VERSION ""

NS_ :

BS_:

BU_: VMCU TECU OBDScanT2 IC3 EMS ECUspare2 ECUspare1 DACU CIOM BBM

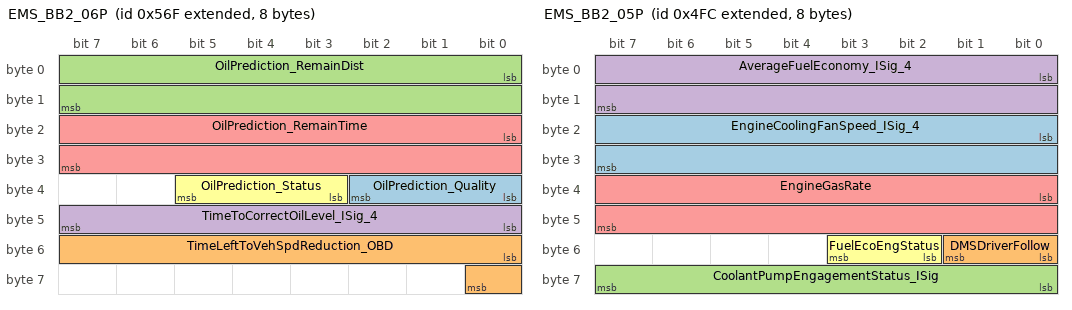
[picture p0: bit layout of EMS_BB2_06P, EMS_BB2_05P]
BO_ 2147485039 EMS_BB2_06P: 8 EMS
 SG_ OilPrediction_Quality : 32|3@1+ (1,0) [0|0] ""  CIOM,VMCU
 SG_ TimeLeftToVehSpdReduction_OBD : 48|9@1+ (15,0) [0|7665] "min"  IC3
 SG_ OilPrediction_RemainDist : 0|16@1+ (10,0) [0|655350] "km"  CIOM,VMCU
 SG_ TimeToCorrectOilLevel_ISig_4 : 40|8@1+ (1,0) [0|255] "min"  IC3
 SG_ OilPrediction_RemainTime : 16|16@1+ (1,0) [0|65535] "h"  VMCU,CIOM
 SG_ OilPrediction_Status : 35|3@1+ (1,0) [0|0] ""  CIOM,VMCU

BO_ 2147484924 EMS_BB2_05P: 8 EMS
 SG_ EngineCoolingFanSpeed_ISig_4 : 16|16@1+ (1,0) [0|65535] "rpm"  CIOM
 SG_ DMSDriverFollow : 48|2@1+ (1,0) [0|0] ""  VMCU
 SG_ CoolantPumpEngagementStatus_ISig : 56|8@1+ (0.4,0) [0|102] "Percent"  CIOM
 SG_ AverageFuelEconomy_ISig_4 : 0|16@1+ (0.00390625,0) [0|255.99609375] "miles_per_gallon"  IC3
 SG_ EngineGasRate : 32|16@1+ (0.05,0) [0|3276.75] "Kg_per_h"  VMCU,CIOM
 SG_ FuelEcoEngStatus : 50|2@1+ (1,0) [0|0] ""  VMCU

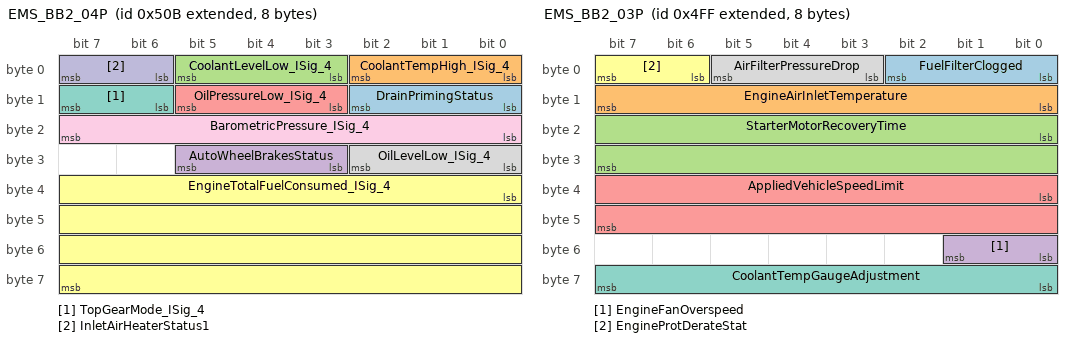
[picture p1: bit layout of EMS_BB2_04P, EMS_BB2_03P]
BO_ 2147484939 EMS_BB2_04P: 8 EMS
 SG_ DrainPrimingStatus : 8|3@1+ (1,0) [0|0] ""  IC3
 SG_ CoolantTempHigh_ISig_4 : 0|3@1+ (1,0) [0|0] ""  IC3,VMCU,BBM
 SG_ CoolantLevelLow_ISig_4 : 3|3@1+ (1,0) [0|0] ""  VMCU,BBM,IC3
 SG_ AutoWheelBrakesStatus : 27|3@1+ (1,0) [0|0] ""  IC3,TECU
 SG_ OilPressureLow_ISig_4 : 11|3@1+ (1,0) [0|0] ""  VMCU,IC3,BBM
 SG_ EngineTotalFuelConsumed_ISig_4 : 32|32@1+ (0.01,0) [0|42949672.95] "l"  IC3,BBM,CIOM,VMCU,TECU
 SG_ TopGearMode_ISig_4 : 14|2@1+ (1,0) [0|0] ""  IC3
 SG_ OilLevelLow_ISig_4 : 24|3@1+ (1,0) [0|0] ""  IC3,BBM
 SG_ BarometricPressure_ISig_4 : 16|8@1+ (0.5,0) [0|127.5] "kPa"  TECU,BBM,VMCU
 SG_ InletAirHeaterStatus1 : 6|2@1+ (1,0) [0|0] ""  IC3

BO_ 2147484927 EMS_BB2_03P: 8 EMS
 SG_ FuelFilterClogged : 0|3@1+ (1,0) [0|0] ""  IC3
 SG_ EngineAirInletTemperature : 8|8@1+ (1,-40) [-40|215] "DegreeC"  VMCU
 SG_ StarterMotorRecoveryTime : 16|16@1+ (1,0) [0|65535] "s"  IC3
 SG_ EngineFanOverspeed : 48|2@1+ (1,0) [0|0] ""  IC3
 SG_ AppliedVehicleSpeedLimit : 32|16@1+ (0.00390625,0) [0|255.99609375] "Km_per_h"  VMCU,TECU
 SG_ EngineProtDerateStat : 6|2@1+ (1,0) [0|0] ""  VMCU
 SG_ CoolantTempGaugeAdjustment : 56|8@1+ (0.4,0) [0|102] "Percent"  IC3
 SG_ AirFilterPressureDrop : 3|3@1+ (1,0) [0|0] ""  VMCU

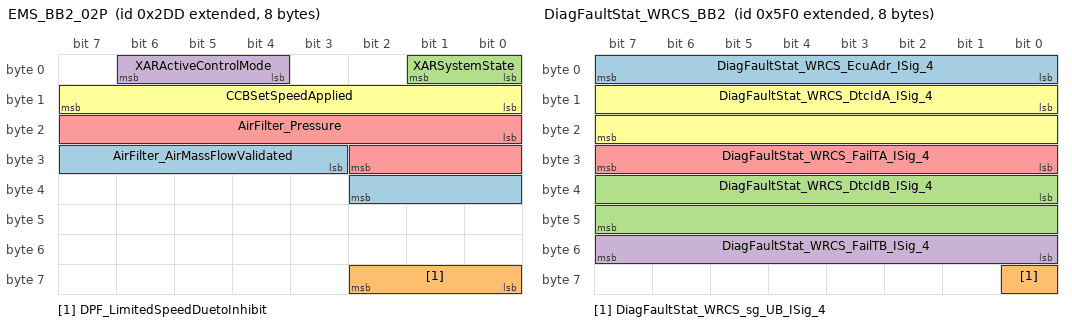
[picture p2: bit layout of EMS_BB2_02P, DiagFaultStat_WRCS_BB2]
BO_ 2147484381 EMS_BB2_02P: 8 EMS
 SG_ AirFilter_AirMassFlowValidated : 27|8@1+ (0.01,0) [0|2.55] "Kg_Per_s"  VMCU
 SG_ DPF_LimitedSpeedDuetoInhibit : 56|3@1+ (1,0) [0|0] ""  IC3
 SG_ XARSystemState : 0|2@1+ (1,0) [0|0] ""  DACU
 SG_ XARActiveControlMode : 4|3@1+ (1,0) [0|0] ""  DACU
 SG_ AirFilter_Pressure : 16|11@1+ (0.01,-10) [-10|10.47] "kPa"  VMCU
 SG_ CCBSetSpeedApplied : 8|8@1+ (1,0) [0|255] "Km_per_h"  VMCU,DACU

BO_ 2147484367 EMS_BB2_01P: 8 EMS
 SG_ CCControllerMode_ISig_4 : 0|3@1+ (1,0) [0|0] ""  VMCU,IC3
 SG_ CrankcasePressureHigh_ISig_4 : 30|2@1+ (1,0) [0|0] ""  BBM
 SG_ EngineSystemPowerDownAck : 28|2@1+ (1,0) [0|0] ""  VMCU
 SG_ EngineActiveStatus_ISig_4 : 24|4@1+ (1,0) [0|0] ""  TECU,VMCU
 SG_ XRSLControllerMode : 19|2@1+ (1,0) [0|0] ""  VMCU,IC3
 SG_ RegenInhibDueHeight : 60|2@1+ (1,0) [0|0] ""  IC3
 SG_ ExhManif_AirInjActive_ISig_4 : 56|2@1+ (1,0) [0|0] ""  VMCU
 SG_ CCBControllerMode : 11|3@1+ (1,0) [0|0] ""  VMCU
 SG_ InhibitIdleShutdownStatus : 8|3@1+ (1,0) [0|0] ""  VMCU
 SG_ EngCompartmentStopSwitchStat : 6|2@1+ (1,0) [0|0] ""  VMCU
 SG_ EngineAirInletPressure : 32|8@1+ (2,0) [0|510] "kPa"  VMCU
 SG_ EngineStartAuth_rqst : 3|3@1+ (1,0) [0|0] ""  CIOM
 SG_ IntakeAirTemperatureAlert : 14|2@1+ (1,0) [0|0] ""  VMCU
 SG_ EngineOilTempHigh_ISig_4 : 16|3@1+ (1,0) [0|0] ""  BBM,IC3
 SG_ WarmUpCycle : 21|2@1+ (1,0) [0|0] ""  VMCU
 SG_ DeterminedGear : 48|8@1+ (1,-125) [-125|130] "GearValue"  VMCU
 SG_ CCSetSpeedApplied_ISig_4 : 40|8@1+ (1,0) [0|255] "Km_per_h"  IC3,DACU,VMCU

BO_ 2671964902 DiagUUDTRespMsg1_F2_E6_BB2: 8 BBM
 SG_ DiagUUDTRespSig_F2_E6_ISig_4 : 0|64@1+ (1,0) [0|0] ""  VMCU

BO_ 2671964901 DiagUUDTRespMsg1_F2_E5_BB2: 8 BBM
 SG_ DiagUUDTRespSig_F2_E5_ISig_4 : 0|64@1+ (1,0) [0|0] ""  VMCU

BO_ 2671964864 DiagUUDTRespMsg1_F2_C0_BB2: 8 CIOM
 SG_ DiagUUDTRespSig_F2_C0_ISig_4 : 0|64@1+ (1,0) [0|0] ""  VMCU

BO_ 2671964834 DiagUUDTRespMsg1_F2_A2_BB2: 8 CIOM
 SG_ DiagUUDTRespSig_F2_A2_ISig_4 : 0|64@1+ (1,0) [0|0] ""  VMCU

BO_ 2671964833 DiagUUDTRespMsg1_F2_A1_BB2: 8 CIOM
 SG_ DiagUUDTRespSig_F2_A1_ISig_4 : 0|64@1+ (1,0) [0|0] ""  VMCU

BO_ 2671964832 DiagUUDTRespMsg1_F2_A0_BB2: 8 CIOM
 SG_ DiagUUDTRespSig_F2_A0_ISig_4 : 0|64@1+ (1,0) [0|0] ""  VMCU

BO_ 2671964824 DiagUUDTRespMsg1_F2_98_BB2: 8 CIOM
 SG_ DiagUUDTRespSig_F2_98_ISig_4 : 0|64@1+ (1,0) [0|0] ""  VMCU

BO_ 2671964803 DiagUUDTRespMsg1_F2_83_BB2: 8 IC3
 SG_ DiagUUDTRespSig_F2_83_ISig_4 : 0|64@1+ (1,0) [0|0] ""  VMCU

BO_ 2671964802 DiagUUDTRespMsg1_F2_82_BB2: 8 IC3
 SG_ DiagUUDTRespSig_F2_82_ISig_4 : 0|64@1+ (1,0) [0|0] ""  VMCU

BO_ 2671964772 DiagUUDTRespMsg1_F2_64_BB2: 8 IC3
 SG_ DiagUUDTRespSig_F2_64_ISig_4 : 0|64@1+ (1,0) [0|0] ""  VMCU

BO_ 2671964769 DiagUUDTRespMsg1_F2_61_BB2: 8 IC3
 SG_ DiagUUDTRespSig_F2_61_ISig_4 : 0|64@1+ (1,0) [0|0] ""  VMCU

BO_ 2671964768 DiagUUDTRespMsg1_F2_60_BB2: 8 IC3
 SG_ DiagUUDTRespSig_F2_60_ISig_4 : 0|64@1+ (1,0) [0|0] ""  VMCU

BO_ 2671964755 DiagUUDTRespMsg1_F2_53_BB2: 8 CIOM
 SG_ DiagUUDTRespSig_F2_53_ISig_4 : 0|64@1+ (1,0) [0|0] ""  VMCU

BO_ 2671964754 DiagUUDTRespMsg1_F2_52_BB2: 8 DACU
 SG_ DiagUUDTRespSig_F2_52_ISig_4 : 0|64@1+ (1,0) [0|0] ""  VMCU

BO_ 2671964753 DiagUUDTRespMsg1_F2_51_BB2: 8 DACU
 SG_ DiagUUDTRespSig_F2_51_ISig_4 : 0|64@1+ (1,0) [0|0] ""  VMCU

BO_ 2671964752 DiagUUDTRespMsg1_F2_50_BB2: 8 DACU
 SG_ DiagUUDTRespSig_F2_50_ISig_4 : 0|64@1+ (1,0) [0|0] ""  VMCU

BO_ 2671964737 DiagUUDTRespMsg1_F2_41_BB2: 8 IC3
 SG_ DiagUUDTRespSig_F2_41_ISig_4 : 0|64@1+ (1,0) [0|0] ""  VMCU

BO_ 2671964736 DiagUUDTRespMsg1_F2_40_BB2: 8 CIOM
 SG_ DiagUUDTRespSig_F2_40_ISig_4 : 0|64@1+ (1,0) [0|0] ""  VMCU

BO_ 2671964710 DiagUUDTRespMsg1_F2_26_BB2: 8 CIOM
 SG_ DiagUUDTRespSig_F2_26_ISig_4 : 0|64@1+ (1,0) [0|0] ""  VMCU

BO_ 2671964696 DiagUUDTRespMsg1_F2_18_BB2: 8 TECU
 SG_ DiagUUDTRespSig_F2_18_ISig_4 : 0|64@1+ (1,0) [0|0] ""  VMCU

BO_ 2671964688 DiagUUDTRespMsg1_F2_10_BB2: 8 EMS
 SG_ DiagUUDTRespSig_F2_10_ISig_4 : 0|64@1+ (1,0) [0|0] ""  VMCU

BO_ 2671834342 DiagRespMsgIntTGW2_F4_E6_BB2: 8 BBM
 SG_ InternalTesterDiagSig_F4_E6_ISig : 0|64@1+ (1,0) [0|0] ""  IC3

BO_ 2671834341 DiagRespMsgIntTGW2_F4_E5_BB2: 8 BBM
 SG_ InternalTesterDiagSig_F4_E5_ISig : 0|64@1+ (1,0) [0|0] ""  IC3

BO_ 2671834304 DiagRespMsgIntTGW2_F4_C0_BB2: 8 CIOM
 SG_ InternalTesterDiagSig_F4_C0_ISig : 0|64@1+ (1,0) [0|0] ""  IC3

BO_ 2671834274 DiagRespMsgIntTGW2_F4_A2_BB2: 8 CIOM
 SG_ InternalTesterDiagSig_F4_A2_ISig : 0|64@1+ (1,0) [0|0] ""  IC3

BO_ 2671834273 DiagRespMsgIntTGW2_F4_A1_BB2: 8 CIOM
 SG_ InternalTesterDiagSig_F4_A1_ISig : 0|64@1+ (1,0) [0|0] ""  IC3

BO_ 2671834272 DiagRespMsgIntTGW2_F4_A0_BB2: 8 CIOM
 SG_ InternalTesterDiagSig_F4_A0_ISig : 0|64@1+ (1,0) [0|0] ""  IC3

BO_ 2671834264 DiagRespMsgIntTGW2_F4_98_BB2: 8 CIOM
 SG_ InternalTesterDiagSig_F4_98_ISig : 0|64@1+ (1,0) [0|0] ""  IC3

BO_ 2671834226 DiagRespMsgIntTGW2_F4_72_BB2: 8 VMCU
 SG_ InternalTesterDiagSig_F4_72_ISig : 0|64@1+ (1,0) [0|0] ""  IC3

BO_ 2671834225 DiagRespMsgIntTGW2_F4_71_BB2: 8 VMCU
 SG_ InternalTesterDiagSig_F4_71_ISig : 0|64@1+ (1,0) [0|0] ""  IC3

BO_ 2671834195 DiagRespMsgIntTGW2_F4_53_BB2: 8 CIOM
 SG_ InternalTesterDiagSig_F4_53_ISig : 0|64@1+ (1,0) [0|0] ""  IC3

BO_ 2671834194 DiagRespMsgIntTGW2_F4_52_BB2: 8 DACU
 SG_ InternalTesterDiagSig_F4_52_ISig : 0|64@1+ (1,0) [0|0] ""  IC3

BO_ 2671834193 DiagRespMsgIntTGW2_F4_51_BB2: 8 DACU
 SG_ InternalTesterDiagSig_F4_51_ISig : 0|64@1+ (1,0) [0|0] ""  IC3

BO_ 2671834192 DiagRespMsgIntTGW2_F4_50_BB2: 8 DACU
 SG_ InternalTesterDiagSig_F4_50_ISig : 0|64@1+ (1,0) [0|0] ""  IC3

BO_ 2671834176 DiagRespMsgIntTGW2_F4_40_BB2: 8 CIOM
 SG_ InternalTesterDiagSig_F4_40_ISig : 0|64@1+ (1,0) [0|0] ""  IC3

BO_ 2671834161 DiagRespMsgIntTGW2_F4_31_BB2: 8 VMCU
 SG_ InternalTesterDiagSig_F4_31_ISig : 0|64@1+ (1,0) [0|0] ""  IC3

BO_ 2671834160 DiagRespMsgIntTGW2_F4_30_BB2: 8 VMCU
 SG_ InternalTesterDiagSig_F4_30_ISig : 0|64@1+ (1,0) [0|0] ""  IC3

BO_ 2671834150 DiagRespMsgIntTGW2_F4_26_BB2: 8 CIOM
 SG_ InternalTesterDiagSig_F4_26_ISig : 0|64@1+ (1,0) [0|0] ""  IC3

BO_ 2671834149 DiagRespMsgIntTGW2_F4_25_BB2: 8 VMCU
 SG_ InternalTesterDiagSig_F4_25_ISig : 0|64@1+ (1,0) [0|0] ""  IC3

BO_ 2671834148 DiagRespMsgIntTGW2_F4_24_BB2: 8 VMCU
 SG_ InternalTesterDiagSig_F4_24_ISig : 0|64@1+ (1,0) [0|0] ""  IC3

BO_ 2671834147 DiagRespMsgIntTGW2_F4_23_BB2: 8 VMCU
 SG_ InternalTesterDiagSig_F4_23_ISig : 0|64@1+ (1,0) [0|0] ""  IC3

BO_ 2671834146 DiagRespMsgIntTGW2_F4_22_BB2: 8 VMCU
 SG_ InternalTesterDiagSig_F4_22_ISig : 0|64@1+ (1,0) [0|0] ""  IC3

BO_ 2671834145 DiagRespMsgIntTGW2_F4_21_BB2: 8 VMCU
 SG_ InternalTesterDiagSig_F4_21_ISig : 0|64@1+ (1,0) [0|0] ""  IC3

BO_ 2671834144 DiagRespMsgIntTGW2_F4_20_BB2: 8 VMCU
 SG_ InternalTesterDiagSig_F4_20_ISig : 0|64@1+ (1,0) [0|0] ""  IC3

BO_ 2671834138 DiagRespMsgIntTGW2_F4_1A_BB2: 8 VMCU
 SG_ InternalTesterDiagSig_F4_1A_ISig : 0|64@1+ (1,0) [0|0] ""  IC3

BO_ 2671834136 DiagRespMsgIntTGW2_F4_18_BB2: 8 TECU
 SG_ InternalTesterDiagSig_F4_18_ISig : 0|64@1+ (1,0) [0|0] ""  IC3

BO_ 2671834128 DiagRespMsgIntTGW2_F4_10_BB2: 8 EMS
 SG_ InternalTesterDiagSig_F4_10_ISig : 0|64@1+ (1,0) [0|0] ""  IC3

BO_ 2671834086 DiagRespMsgIntHMIIOM_F3_E6_BB2: 8 BBM
 SG_ InternalTesterDiagSig_F3_E6 : 0|64@1+ (1,0) [0|0] ""  IC3

BO_ 2671834085 DiagRespMsgIntHMIIOM_F3_E5_BB2: 8 BBM
 SG_ InternalTesterDiagSig_F3_E5_ISig : 0|64@1+ (1,0) [0|0] ""  IC3

BO_ 2671834048 DiagRespMsgIntHMIIOM_F3_C0_BB2: 8 CIOM
 SG_ InternalTesterDiagSig_F3_C0_ISig : 0|64@1+ (1,0) [0|0] ""  IC3

BO_ 2671834018 DiagRespMsgIntHMIIOM_F3_A2_BB2: 8 CIOM
 SG_ InternalTesterDiagSig_F3_A2_ISig : 0|64@1+ (1,0) [0|0] ""  IC3

BO_ 2671834017 DiagRespMsgIntHMIIOM_F3_A1_BB2: 8 CIOM
 SG_ InternalTesterDiagSig_F3_A1_ISig : 0|64@1+ (1,0) [0|0] ""  IC3

BO_ 2671834016 DiagRespMsgIntHMIIOM_F3_A0_BB2: 8 CIOM
 SG_ InternalTesterDiagSig_F3_A0_ISig : 0|64@1+ (1,0) [0|0] ""  IC3

BO_ 2671834008 DiagRespMsgIntHMIIOM_F3_98_BB2: 8 CIOM
 SG_ InternalTesterDiagSig_F3_98_ISig : 0|64@1+ (1,0) [0|0] ""  IC3

BO_ 2671833970 DiagRespMsgIntHMIIOM_F3_72_BB2: 8 VMCU
 SG_ InternalTesterDiagSig_F3_72_ISig : 0|64@1+ (1,0) [0|0] ""  IC3

BO_ 2671833969 DiagRespMsgIntHMIIOM_F3_71_BB2: 8 VMCU
 SG_ InternalTesterDiagSig_F3_71_ISig : 0|64@1+ (1,0) [0|0] ""  IC3

BO_ 2671833939 DiagRespMsgIntHMIIOM_F3_53_BB2: 8 CIOM
 SG_ InternalTesterDiagSig_F3_53_ISig : 0|64@1+ (1,0) [0|0] ""  IC3

BO_ 2671833938 DiagRespMsgIntHMIIOM_F3_52_BB2: 8 DACU
 SG_ InternalTesterDiagSig_F3_52_ISig : 0|64@1+ (1,0) [0|0] ""  IC3

BO_ 2671833937 DiagRespMsgIntHMIIOM_F3_51_BB2: 8 DACU
 SG_ InternalTesterDiagSig_F3_51_ISig : 0|64@1+ (1,0) [0|0] ""  IC3

BO_ 2671833936 DiagRespMsgIntHMIIOM_F3_50_BB2: 8 DACU
 SG_ InternalTesterDiagSig_F3_50 : 0|64@1+ (1,0) [0|0] ""  IC3

BO_ 2671833920 DiagRespMsgIntHMIIOM_F3_40_BB2: 8 CIOM
 SG_ InternalTesterDiagSig_F3_40 : 0|64@1+ (1,0) [0|0] ""  IC3

BO_ 2671833905 DiagRespMsgIntHMIIOM_F3_31_BB2: 8 VMCU
 SG_ InternalTesterDiagSig_F3_31_ISig : 0|64@1+ (1,0) [0|0] ""  IC3

BO_ 2671833904 DiagRespMsgIntHMIIOM_F3_30_BB2: 8 VMCU
 SG_ InternalTesterDiagSig_F3_30_ISig : 0|64@1+ (1,0) [0|0] ""  IC3

BO_ 2671833894 DiagRespMsgIntHMIIOM_F3_26_BB2: 8 CIOM
 SG_ InternalTesterDiagSig_F3_26_ISig : 0|64@1+ (1,0) [0|0] ""  IC3

BO_ 2671833893 DiagRespMsgIntHMIIOM_F3_25_BB2: 8 VMCU
 SG_ InternalTesterDiagSig_F3_25_ISig : 0|64@1+ (1,0) [0|0] ""  IC3

BO_ 2671833892 DiagRespMsgIntHMIIOM_F3_24_BB2: 8 VMCU
 SG_ InternalTesterDiagSig_F3_24 : 0|64@1+ (1,0) [0|0] ""  IC3

BO_ 2671833891 DiagRespMsgIntHMIIOM_F3_23_BB2: 8 VMCU
 SG_ InternalTesterDiagSig_F3_23_ISig : 0|64@1+ (1,0) [0|0] ""  IC3

BO_ 2671833890 DiagRespMsgIntHMIIOM_F3_22_BB2: 8 VMCU
 SG_ InternalTesterDiagSig_F3_22_ISig : 0|64@1+ (1,0) [0|0] ""  IC3

BO_ 2671833889 DiagRespMsgIntHMIIOM_F3_21_BB2: 8 VMCU
 SG_ InternalTesterDiagSig_F3_21_ISig : 0|64@1+ (1,0) [0|0] ""  IC3

BO_ 2671833888 DiagRespMsgIntHMIIOM_F3_20_BB2: 8 VMCU
 SG_ InternalTesterDiagSig_F3_20_ISig : 0|64@1+ (1,0) [0|0] ""  IC3

BO_ 2671833882 DiagRespMsgIntHMIIOM_F3_1A_BB2: 8 VMCU
 SG_ InternalTesterDiagSig_F3_1A_ISig : 0|64@1+ (1,0) [0|0] ""  IC3

BO_ 2671833880 DiagRespMsgIntHMIIOM_F3_18_BB2: 8 TECU
 SG_ InternalTesterDiagSig_F3_18 : 0|64@1+ (1,0) [0|0] ""  IC3

BO_ 2671833872 DiagRespMsgIntHMIIOM_F3_10_BB2: 8 EMS
 SG_ InternalTesterDiagSig_F3_10 : 0|64@1+ (1,0) [0|0] ""  IC3

BO_ 2671830772 DiagReqMsgIntTGW2_E6_F4_BB2: 8 IC3
 SG_ InternalTesterDiagSig_E6_F4_ISig : 0|64@1+ (1,0) [0|0] ""  BBM

BO_ 2671830516 DiagReqMsgIntTGW2_E5_F4_BB2: 8 IC3
 SG_ InternalTesterDiagSig_E5_F4_ISig : 0|64@1+ (1,0) [0|0] ""  BBM

BO_ 2671821044 DiagReqMsgIntTGW2_C0_F4_BB2: 8 IC3
 SG_ InternalTesterDiagSig_C0_F4_ISig : 0|64@1+ (1,0) [0|0] ""  CIOM

BO_ 2671813364 DiagReqMsgIntTGW2_A2_F4_BB2: 8 IC3
 SG_ InternalTesterDiagSig_A2_F4_ISig : 0|64@1+ (1,0) [0|0] ""  CIOM

BO_ 2671813108 DiagReqMsgIntTGW2_A1_F4_BB2: 8 IC3
 SG_ InternalTesterDiagSig_A1_F4_ISig : 0|64@1+ (1,0) [0|0] ""  CIOM

BO_ 2671812852 DiagReqMsgIntTGW2_A0_F4_BB2: 8 IC3
 SG_ InternalTesterDiagSig_A0_F4_ISig : 0|64@1+ (1,0) [0|0] ""  CIOM

BO_ 2671810804 DiagReqMsgIntTGW2_98_F4_BB2: 8 IC3
 SG_ InternalTesterDiagSig_98_F4_ISig : 0|64@1+ (1,0) [0|0] ""  CIOM

BO_ 2671801076 DiagReqMsgIntTGW2_72_F4_BB2: 8 IC3
 SG_ InternalTesterDiagSig_72_F4_ISig : 0|64@1+ (1,0) [0|0] ""  VMCU

BO_ 2671800820 DiagReqMsgIntTGW2_71_F4_BB2: 8 IC3
 SG_ InternalTesterDiagSig_71_F4_ISig : 0|64@1+ (1,0) [0|0] ""  VMCU

BO_ 2671793140 DiagReqMsgIntTGW2_53_F4_BB2: 8 IC3
 SG_ InternalTesterDiagSig_53_F4_ISig : 0|64@1+ (1,0) [0|0] ""  CIOM

BO_ 2671792884 DiagReqMsgIntTGW2_52_F4_BB2: 8 IC3
 SG_ InternalTesterDiagSig_52_F4_ISig : 0|64@1+ (1,0) [0|0] ""  DACU

BO_ 2671792628 DiagReqMsgIntTGW2_51_F4_BB2: 8 IC3
 SG_ InternalTesterDiagSig_51_F4_ISig : 0|64@1+ (1,0) [0|0] ""  DACU

BO_ 2671792372 DiagReqMsgIntTGW2_50_F4_BB2: 8 IC3
 SG_ InternalTesterDiagSig_50_F4_ISig : 0|64@1+ (1,0) [0|0] ""  DACU

BO_ 2671788276 DiagReqMsgIntTGW2_40_F4_BB2: 8 IC3
 SG_ InternalTesterDiagSig_40_F4_ISig : 0|64@1+ (1,0) [0|0] ""  CIOM

BO_ 2671784436 DiagReqMsgIntTGW2_31_F4_BB2: 8 IC3
 SG_ InternalTesterDiagSig_31_F4_ISig : 0|64@1+ (1,0) [0|0] ""  VMCU

BO_ 2671784180 DiagReqMsgIntTGW2_30_F4_BB2: 8 IC3
 SG_ InternalTesterDiagSig_30_F4_ISig : 0|64@1+ (1,0) [0|0] ""  VMCU

BO_ 2671781620 DiagReqMsgIntTGW2_26_F4_BB2: 8 IC3
 SG_ InternalTesterDiagSig_26_F4_ISig : 0|64@1+ (1,0) [0|0] ""  CIOM

BO_ 2671781364 DiagReqMsgIntTGW2_25_F4_BB2: 8 IC3
 SG_ InternalTesterDiagSig_25_F4_ISig : 0|64@1+ (1,0) [0|0] ""  VMCU

BO_ 2671781108 DiagReqMsgIntTGW2_24_F4_BB2: 8 IC3
 SG_ InternalTesterDiagSig_24_F4_ISig : 0|64@1+ (1,0) [0|0] ""  VMCU

BO_ 2671780852 DiagReqMsgIntTGW2_23_F4_BB2: 8 IC3
 SG_ InternalTesterDiagSig_23_F4_ISig : 0|64@1+ (1,0) [0|0] ""  VMCU

BO_ 2671780596 DiagReqMsgIntTGW2_22_F4_BB2: 8 IC3
 SG_ InternalTesterDiagSig_22_F4_ISig : 0|64@1+ (1,0) [0|0] ""  VMCU

BO_ 2671780340 DiagReqMsgIntTGW2_21_F4_BB2: 8 IC3
 SG_ InternalTesterDiagSig_21_F4_ISig : 0|64@1+ (1,0) [0|0] ""  VMCU

BO_ 2671780084 DiagReqMsgIntTGW2_20_F4_BB2: 8 IC3
 SG_ InternalTesterDiagSig_20_F4_ISig : 0|64@1+ (1,0) [0|0] ""  VMCU

BO_ 2671778548 DiagReqMsgIntTGW2_1A_F4_BB2: 8 IC3
 SG_ InternalTesterDiagSig_1A_F4_ISig : 0|64@1+ (1,0) [0|0] ""  VMCU

BO_ 2671778036 DiagReqMsgIntTGW2_18_F4_BB2: 8 IC3
 SG_ InternalTesterDiagSig_18_F4_ISig : 0|64@1+ (1,0) [0|0] ""  TECU

BO_ 2671775988 DiagReqMsgIntTGW2_10_F4_BB2: 8 IC3
 SG_ InternalTesterDiagSig_10_F4_ISig : 0|64@1+ (1,0) [0|0] ""  EMS

BO_ 2671830771 DiagReqMsgIntHMIIOM_E6_F3_BB2: 8 IC3
 SG_ InternalTesterDiagSig_E6_F3 : 0|64@1+ (1,0) [0|0] ""  BBM

BO_ 2671830515 DiagReqMsgIntHMIIOM_E5_F3_BB2: 8 IC3
 SG_ InternalTesterDiagSig_E5_F3_ISig : 0|64@1+ (1,0) [0|0] ""  BBM

BO_ 2671821043 DiagReqMsgIntHMIIOM_C0_F3_BB2: 8 IC3
 SG_ InternalTesterDiagSig_C0_F3_ISig : 0|64@1+ (1,0) [0|0] ""  CIOM

BO_ 2671813363 DiagReqMsgIntHMIIOM_A2_F3_BB2: 8 IC3
 SG_ InternalTesterDiagSig_A2_F3_ISig : 0|64@1+ (1,0) [0|0] ""  CIOM

BO_ 2671813107 DiagReqMsgIntHMIIOM_A1_F3_BB2: 8 IC3
 SG_ InternalTesterDiagSig_A1_F3_ISig : 0|64@1+ (1,0) [0|0] ""  CIOM

BO_ 2671812851 DiagReqMsgIntHMIIOM_A0_F3_BB2: 8 IC3
 SG_ InternalTesterDiagSig_A0_F3_ISig : 0|64@1+ (1,0) [0|0] ""  CIOM

BO_ 2671810803 DiagReqMsgIntHMIIOM_98_F3_BB2: 8 IC3
 SG_ InternalTesterDiagSig_98_F3_ISig : 0|64@1+ (1,0) [0|0] ""  CIOM

BO_ 2671801075 DiagReqMsgIntHMIIOM_72_F3_BB2: 8 IC3
 SG_ InternalTesterDiagSig_72_F3_ISig : 0|64@1+ (1,0) [0|0] ""  VMCU

BO_ 2671800819 DiagReqMsgIntHMIIOM_71_F3_BB2: 8 IC3
 SG_ InternalTesterDiagSig_71_F3_ISig : 0|64@1+ (1,0) [0|0] ""  VMCU

BO_ 2671793139 DiagReqMsgIntHMIIOM_53_F3_BB2: 8 IC3
 SG_ InternalTesterDiagSig_53_F3_ISig : 0|64@1+ (1,0) [0|0] ""  CIOM

BO_ 2671792883 DiagReqMsgIntHMIIOM_52_F3_BB2: 8 IC3
 SG_ InternalTesterDiagSig_52_F3_ISig : 0|64@1+ (1,0) [0|0] ""  DACU

BO_ 2671792627 DiagReqMsgIntHMIIOM_51_F3_BB2: 8 IC3
 SG_ InternalTesterDiagSig_51_F3_ISig : 0|64@1+ (1,0) [0|0] ""  DACU

BO_ 2671792371 DiagReqMsgIntHMIIOM_50_F3_BB2: 8 IC3
 SG_ InternalTesterDiagSig_50_F3 : 0|64@1+ (1,0) [0|0] ""  DACU

BO_ 2671788275 DiagReqMsgIntHMIIOM_40_F3_BB2: 8 IC3
 SG_ InternalTesterDiagSig_40_F3 : 0|64@1+ (1,0) [0|0] ""  CIOM

BO_ 2671784435 DiagReqMsgIntHMIIOM_31_F3_BB2: 8 IC3
 SG_ InternalTesterDiagSig_31_F3_ISig : 0|64@1+ (1,0) [0|0] ""  VMCU

BO_ 2671784179 DiagReqMsgIntHMIIOM_30_F3_BB2: 8 IC3
 SG_ InternalTesterDiagSig_30_F3_ISig : 0|64@1+ (1,0) [0|0] ""  VMCU

BO_ 2671781619 DiagReqMsgIntHMIIOM_26_F3_BB2: 8 IC3
 SG_ InternalTesterDiagSig_26_F3_ISig : 0|64@1+ (1,0) [0|0] ""  CIOM

BO_ 2671781363 DiagReqMsgIntHMIIOM_25_F3_BB2: 8 IC3
 SG_ InternalTesterDiagSig_25_F3_ISig : 0|64@1+ (1,0) [0|0] ""  VMCU

BO_ 2671781107 DiagReqMsgIntHMIIOM_24_F3_BB2: 8 IC3
 SG_ InternalTesterDiagSig_24_F3 : 0|64@1+ (1,0) [0|0] ""  VMCU

BO_ 2671780851 DiagReqMsgIntHMIIOM_23_F3_BB2: 8 IC3
 SG_ InternalTesterDiagSig_23_F3_ISig : 0|64@1+ (1,0) [0|0] ""  VMCU

BO_ 2671780595 DiagReqMsgIntHMIIOM_22_F3_BB2: 8 IC3
 SG_ InternalTesterDiagSig_22_F3_ISig : 0|64@1+ (1,0) [0|0] ""  VMCU

BO_ 2671780339 DiagReqMsgIntHMIIOM_21_F3_BB2: 8 IC3
 SG_ InternalTesterDiagSig_21_F3_ISig : 0|64@1+ (1,0) [0|0] ""  VMCU

BO_ 2671780083 DiagReqMsgIntHMIIOM_20_F3_BB2: 8 IC3
 SG_ InternalTesterDiagSig_20_F3_ISig : 0|64@1+ (1,0) [0|0] ""  VMCU

BO_ 2671778547 DiagReqMsgIntHMIIOM_1A_F3_BB2: 8 IC3
 SG_ InternalTesterDiagSig_1A_F3_ISig : 0|64@1+ (1,0) [0|0] ""  VMCU

BO_ 2671778035 DiagReqMsgIntHMIIOM_18_F3_BB2: 8 IC3
 SG_ InternalTesterDiagSig_18_F3 : 0|64@1+ (1,0) [0|0] ""  TECU

BO_ 2671775987 DiagReqMsgIntHMIIOM_10_F3_BB2: 8 IC3
 SG_ InternalTesterDiagSig_10_F3 : 0|64@1+ (1,0) [0|0] ""  EMS

BO_ 2147485168 DiagFaultStat_WRCS_BB2: 8 CIOM
 SG_ DiagFaultStat_WRCS_EcuAdr_ISig_4 : 0|8@1+ (1,0) [0|255] ""  IC3
 SG_ DiagFaultStat_WRCS_sg_UB_ISig_4 : 56|1@1+ (1,0) [0|0] ""  IC3
 SG_ DiagFaultStat_WRCS_DtcIdB_ISig_4 : 32|16@1+ (1,0) [0|65535] ""  IC3
 SG_ DiagFaultStat_WRCS_FailTB_ISig_4 : 48|8@1+ (1,0) [0|255] ""  IC3
 SG_ DiagFaultStat_WRCS_FailTA_ISig_4 : 24|8@1+ (1,0) [0|255] ""  IC3
 SG_ DiagFaultStat_WRCS_DtcIdA_ISig_4 : 8|16@1+ (1,0) [0|65535] ""  IC3

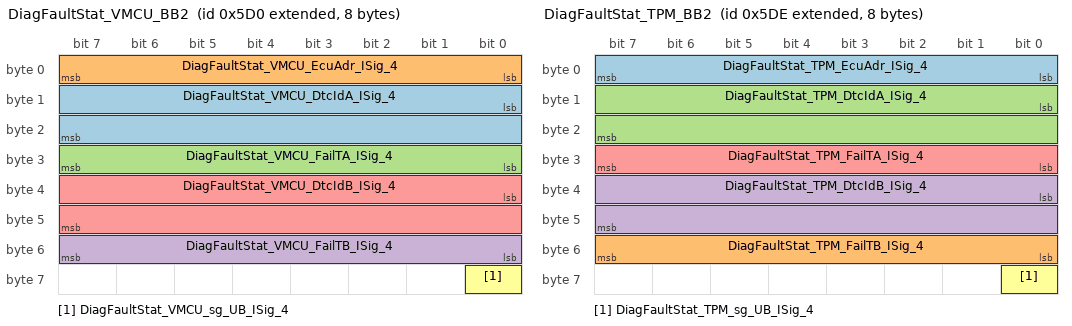
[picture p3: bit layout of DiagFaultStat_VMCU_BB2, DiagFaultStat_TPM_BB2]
BO_ 2147485136 DiagFaultStat_VMCU_BB2: 8 VMCU
 SG_ DiagFaultStat_VMCU_DtcIdA_ISig_4 : 8|16@1+ (1,0) [0|65535] ""  IC3
 SG_ DiagFaultStat_VMCU_EcuAdr_ISig_4 : 0|8@1+ (1,0) [0|255] ""  IC3
 SG_ DiagFaultStat_VMCU_FailTA_ISig_4 : 24|8@1+ (1,0) [0|255] ""  IC3
 SG_ DiagFaultStat_VMCU_FailTB_ISig_4 : 48|8@1+ (1,0) [0|255] ""  IC3
 SG_ DiagFaultStat_VMCU_DtcIdB_ISig_4 : 32|16@1+ (1,0) [0|65535] ""  IC3
 SG_ DiagFaultStat_VMCU_sg_UB_ISig_4 : 56|1@1+ (1,0) [0|0] ""  IC3

BO_ 2147485150 DiagFaultStat_TPM_BB2: 8 VMCU
 SG_ DiagFaultStat_TPM_EcuAdr_ISig_4 : 0|8@1+ (1,0) [0|255] ""  IC3
 SG_ DiagFaultStat_TPM_FailTB_ISig_4 : 48|8@1+ (1,0) [0|255] ""  IC3
 SG_ DiagFaultStat_TPM_DtcIdA_ISig_4 : 8|16@1+ (1,0) [0|65535] ""  IC3
 SG_ DiagFaultStat_TPM_DtcIdB_ISig_4 : 32|16@1+ (1,0) [0|65535] ""  IC3
 SG_ DiagFaultStat_TPM_FailTA_ISig_4 : 24|8@1+ (1,0) [0|255] ""  IC3
 SG_ DiagFaultStat_TPM_sg_UB_ISig_4 : 56|1@1+ (1,0) [0|0] ""  IC3

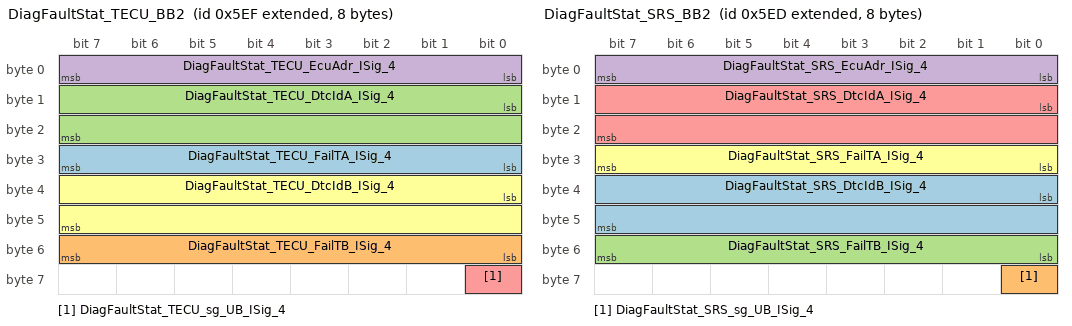
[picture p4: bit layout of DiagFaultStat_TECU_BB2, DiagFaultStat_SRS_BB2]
BO_ 2147485167 DiagFaultStat_TECU_BB2: 8 TECU
 SG_ DiagFaultStat_TECU_FailTA_ISig_4 : 24|8@1+ (1,0) [0|255] ""  IC3
 SG_ DiagFaultStat_TECU_FailTB_ISig_4 : 48|8@1+ (1,0) [0|255] ""  IC3
 SG_ DiagFaultStat_TECU_DtcIdA_ISig_4 : 8|16@1+ (1,0) [0|65535] ""  IC3
 SG_ DiagFaultStat_TECU_EcuAdr_ISig_4 : 0|8@1+ (1,0) [0|255] ""  IC3
 SG_ DiagFaultStat_TECU_sg_UB_ISig_4 : 56|1@1+ (1,0) [0|0] ""  IC3
 SG_ DiagFaultStat_TECU_DtcIdB_ISig_4 : 32|16@1+ (1,0) [0|65535] ""  IC3

BO_ 2147485165 DiagFaultStat_SRS_BB2: 8 CIOM
 SG_ DiagFaultStat_SRS_DtcIdB_ISig_4 : 32|16@1+ (1,0) [0|65535] ""  IC3
 SG_ DiagFaultStat_SRS_sg_UB_ISig_4 : 56|1@1+ (1,0) [0|0] ""  IC3
 SG_ DiagFaultStat_SRS_FailTB_ISig_4 : 48|8@1+ (1,0) [0|255] ""  IC3
 SG_ DiagFaultStat_SRS_EcuAdr_ISig_4 : 0|8@1+ (1,0) [0|255] ""  IC3
 SG_ DiagFaultStat_SRS_DtcIdA_ISig_4 : 8|16@1+ (1,0) [0|65535] ""  IC3
 SG_ DiagFaultStat_SRS_FailTA_ISig_4 : 24|8@1+ (1,0) [0|255] ""  IC3

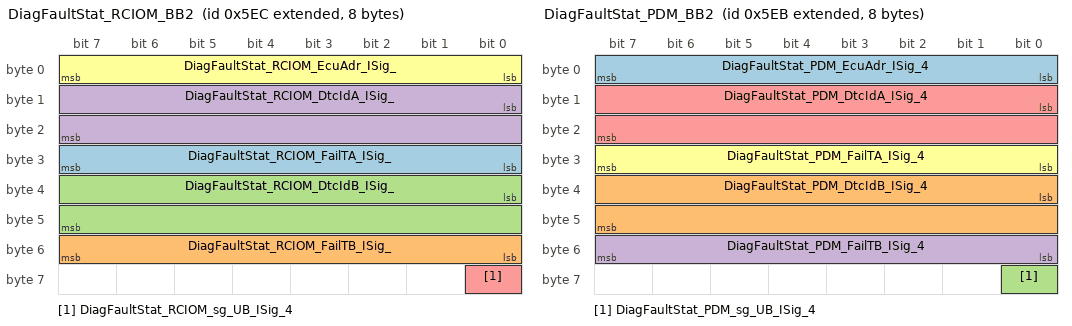
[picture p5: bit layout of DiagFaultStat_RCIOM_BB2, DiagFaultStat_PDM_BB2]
BO_ 2147485164 DiagFaultStat_RCIOM_BB2: 8 VMCU
 SG_ DiagFaultStat_RCIOM_FailTA_ISig_ : 24|8@1+ (1,0) [0|255] ""  IC3
 SG_ DiagFaultStat_RCIOM_FailTB_ISig_ : 48|8@1+ (1,0) [0|255] ""  IC3
 SG_ DiagFaultStat_RCIOM_DtcIdB_ISig_ : 32|16@1+ (1,0) [0|65535] ""  IC3
 SG_ DiagFaultStat_RCIOM_DtcIdA_ISig_ : 8|16@1+ (1,0) [0|65535] ""  IC3
 SG_ DiagFaultStat_RCIOM_sg_UB_ISig_4 : 56|1@1+ (1,0) [0|0] ""  IC3
 SG_ DiagFaultStat_RCIOM_EcuAdr_ISig_ : 0|8@1+ (1,0) [0|255] ""  IC3

BO_ 2147485163 DiagFaultStat_PDM_BB2: 8 CIOM
 SG_ DiagFaultStat_PDM_EcuAdr_ISig_4 : 0|8@1+ (1,0) [0|255] ""  IC3
 SG_ DiagFaultStat_PDM_DtcIdB_ISig_4 : 32|16@1+ (1,0) [0|65535] ""  IC3
 SG_ DiagFaultStat_PDM_sg_UB_ISig_4 : 56|1@1+ (1,0) [0|0] ""  IC3
 SG_ DiagFaultStat_PDM_FailTB_ISig_4 : 48|8@1+ (1,0) [0|255] ""  IC3
 SG_ DiagFaultStat_PDM_DtcIdA_ISig_4 : 8|16@1+ (1,0) [0|65535] ""  IC3
 SG_ DiagFaultStat_PDM_FailTA_ISig_4 : 24|8@1+ (1,0) [0|255] ""  IC3

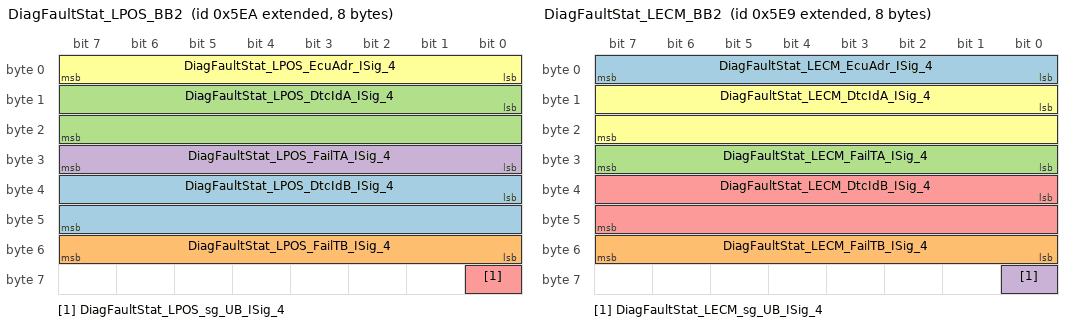
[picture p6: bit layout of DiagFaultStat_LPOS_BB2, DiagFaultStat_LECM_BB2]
BO_ 2147485162 DiagFaultStat_LPOS_BB2: 8 DACU
 SG_ DiagFaultStat_LPOS_DtcIdB_ISig_4 : 32|16@1+ (1,0) [0|65535] ""  IC3
 SG_ DiagFaultStat_LPOS_FailTB_ISig_4 : 48|8@1+ (1,0) [0|255] ""  IC3
 SG_ DiagFaultStat_LPOS_DtcIdA_ISig_4 : 8|16@1+ (1,0) [0|65535] ""  IC3
 SG_ DiagFaultStat_LPOS_FailTA_ISig_4 : 24|8@1+ (1,0) [0|255] ""  IC3
 SG_ DiagFaultStat_LPOS_sg_UB_ISig_4 : 56|1@1+ (1,0) [0|0] ""  IC3
 SG_ DiagFaultStat_LPOS_EcuAdr_ISig_4 : 0|8@1+ (1,0) [0|255] ""  IC3

BO_ 2147485161 DiagFaultStat_LECM_BB2: 8 CIOM
 SG_ DiagFaultStat_LECM_EcuAdr_ISig_4 : 0|8@1+ (1,0) [0|255] ""  IC3
 SG_ DiagFaultStat_LECM_FailTB_ISig_4 : 48|8@1+ (1,0) [0|255] ""  IC3
 SG_ DiagFaultStat_LECM_FailTA_ISig_4 : 24|8@1+ (1,0) [0|255] ""  IC3
 SG_ DiagFaultStat_LECM_sg_UB_ISig_4 : 56|1@1+ (1,0) [0|0] ""  IC3
 SG_ DiagFaultStat_LECM_DtcIdB_ISig_4 : 32|16@1+ (1,0) [0|65535] ""  IC3
 SG_ DiagFaultStat_LECM_DtcIdA_ISig_4 : 8|16@1+ (1,0) [0|65535] ""  IC3

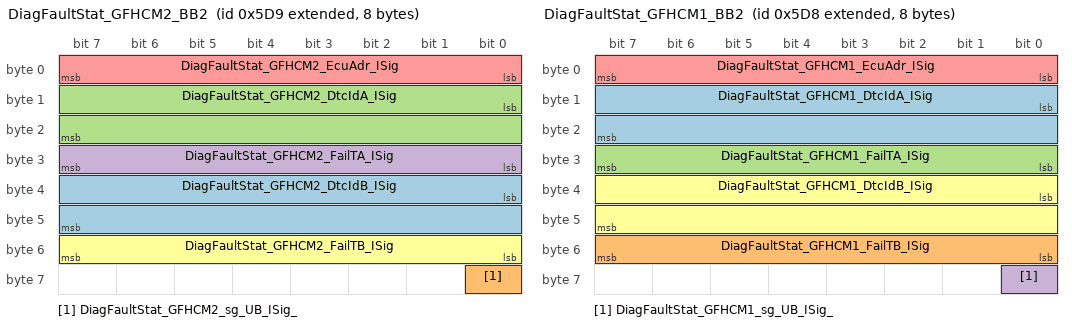
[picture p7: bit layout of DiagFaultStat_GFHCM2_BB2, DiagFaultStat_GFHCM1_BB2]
BO_ 2147485145 DiagFaultStat_GFHCM2_BB2: 8 VMCU
 SG_ DiagFaultStat_GFHCM2_DtcIdB_ISig : 32|16@1+ (1,0) [0|65535] ""  IC3
 SG_ DiagFaultStat_GFHCM2_sg_UB_ISig_ : 56|1@1+ (1,0) [0|0] ""  IC3
 SG_ DiagFaultStat_GFHCM2_DtcIdA_ISig : 8|16@1+ (1,0) [0|65535] ""  IC3
 SG_ DiagFaultStat_GFHCM2_FailTA_ISig : 24|8@1+ (1,0) [0|255] ""  IC3
 SG_ DiagFaultStat_GFHCM2_EcuAdr_ISig : 0|8@1+ (1,0) [0|255] ""  IC3
 SG_ DiagFaultStat_GFHCM2_FailTB_ISig : 48|8@1+ (1,0) [0|255] ""  IC3

BO_ 2147485144 DiagFaultStat_GFHCM1_BB2: 8 VMCU
 SG_ DiagFaultStat_GFHCM1_DtcIdA_ISig : 8|16@1+ (1,0) [0|65535] ""  IC3
 SG_ DiagFaultStat_GFHCM1_FailTB_ISig : 48|8@1+ (1,0) [0|255] ""  IC3
 SG_ DiagFaultStat_GFHCM1_FailTA_ISig : 24|8@1+ (1,0) [0|255] ""  IC3
 SG_ DiagFaultStat_GFHCM1_sg_UB_ISig_ : 56|1@1+ (1,0) [0|0] ""  IC3
 SG_ DiagFaultStat_GFHCM1_EcuAdr_ISig : 0|8@1+ (1,0) [0|255] ""  IC3
 SG_ DiagFaultStat_GFHCM1_DtcIdB_ISig : 32|16@1+ (1,0) [0|65535] ""  IC3

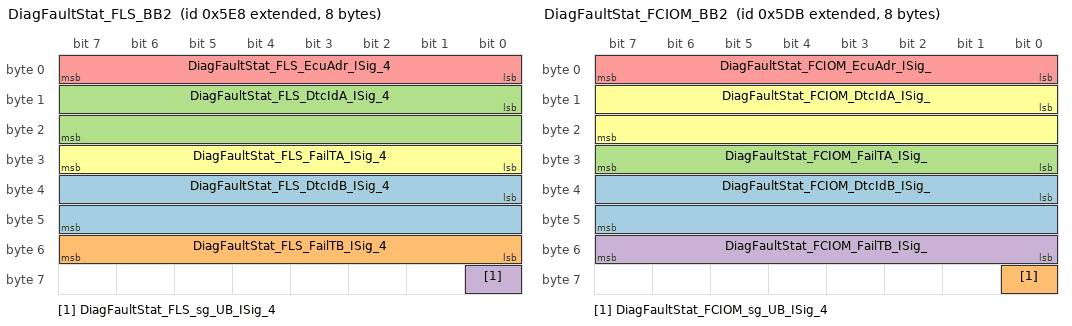
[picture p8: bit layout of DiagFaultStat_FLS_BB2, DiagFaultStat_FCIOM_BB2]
BO_ 2147485160 DiagFaultStat_FLS_BB2: 8 DACU
 SG_ DiagFaultStat_FLS_DtcIdB_ISig_4 : 32|16@1+ (1,0) [0|65535] ""  IC3
 SG_ DiagFaultStat_FLS_FailTB_ISig_4 : 48|8@1+ (1,0) [0|255] ""  IC3
 SG_ DiagFaultStat_FLS_DtcIdA_ISig_4 : 8|16@1+ (1,0) [0|65535] ""  IC3
 SG_ DiagFaultStat_FLS_sg_UB_ISig_4 : 56|1@1+ (1,0) [0|0] ""  IC3
 SG_ DiagFaultStat_FLS_EcuAdr_ISig_4 : 0|8@1+ (1,0) [0|255] ""  IC3
 SG_ DiagFaultStat_FLS_FailTA_ISig_4 : 24|8@1+ (1,0) [0|255] ""  IC3

BO_ 2147485147 DiagFaultStat_FCIOM_BB2: 8 VMCU
 SG_ DiagFaultStat_FCIOM_DtcIdB_ISig_ : 32|16@1+ (1,0) [0|65535] ""  IC3
 SG_ DiagFaultStat_FCIOM_sg_UB_ISig_4 : 56|1@1+ (1,0) [0|0] ""  IC3
 SG_ DiagFaultStat_FCIOM_FailTA_ISig_ : 24|8@1+ (1,0) [0|255] ""  IC3
 SG_ DiagFaultStat_FCIOM_FailTB_ISig_ : 48|8@1+ (1,0) [0|255] ""  IC3
 SG_ DiagFaultStat_FCIOM_EcuAdr_ISig_ : 0|8@1+ (1,0) [0|255] ""  IC3
 SG_ DiagFaultStat_FCIOM_DtcIdA_ISig_ : 8|16@1+ (1,0) [0|65535] ""  IC3

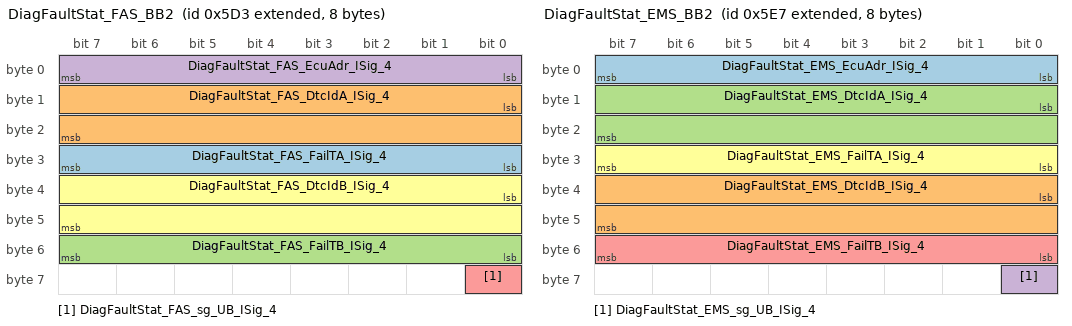
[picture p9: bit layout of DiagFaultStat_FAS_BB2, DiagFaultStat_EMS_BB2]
BO_ 2147485139 DiagFaultStat_FAS_BB2: 8 VMCU
 SG_ DiagFaultStat_FAS_FailTA_ISig_4 : 24|8@1+ (1,0) [0|255] ""  IC3
 SG_ DiagFaultStat_FAS_DtcIdA_ISig_4 : 8|16@1+ (1,0) [0|65535] ""  IC3
 SG_ DiagFaultStat_FAS_FailTB_ISig_4 : 48|8@1+ (1,0) [0|255] ""  IC3
 SG_ DiagFaultStat_FAS_EcuAdr_ISig_4 : 0|8@1+ (1,0) [0|255] ""  IC3
 SG_ DiagFaultStat_FAS_sg_UB_ISig_4 : 56|1@1+ (1,0) [0|0] ""  IC3
 SG_ DiagFaultStat_FAS_DtcIdB_ISig_4 : 32|16@1+ (1,0) [0|65535] ""  IC3

BO_ 2147485159 DiagFaultStat_EMS_BB2: 8 EMS
 SG_ DiagFaultStat_EMS_EcuAdr_ISig_4 : 0|8@1+ (1,0) [0|255] ""  IC3
 SG_ DiagFaultStat_EMS_DtcIdB_ISig_4 : 32|16@1+ (1,0) [0|65535] ""  IC3
 SG_ DiagFaultStat_EMS_DtcIdA_ISig_4 : 8|16@1+ (1,0) [0|65535] ""  IC3
 SG_ DiagFaultStat_EMS_sg_UB_ISig_4 : 56|1@1+ (1,0) [0|0] ""  IC3
 SG_ DiagFaultStat_EMS_FailTB_ISig_4 : 48|8@1+ (1,0) [0|255] ""  IC3
 SG_ DiagFaultStat_EMS_FailTA_ISig_4 : 24|8@1+ (1,0) [0|255] ""  IC3

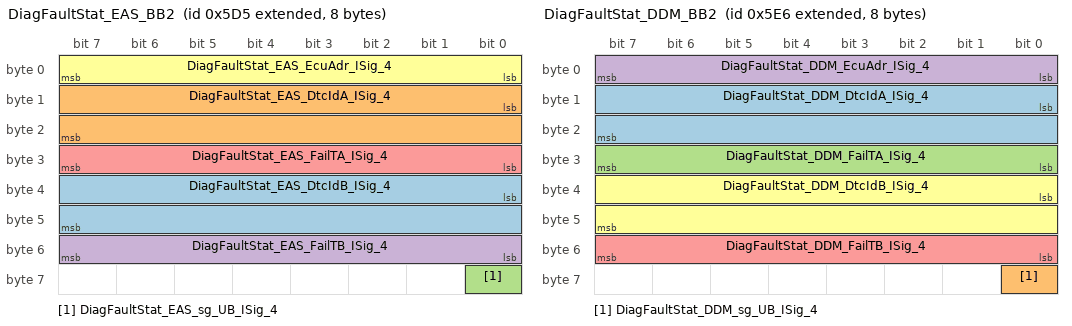
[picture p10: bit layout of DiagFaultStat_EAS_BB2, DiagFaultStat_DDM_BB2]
BO_ 2147485141 DiagFaultStat_EAS_BB2: 8 VMCU
 SG_ DiagFaultStat_EAS_DtcIdB_ISig_4 : 32|16@1+ (1,0) [0|65535] ""  IC3
 SG_ DiagFaultStat_EAS_DtcIdA_ISig_4 : 8|16@1+ (1,0) [0|65535] ""  IC3
 SG_ DiagFaultStat_EAS_sg_UB_ISig_4 : 56|1@1+ (1,0) [0|0] ""  IC3
 SG_ DiagFaultStat_EAS_FailTB_ISig_4 : 48|8@1+ (1,0) [0|255] ""  IC3
 SG_ DiagFaultStat_EAS_FailTA_ISig_4 : 24|8@1+ (1,0) [0|255] ""  IC3
 SG_ DiagFaultStat_EAS_EcuAdr_ISig_4 : 0|8@1+ (1,0) [0|255] ""  IC3

BO_ 2147485158 DiagFaultStat_DDM_BB2: 8 CIOM
 SG_ DiagFaultStat_DDM_DtcIdA_ISig_4 : 8|16@1+ (1,0) [0|65535] ""  IC3
 SG_ DiagFaultStat_DDM_sg_UB_ISig_4 : 56|1@1+ (1,0) [0|0] ""  IC3
 SG_ DiagFaultStat_DDM_FailTA_ISig_4 : 24|8@1+ (1,0) [0|255] ""  IC3
 SG_ DiagFaultStat_DDM_EcuAdr_ISig_4 : 0|8@1+ (1,0) [0|255] ""  IC3
 SG_ DiagFaultStat_DDM_FailTB_ISig_4 : 48|8@1+ (1,0) [0|255] ""  IC3
 SG_ DiagFaultStat_DDM_DtcIdB_ISig_4 : 32|16@1+ (1,0) [0|65535] ""  IC3

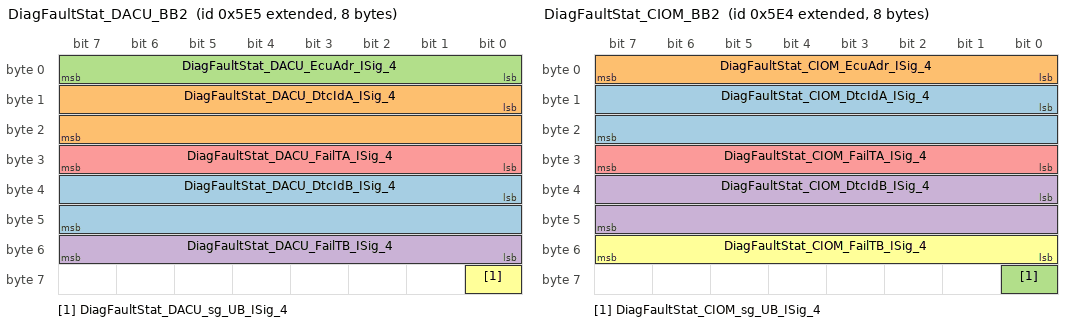
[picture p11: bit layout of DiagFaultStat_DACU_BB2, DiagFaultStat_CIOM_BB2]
BO_ 2147485157 DiagFaultStat_DACU_BB2: 8 DACU
 SG_ DiagFaultStat_DACU_DtcIdB_ISig_4 : 32|16@1+ (1,0) [0|65535] ""  IC3
 SG_ DiagFaultStat_DACU_DtcIdA_ISig_4 : 8|16@1+ (1,0) [0|65535] ""  IC3
 SG_ DiagFaultStat_DACU_EcuAdr_ISig_4 : 0|8@1+ (1,0) [0|255] ""  IC3
 SG_ DiagFaultStat_DACU_FailTB_ISig_4 : 48|8@1+ (1,0) [0|255] ""  IC3
 SG_ DiagFaultStat_DACU_FailTA_ISig_4 : 24|8@1+ (1,0) [0|255] ""  IC3
 SG_ DiagFaultStat_DACU_sg_UB_ISig_4 : 56|1@1+ (1,0) [0|0] ""  IC3

BO_ 2147485156 DiagFaultStat_CIOM_BB2: 8 CIOM
 SG_ DiagFaultStat_CIOM_DtcIdA_ISig_4 : 8|16@1+ (1,0) [0|65535] ""  IC3
 SG_ DiagFaultStat_CIOM_EcuAdr_ISig_4 : 0|8@1+ (1,0) [0|255] ""  IC3
 SG_ DiagFaultStat_CIOM_sg_UB_ISig_4 : 56|1@1+ (1,0) [0|0] ""  IC3
 SG_ DiagFaultStat_CIOM_DtcIdB_ISig_4 : 32|16@1+ (1,0) [0|65535] ""  IC3
 SG_ DiagFaultStat_CIOM_FailTA_ISig_4 : 24|8@1+ (1,0) [0|255] ""  IC3
 SG_ DiagFaultStat_CIOM_FailTB_ISig_4 : 48|8@1+ (1,0) [0|255] ""  IC3

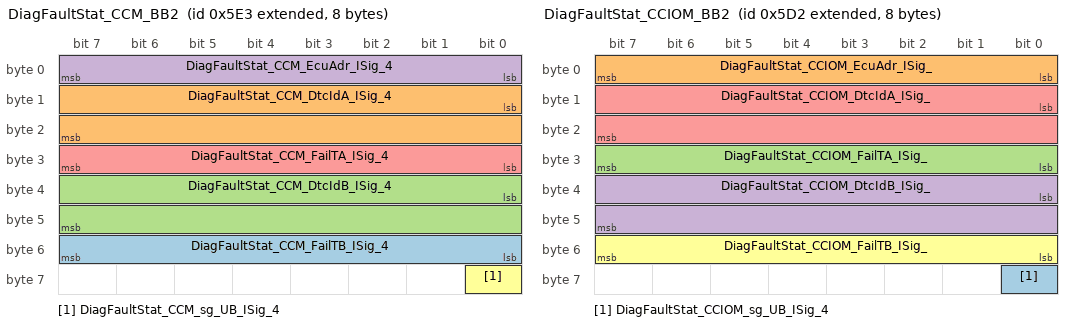
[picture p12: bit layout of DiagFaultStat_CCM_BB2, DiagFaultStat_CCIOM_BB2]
BO_ 2147485155 DiagFaultStat_CCM_BB2: 8 CIOM
 SG_ DiagFaultStat_CCM_FailTB_ISig_4 : 48|8@1+ (1,0) [0|255] ""  IC3
 SG_ DiagFaultStat_CCM_DtcIdA_ISig_4 : 8|16@1+ (1,0) [0|65535] ""  IC3
 SG_ DiagFaultStat_CCM_DtcIdB_ISig_4 : 32|16@1+ (1,0) [0|65535] ""  IC3
 SG_ DiagFaultStat_CCM_EcuAdr_ISig_4 : 0|8@1+ (1,0) [0|255] ""  IC3
 SG_ DiagFaultStat_CCM_FailTA_ISig_4 : 24|8@1+ (1,0) [0|255] ""  IC3
 SG_ DiagFaultStat_CCM_sg_UB_ISig_4 : 56|1@1+ (1,0) [0|0] ""  IC3

BO_ 2147485138 DiagFaultStat_CCIOM_BB2: 8 VMCU
 SG_ DiagFaultStat_CCIOM_sg_UB_ISig_4 : 56|1@1+ (1,0) [0|0] ""  IC3
 SG_ DiagFaultStat_CCIOM_EcuAdr_ISig_ : 0|8@1+ (1,0) [0|255] ""  IC3
 SG_ DiagFaultStat_CCIOM_FailTA_ISig_ : 24|8@1+ (1,0) [0|255] ""  IC3
 SG_ DiagFaultStat_CCIOM_DtcIdB_ISig_ : 32|16@1+ (1,0) [0|65535] ""  IC3
 SG_ DiagFaultStat_CCIOM_DtcIdA_ISig_ : 8|16@1+ (1,0) [0|65535] ""  IC3
 SG_ DiagFaultStat_CCIOM_FailTB_ISig_ : 48|8@1+ (1,0) [0|255] ""  IC3

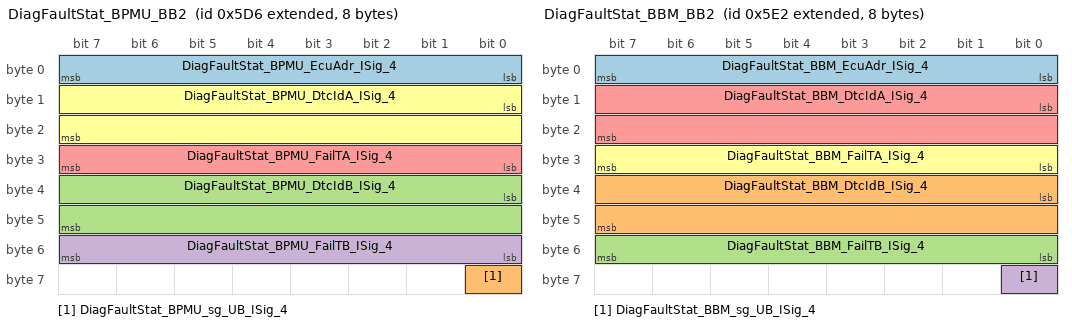
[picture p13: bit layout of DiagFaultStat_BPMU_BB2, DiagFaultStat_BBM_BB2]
BO_ 2147485142 DiagFaultStat_BPMU_BB2: 8 VMCU
 SG_ DiagFaultStat_BPMU_EcuAdr_ISig_4 : 0|8@1+ (1,0) [0|255] ""  IC3
 SG_ DiagFaultStat_BPMU_sg_UB_ISig_4 : 56|1@1+ (1,0) [0|0] ""  IC3
 SG_ DiagFaultStat_BPMU_DtcIdB_ISig_4 : 32|16@1+ (1,0) [0|65535] ""  IC3
 SG_ DiagFaultStat_BPMU_FailTB_ISig_4 : 48|8@1+ (1,0) [0|255] ""  IC3
 SG_ DiagFaultStat_BPMU_FailTA_ISig_4 : 24|8@1+ (1,0) [0|255] ""  IC3
 SG_ DiagFaultStat_BPMU_DtcIdA_ISig_4 : 8|16@1+ (1,0) [0|65535] ""  IC3

BO_ 2147485154 DiagFaultStat_BBM_BB2: 8 BBM
 SG_ DiagFaultStat_BBM_EcuAdr_ISig_4 : 0|8@1+ (1,0) [0|255] ""  IC3
 SG_ DiagFaultStat_BBM_DtcIdB_ISig_4 : 32|16@1+ (1,0) [0|65535] ""  IC3
 SG_ DiagFaultStat_BBM_FailTB_ISig_4 : 48|8@1+ (1,0) [0|255] ""  IC3
 SG_ DiagFaultStat_BBM_sg_UB_ISig_4 : 56|1@1+ (1,0) [0|0] ""  IC3
 SG_ DiagFaultStat_BBM_DtcIdA_ISig_4 : 8|16@1+ (1,0) [0|65535] ""  IC3
 SG_ DiagFaultStat_BBM_FailTA_ISig_4 : 24|8@1+ (1,0) [0|255] ""  IC3

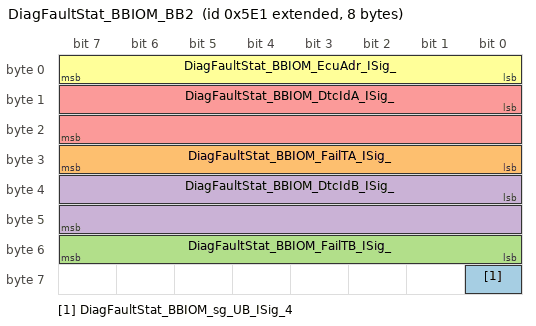
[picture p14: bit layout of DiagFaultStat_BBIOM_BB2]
BO_ 2147485153 DiagFaultStat_BBIOM_BB2: 8 BBM
 SG_ DiagFaultStat_BBIOM_sg_UB_ISig_4 : 56|1@1+ (1,0) [0|0] ""  IC3
 SG_ DiagFaultStat_BBIOM_FailTA_ISig_ : 24|8@1+ (1,0) [0|255] ""  IC3
 SG_ DiagFaultStat_BBIOM_FailTB_ISig_ : 48|8@1+ (1,0) [0|255] ""  IC3
 SG_ DiagFaultStat_BBIOM_DtcIdB_ISig_ : 32|16@1+ (1,0) [0|65535] ""  IC3
 SG_ DiagFaultStat_BBIOM_DtcIdA_ISig_ : 8|16@1+ (1,0) [0|65535] ""  IC3
 SG_ DiagFaultStat_BBIOM_EcuAdr_ISig_ : 0|8@1+ (1,0) [0|255] ""  IC3

CM_ SG_ 2147485039 OilPrediction_RemainDist "65024 - 65279 Error ; 65280 - 65535 Not available";
CM_ SG_ 2147485039 TimeToCorrectOilLevel_ISig_4 "254 Error ; 255 Not Available";
CM_ SG_ 2147485039 OilPrediction_RemainTime "65024 - 65279 Error ; 65280 - 65535 Not available";
CM_ SG_ 2147484939 EngineTotalFuelConsumed_ISig_4 "4261412864 - 4278190079 Error ; 4278190080 - 4294967295 Not available";
CM_ SG_ 2147484939 BarometricPressure_ISig_4 "254 Error ; 255 Not available";
CM_ SG_ 2147484927 EngineAirInletTemperature "254 Error ; 255 Not available";
CM_ SG_ 2147484927 StarterMotorRecoveryTime "65024 - 65279 Error ; 65280 - 65535 Not available";
CM_ SG_ 2147484927 AppliedVehicleSpeedLimit "65024 - 65279 Error ; 65280 - 65535 Not available";
CM_ BO_ 2147484381 "COM_MATRIX_1.7.0 Removed signals: XARActivePriority bit 2-3, XARAbilityMinAcceleration bit16-31, XARAbilityMaxAcceleration bit 32-47";
CM_ SG_ 2147484367 EngineAirInletPressure "254 Error ; 255 Not available";
CM_ SG_ 2147484367 DeterminedGear "254 Error ; 255 Not available";
CM_ SG_ 2147484367 CCSetSpeedApplied_ISig_4 "254 Error ; 255 Not available";
CM_ BO_ 2671964768 "Note: old interface for HMIIOM, can be deleted when IC3 is configured with address 0x61.";
BA_DEF_ BO_  "GenMsgStartDelayTime" INT 0 0;
BA_DEF_ BO_  "GenMsgDelayTime" INT 0 0;
BA_DEF_ BO_  "GenMsgCycleTime" INT 0 0;
BA_DEF_ BO_  "GenMsgSendType" ENUM  "Cyclic","NotUsed","NotUsed","NotUsed","NotUsed","NotUsed","NotUsed","IfActive","NoMsgSendType","NotUsed";
BA_DEF_ SG_  "GenSigStartValue" INT 0 0;
BA_DEF_ SG_  "GenSigCycleTimeActive" INT 0 0;
BA_DEF_ SG_  "GenSigCycleTime" INT 0 0;
BA_DEF_ SG_  "GenSigSendType" ENUM  "Cyclic","OnWrite","OnWriteWithRepetition","OnChange","OnChangeWithRepetition","IfActive","IfActiveWithRepetition","NoSigSendType","NotUsed","NotUsed","NotUsed","NotUsed","NotUsed";
BA_DEF_ BO_  "VFrameFormat" ENUM  "StandardCAN","ExtendedCAN","reserved","J1939PG";
BA_DEF_ SG_  "SigType" ENUM  "Default","Range","RangeSigned","ASCII","Discrete","Control","ReferencePGN","DTC","StringDelimiter","StringLength","StringLengthControl";
BA_DEF_ SG_  "SeToolVersion_SIGNAL" STRING ;
BA_DEF_ SG_  "SeToolUniqueID_SIGNAL" STRING ;
BA_DEF_ SG_  "SeToolOwnerSigGroup_SIGNAL" STRING ;
BA_DEF_ SG_  "SeToolOwnerSigGroupID_SIGNAL" STRING ;
BA_DEF_ SG_  "SeToolName_SIGNAL" STRING ;
BA_DEF_ SG_  "SeToolItemID_SIGNAL" STRING ;
BA_DEF_ SG_  "SeToolAncestorID_SIGNAL" STRING ;
BA_DEF_ SG_  "Platform_VMCU1_Sig" ENUM  "No","Yes";
BA_DEF_ BO_  "NmAsrMessage" ENUM  "No","Yes";
BA_DEF_ SG_  "NeedsUpdateBit" ENUM  "No","Yes";
BA_DEF_ SG_  "MmAnSignal" ENUM  "No","Yes";
BA_DEF_ SG_  "GenSigMaxLatency" INT 0 65535;
BA_DEF_ SG_  "GenSigILSupport" ENUM  "Yes","No";
BA_DEF_ BO_  "GenMsgRequestable" INT 0 1;
BA_DEF_ BO_  "GenMsgILSupport" ENUM  "No","Yes";
BA_DEF_ BO_  "DiagUUDTResponse" ENUM  "No","Yes";
BA_DEF_ BO_  "DiagState" ENUM  "No","Yes";
BA_DEF_ BO_  "DiagResponse" ENUM  "No","Yes";
BA_DEF_ BO_  "DiagRequest" ENUM  "No","Yes";
BA_DEF_ BO_  "DiagConnection" HEX 0 65535;
BA_DEF_ BO_  "CanTpSTmin" INT 0 255;
BA_DEF_ BO_  "CanTpFcFrameId" HEX 0 2147483647;
BA_DEF_ BO_  "CanTpBs" INT 0 255;
BA_DEF_ SG_  "SystemSignalLongSymbol" STRING ;
BA_DEF_REL_ BU_SG_REL_  "GenSigTimeoutTime" INT 0 65535;
BA_DEF_REL_ BU_SG_REL_  "GenSigFirstTimeoutTime" INT 0 65535;
BA_DEF_DEF_  "GenMsgStartDelayTime" 0;
BA_DEF_DEF_  "GenMsgDelayTime" 0;
BA_DEF_DEF_  "GenMsgCycleTime" 0;
BA_DEF_DEF_  "GenMsgSendType" "Cyclic";
BA_DEF_DEF_  "GenSigStartValue" 0;
BA_DEF_DEF_  "GenSigCycleTimeActive" 0;
BA_DEF_DEF_  "GenSigCycleTime" 0;
BA_DEF_DEF_  "GenSigSendType" "Cyclic";
BA_DEF_DEF_  "VFrameFormat" "ExtendedCAN";
BA_DEF_DEF_  "SigType" "Default";
BA_DEF_DEF_  "SeToolVersion_SIGNAL" "";
BA_DEF_DEF_  "SeToolUniqueID_SIGNAL" "";
BA_DEF_DEF_  "SeToolOwnerSigGroup_SIGNAL" "";
BA_DEF_DEF_  "SeToolOwnerSigGroupID_SIGNAL" "";
BA_DEF_DEF_  "SeToolName_SIGNAL" "";
BA_DEF_DEF_  "SeToolItemID_SIGNAL" "";
BA_DEF_DEF_  "SeToolAncestorID_SIGNAL" "";
BA_DEF_DEF_  "Platform_VMCU1_Sig" "No";
BA_DEF_DEF_  "NmAsrMessage" "No";
BA_DEF_DEF_  "NeedsUpdateBit" "No";
BA_DEF_DEF_  "MmAnSignal" "No";
BA_DEF_DEF_  "GenSigMaxLatency" 0;
BA_DEF_DEF_  "GenSigILSupport" "Yes";
BA_DEF_DEF_  "GenMsgRequestable" 1;
BA_DEF_DEF_  "GenMsgILSupport" "Yes";
BA_DEF_DEF_  "DiagUUDTResponse" "No";
BA_DEF_DEF_  "DiagState" "No";
BA_DEF_DEF_  "DiagResponse" "No";
BA_DEF_DEF_  "DiagRequest" "No";
BA_DEF_DEF_  "DiagConnection" 0;
BA_DEF_DEF_  "CanTpSTmin" 0;
BA_DEF_DEF_  "CanTpFcFrameId" 2147483647;
BA_DEF_DEF_  "CanTpBs" 255;
BA_DEF_DEF_REL_ "GenSigTimeoutTime" 0;
BA_DEF_DEF_REL_ "GenSigFirstTimeoutTime" 0;
BA_DEF_DEF_  "SystemSignalLongSymbol" "";
BA_ "GenMsgCycleTime" BO_ 2147485039 1500;
BA_ "GenMsgStartDelayTime" BO_ 2147485039 250;
BA_ "GenMsgCycleTime" BO_ 2147484924 250;
BA_ "GenMsgStartDelayTime" BO_ 2147484924 120;
BA_ "GenMsgCycleTime" BO_ 2147484939 250;
BA_ "GenMsgStartDelayTime" BO_ 2147484939 15;
BA_ "GenMsgCycleTime" BO_ 2147484927 250;
BA_ "GenMsgStartDelayTime" BO_ 2147484927 5;
BA_ "GenMsgCycleTime" BO_ 2147484381 45;
BA_ "GenMsgCycleTime" BO_ 2147484367 45;
BA_ "GenMsgStartDelayTime" BO_ 2147484367 20;
BA_ "DiagConnection" BO_ 2671964902 62182;
BA_ "DiagUUDTResponse" BO_ 2671964902 1;
BA_ "GenMsgILSupport" BO_ 2671964902 0;
BA_ "GenMsgSendType" BO_ 2671964902 8;
BA_ "DiagConnection" BO_ 2671964901 62181;
BA_ "DiagUUDTResponse" BO_ 2671964901 1;
BA_ "GenMsgILSupport" BO_ 2671964901 0;
BA_ "GenMsgSendType" BO_ 2671964901 8;
BA_ "DiagConnection" BO_ 2671964864 62144;
BA_ "DiagUUDTResponse" BO_ 2671964864 1;
BA_ "GenMsgILSupport" BO_ 2671964864 0;
BA_ "GenMsgSendType" BO_ 2671964864 8;
BA_ "DiagConnection" BO_ 2671964834 62114;
BA_ "DiagUUDTResponse" BO_ 2671964834 1;
BA_ "GenMsgILSupport" BO_ 2671964834 0;
BA_ "GenMsgSendType" BO_ 2671964834 8;
BA_ "DiagConnection" BO_ 2671964833 62113;
BA_ "DiagUUDTResponse" BO_ 2671964833 1;
BA_ "GenMsgILSupport" BO_ 2671964833 0;
BA_ "GenMsgSendType" BO_ 2671964833 8;
BA_ "DiagConnection" BO_ 2671964832 62112;
BA_ "DiagUUDTResponse" BO_ 2671964832 1;
BA_ "GenMsgILSupport" BO_ 2671964832 0;
BA_ "GenMsgSendType" BO_ 2671964832 8;
BA_ "DiagConnection" BO_ 2671964824 62104;
BA_ "DiagUUDTResponse" BO_ 2671964824 1;
BA_ "GenMsgILSupport" BO_ 2671964824 0;
BA_ "GenMsgSendType" BO_ 2671964824 8;
BA_ "DiagConnection" BO_ 2671964803 62083;
BA_ "DiagUUDTResponse" BO_ 2671964803 1;
BA_ "GenMsgILSupport" BO_ 2671964803 0;
BA_ "GenMsgSendType" BO_ 2671964803 8;
BA_ "DiagConnection" BO_ 2671964802 62082;
BA_ "DiagUUDTResponse" BO_ 2671964802 1;
BA_ "GenMsgILSupport" BO_ 2671964802 0;
BA_ "GenMsgSendType" BO_ 2671964802 8;
BA_ "DiagConnection" BO_ 2671964772 62052;
BA_ "DiagUUDTResponse" BO_ 2671964772 1;
BA_ "GenMsgILSupport" BO_ 2671964772 0;
BA_ "GenMsgSendType" BO_ 2671964772 8;
BA_ "DiagConnection" BO_ 2671964769 62049;
BA_ "DiagUUDTResponse" BO_ 2671964769 1;
BA_ "GenMsgILSupport" BO_ 2671964769 0;
BA_ "GenMsgSendType" BO_ 2671964769 8;
BA_ "DiagConnection" BO_ 2671964768 62048;
BA_ "DiagUUDTResponse" BO_ 2671964768 1;
BA_ "GenMsgILSupport" BO_ 2671964768 0;
BA_ "GenMsgSendType" BO_ 2671964768 8;
BA_ "DiagConnection" BO_ 2671964755 62035;
BA_ "DiagUUDTResponse" BO_ 2671964755 1;
BA_ "GenMsgILSupport" BO_ 2671964755 0;
BA_ "GenMsgSendType" BO_ 2671964755 8;
BA_ "DiagConnection" BO_ 2671964754 62034;
BA_ "DiagUUDTResponse" BO_ 2671964754 1;
BA_ "GenMsgILSupport" BO_ 2671964754 0;
BA_ "GenMsgSendType" BO_ 2671964754 8;
BA_ "DiagConnection" BO_ 2671964753 62033;
BA_ "DiagUUDTResponse" BO_ 2671964753 1;
BA_ "GenMsgILSupport" BO_ 2671964753 0;
BA_ "GenMsgSendType" BO_ 2671964753 8;
BA_ "DiagConnection" BO_ 2671964752 62032;
BA_ "DiagUUDTResponse" BO_ 2671964752 1;
BA_ "GenMsgILSupport" BO_ 2671964752 0;
BA_ "GenMsgSendType" BO_ 2671964752 8;
BA_ "DiagConnection" BO_ 2671964737 62017;
BA_ "DiagUUDTResponse" BO_ 2671964737 1;
BA_ "GenMsgILSupport" BO_ 2671964737 0;
BA_ "GenMsgSendType" BO_ 2671964737 8;
BA_ "DiagConnection" BO_ 2671964736 62016;
BA_ "DiagUUDTResponse" BO_ 2671964736 1;
BA_ "GenMsgILSupport" BO_ 2671964736 0;
BA_ "GenMsgSendType" BO_ 2671964736 8;
BA_ "DiagConnection" BO_ 2671964710 61990;
BA_ "DiagUUDTResponse" BO_ 2671964710 1;
BA_ "GenMsgILSupport" BO_ 2671964710 0;
BA_ "GenMsgSendType" BO_ 2671964710 8;
BA_ "DiagConnection" BO_ 2671964696 61976;
BA_ "DiagUUDTResponse" BO_ 2671964696 1;
BA_ "GenMsgILSupport" BO_ 2671964696 0;
BA_ "GenMsgSendType" BO_ 2671964696 8;
BA_ "DiagConnection" BO_ 2671964688 61968;
BA_ "DiagUUDTResponse" BO_ 2671964688 1;
BA_ "GenMsgILSupport" BO_ 2671964688 0;
BA_ "GenMsgSendType" BO_ 2671964688 8;
BA_ "DiagConnection" BO_ 2671834342 62694;
BA_ "DiagResponse" BO_ 2671834342 1;
BA_ "GenMsgILSupport" BO_ 2671834342 0;
BA_ "GenMsgSendType" BO_ 2671834342 8;
BA_ "DiagConnection" BO_ 2671834341 62693;
BA_ "DiagResponse" BO_ 2671834341 1;
BA_ "GenMsgILSupport" BO_ 2671834341 0;
BA_ "GenMsgSendType" BO_ 2671834341 8;
BA_ "DiagConnection" BO_ 2671834304 62656;
BA_ "DiagResponse" BO_ 2671834304 1;
BA_ "GenMsgILSupport" BO_ 2671834304 0;
BA_ "GenMsgSendType" BO_ 2671834304 8;
BA_ "DiagConnection" BO_ 2671834274 62626;
BA_ "DiagResponse" BO_ 2671834274 1;
BA_ "GenMsgILSupport" BO_ 2671834274 0;
BA_ "GenMsgSendType" BO_ 2671834274 8;
BA_ "DiagConnection" BO_ 2671834273 62625;
BA_ "DiagResponse" BO_ 2671834273 1;
BA_ "GenMsgILSupport" BO_ 2671834273 0;
BA_ "GenMsgSendType" BO_ 2671834273 8;
BA_ "DiagConnection" BO_ 2671834272 62624;
BA_ "DiagResponse" BO_ 2671834272 1;
BA_ "GenMsgILSupport" BO_ 2671834272 0;
BA_ "GenMsgSendType" BO_ 2671834272 8;
BA_ "DiagConnection" BO_ 2671834264 62616;
BA_ "DiagResponse" BO_ 2671834264 1;
BA_ "GenMsgILSupport" BO_ 2671834264 0;
BA_ "GenMsgSendType" BO_ 2671834264 8;
BA_ "DiagConnection" BO_ 2671834226 62578;
BA_ "DiagResponse" BO_ 2671834226 1;
BA_ "GenMsgILSupport" BO_ 2671834226 0;
BA_ "GenMsgSendType" BO_ 2671834226 8;
BA_ "DiagConnection" BO_ 2671834225 62577;
BA_ "DiagResponse" BO_ 2671834225 1;
BA_ "GenMsgILSupport" BO_ 2671834225 0;
BA_ "GenMsgSendType" BO_ 2671834225 8;
BA_ "DiagConnection" BO_ 2671834195 62547;
BA_ "DiagResponse" BO_ 2671834195 1;
BA_ "GenMsgILSupport" BO_ 2671834195 0;
BA_ "GenMsgSendType" BO_ 2671834195 8;
BA_ "DiagConnection" BO_ 2671834194 62546;
BA_ "DiagResponse" BO_ 2671834194 1;
BA_ "GenMsgILSupport" BO_ 2671834194 0;
BA_ "GenMsgSendType" BO_ 2671834194 8;
BA_ "DiagConnection" BO_ 2671834193 62545;
BA_ "DiagResponse" BO_ 2671834193 1;
BA_ "GenMsgILSupport" BO_ 2671834193 0;
BA_ "GenMsgSendType" BO_ 2671834193 8;
BA_ "DiagConnection" BO_ 2671834192 62544;
BA_ "DiagResponse" BO_ 2671834192 1;
BA_ "GenMsgILSupport" BO_ 2671834192 0;
BA_ "GenMsgSendType" BO_ 2671834192 8;
BA_ "DiagConnection" BO_ 2671834176 62528;
BA_ "DiagResponse" BO_ 2671834176 1;
BA_ "GenMsgILSupport" BO_ 2671834176 0;
BA_ "GenMsgSendType" BO_ 2671834176 8;
BA_ "DiagConnection" BO_ 2671834161 62513;
BA_ "DiagResponse" BO_ 2671834161 1;
BA_ "GenMsgILSupport" BO_ 2671834161 0;
BA_ "GenMsgSendType" BO_ 2671834161 8;
BA_ "DiagConnection" BO_ 2671834160 62512;
BA_ "DiagResponse" BO_ 2671834160 1;
BA_ "GenMsgILSupport" BO_ 2671834160 0;
BA_ "GenMsgSendType" BO_ 2671834160 8;
BA_ "DiagConnection" BO_ 2671834150 62502;
BA_ "DiagResponse" BO_ 2671834150 1;
BA_ "GenMsgILSupport" BO_ 2671834150 0;
BA_ "GenMsgSendType" BO_ 2671834150 8;
BA_ "DiagConnection" BO_ 2671834149 62501;
BA_ "DiagResponse" BO_ 2671834149 1;
BA_ "GenMsgILSupport" BO_ 2671834149 0;
BA_ "GenMsgSendType" BO_ 2671834149 8;
BA_ "DiagConnection" BO_ 2671834148 62500;
BA_ "DiagResponse" BO_ 2671834148 1;
BA_ "GenMsgILSupport" BO_ 2671834148 0;
BA_ "GenMsgSendType" BO_ 2671834148 8;
BA_ "DiagConnection" BO_ 2671834147 62499;
BA_ "DiagResponse" BO_ 2671834147 1;
BA_ "GenMsgILSupport" BO_ 2671834147 0;
BA_ "GenMsgSendType" BO_ 2671834147 8;
BA_ "DiagConnection" BO_ 2671834146 62498;
BA_ "DiagResponse" BO_ 2671834146 1;
BA_ "GenMsgILSupport" BO_ 2671834146 0;
BA_ "GenMsgSendType" BO_ 2671834146 8;
BA_ "DiagConnection" BO_ 2671834145 62497;
BA_ "DiagResponse" BO_ 2671834145 1;
BA_ "GenMsgILSupport" BO_ 2671834145 0;
BA_ "GenMsgSendType" BO_ 2671834145 8;
BA_ "DiagConnection" BO_ 2671834144 62496;
BA_ "DiagResponse" BO_ 2671834144 1;
BA_ "GenMsgILSupport" BO_ 2671834144 0;
BA_ "GenMsgSendType" BO_ 2671834144 8;
BA_ "DiagConnection" BO_ 2671834138 62490;
BA_ "DiagResponse" BO_ 2671834138 1;
BA_ "GenMsgILSupport" BO_ 2671834138 0;
BA_ "GenMsgSendType" BO_ 2671834138 8;
BA_ "DiagConnection" BO_ 2671834136 62488;
BA_ "DiagResponse" BO_ 2671834136 1;
BA_ "GenMsgILSupport" BO_ 2671834136 0;
BA_ "GenMsgSendType" BO_ 2671834136 8;
BA_ "DiagConnection" BO_ 2671834128 62480;
BA_ "DiagResponse" BO_ 2671834128 1;
BA_ "GenMsgILSupport" BO_ 2671834128 0;
BA_ "GenMsgSendType" BO_ 2671834128 8;
BA_ "DiagConnection" BO_ 2671834086 62438;
BA_ "DiagResponse" BO_ 2671834086 1;
BA_ "GenMsgILSupport" BO_ 2671834086 0;
BA_ "GenMsgSendType" BO_ 2671834086 8;
BA_ "DiagConnection" BO_ 2671834085 62437;
BA_ "DiagResponse" BO_ 2671834085 1;
BA_ "GenMsgILSupport" BO_ 2671834085 0;
BA_ "GenMsgSendType" BO_ 2671834085 8;
BA_ "DiagConnection" BO_ 2671834048 62400;
BA_ "DiagResponse" BO_ 2671834048 1;
BA_ "GenMsgILSupport" BO_ 2671834048 0;
BA_ "GenMsgSendType" BO_ 2671834048 8;
BA_ "DiagConnection" BO_ 2671834018 62370;
BA_ "DiagResponse" BO_ 2671834018 1;
BA_ "GenMsgILSupport" BO_ 2671834018 0;
BA_ "GenMsgSendType" BO_ 2671834018 8;
BA_ "DiagConnection" BO_ 2671834017 62369;
BA_ "DiagResponse" BO_ 2671834017 1;
BA_ "GenMsgILSupport" BO_ 2671834017 0;
BA_ "GenMsgSendType" BO_ 2671834017 8;
BA_ "DiagConnection" BO_ 2671834016 62368;
BA_ "DiagResponse" BO_ 2671834016 1;
BA_ "GenMsgILSupport" BO_ 2671834016 0;
BA_ "GenMsgSendType" BO_ 2671834016 8;
BA_ "DiagConnection" BO_ 2671834008 62360;
BA_ "DiagResponse" BO_ 2671834008 1;
BA_ "GenMsgILSupport" BO_ 2671834008 0;
BA_ "GenMsgSendType" BO_ 2671834008 8;
BA_ "DiagConnection" BO_ 2671833970 62322;
BA_ "DiagResponse" BO_ 2671833970 1;
BA_ "GenMsgILSupport" BO_ 2671833970 0;
BA_ "GenMsgSendType" BO_ 2671833970 8;
BA_ "DiagConnection" BO_ 2671833969 62321;
BA_ "DiagResponse" BO_ 2671833969 1;
BA_ "GenMsgILSupport" BO_ 2671833969 0;
BA_ "GenMsgSendType" BO_ 2671833969 8;
BA_ "DiagConnection" BO_ 2671833939 62291;
BA_ "DiagResponse" BO_ 2671833939 1;
BA_ "GenMsgILSupport" BO_ 2671833939 0;
BA_ "GenMsgSendType" BO_ 2671833939 8;
BA_ "DiagConnection" BO_ 2671833938 62290;
BA_ "DiagResponse" BO_ 2671833938 1;
BA_ "GenMsgILSupport" BO_ 2671833938 0;
BA_ "GenMsgSendType" BO_ 2671833938 8;
BA_ "DiagConnection" BO_ 2671833937 62289;
BA_ "DiagResponse" BO_ 2671833937 1;
BA_ "GenMsgILSupport" BO_ 2671833937 0;
BA_ "GenMsgSendType" BO_ 2671833937 8;
BA_ "DiagConnection" BO_ 2671833936 62288;
BA_ "DiagResponse" BO_ 2671833936 1;
BA_ "GenMsgILSupport" BO_ 2671833936 0;
BA_ "GenMsgSendType" BO_ 2671833936 8;
BA_ "DiagConnection" BO_ 2671833920 62272;
BA_ "DiagResponse" BO_ 2671833920 1;
BA_ "GenMsgILSupport" BO_ 2671833920 0;
BA_ "GenMsgSendType" BO_ 2671833920 8;
BA_ "DiagConnection" BO_ 2671833905 62257;
BA_ "DiagResponse" BO_ 2671833905 1;
BA_ "GenMsgILSupport" BO_ 2671833905 0;
BA_ "GenMsgSendType" BO_ 2671833905 8;
BA_ "DiagConnection" BO_ 2671833904 62256;
BA_ "DiagResponse" BO_ 2671833904 1;
BA_ "GenMsgILSupport" BO_ 2671833904 0;
BA_ "GenMsgSendType" BO_ 2671833904 8;
BA_ "DiagConnection" BO_ 2671833894 62246;
BA_ "DiagResponse" BO_ 2671833894 1;
BA_ "GenMsgILSupport" BO_ 2671833894 0;
BA_ "GenMsgSendType" BO_ 2671833894 8;
BA_ "DiagConnection" BO_ 2671833893 62245;
BA_ "DiagResponse" BO_ 2671833893 1;
BA_ "GenMsgILSupport" BO_ 2671833893 0;
BA_ "GenMsgSendType" BO_ 2671833893 8;
BA_ "DiagConnection" BO_ 2671833892 62244;
BA_ "DiagResponse" BO_ 2671833892 1;
BA_ "GenMsgILSupport" BO_ 2671833892 0;
BA_ "GenMsgSendType" BO_ 2671833892 8;
BA_ "DiagConnection" BO_ 2671833891 62243;
BA_ "DiagResponse" BO_ 2671833891 1;
BA_ "GenMsgILSupport" BO_ 2671833891 0;
BA_ "GenMsgSendType" BO_ 2671833891 8;
BA_ "DiagConnection" BO_ 2671833890 62242;
BA_ "DiagResponse" BO_ 2671833890 1;
BA_ "GenMsgILSupport" BO_ 2671833890 0;
BA_ "GenMsgSendType" BO_ 2671833890 8;
BA_ "DiagConnection" BO_ 2671833889 62241;
BA_ "DiagResponse" BO_ 2671833889 1;
BA_ "GenMsgILSupport" BO_ 2671833889 0;
BA_ "GenMsgSendType" BO_ 2671833889 8;
BA_ "DiagConnection" BO_ 2671833888 62240;
BA_ "DiagResponse" BO_ 2671833888 1;
BA_ "GenMsgILSupport" BO_ 2671833888 0;
BA_ "GenMsgSendType" BO_ 2671833888 8;
BA_ "DiagConnection" BO_ 2671833882 62234;
BA_ "DiagResponse" BO_ 2671833882 1;
BA_ "GenMsgILSupport" BO_ 2671833882 0;
BA_ "GenMsgSendType" BO_ 2671833882 8;
BA_ "DiagConnection" BO_ 2671833880 62232;
BA_ "DiagResponse" BO_ 2671833880 1;
BA_ "GenMsgILSupport" BO_ 2671833880 0;
BA_ "GenMsgSendType" BO_ 2671833880 8;
BA_ "DiagConnection" BO_ 2671833872 62224;
BA_ "DiagResponse" BO_ 2671833872 1;
BA_ "GenMsgILSupport" BO_ 2671833872 0;
BA_ "GenMsgSendType" BO_ 2671833872 8;
BA_ "DiagConnection" BO_ 2671830772 62694;
BA_ "DiagRequest" BO_ 2671830772 1;
BA_ "GenMsgILSupport" BO_ 2671830772 0;
BA_ "GenMsgSendType" BO_ 2671830772 8;
BA_ "DiagConnection" BO_ 2671830516 62693;
BA_ "DiagRequest" BO_ 2671830516 1;
BA_ "GenMsgILSupport" BO_ 2671830516 0;
BA_ "GenMsgSendType" BO_ 2671830516 8;
BA_ "DiagConnection" BO_ 2671821044 62656;
BA_ "DiagRequest" BO_ 2671821044 1;
BA_ "GenMsgILSupport" BO_ 2671821044 0;
BA_ "GenMsgSendType" BO_ 2671821044 8;
BA_ "DiagConnection" BO_ 2671813364 62626;
BA_ "DiagRequest" BO_ 2671813364 1;
BA_ "GenMsgILSupport" BO_ 2671813364 0;
BA_ "GenMsgSendType" BO_ 2671813364 8;
BA_ "DiagConnection" BO_ 2671813108 62625;
BA_ "DiagRequest" BO_ 2671813108 1;
BA_ "GenMsgILSupport" BO_ 2671813108 0;
BA_ "GenMsgSendType" BO_ 2671813108 8;
BA_ "DiagConnection" BO_ 2671812852 62624;
BA_ "DiagRequest" BO_ 2671812852 1;
BA_ "GenMsgILSupport" BO_ 2671812852 0;
BA_ "GenMsgSendType" BO_ 2671812852 8;
BA_ "DiagConnection" BO_ 2671810804 62616;
BA_ "DiagRequest" BO_ 2671810804 1;
BA_ "GenMsgILSupport" BO_ 2671810804 0;
BA_ "GenMsgSendType" BO_ 2671810804 8;
BA_ "DiagConnection" BO_ 2671801076 62578;
BA_ "DiagRequest" BO_ 2671801076 1;
BA_ "GenMsgILSupport" BO_ 2671801076 0;
BA_ "GenMsgSendType" BO_ 2671801076 8;
BA_ "DiagConnection" BO_ 2671800820 62577;
BA_ "DiagRequest" BO_ 2671800820 1;
BA_ "GenMsgILSupport" BO_ 2671800820 0;
BA_ "GenMsgSendType" BO_ 2671800820 8;
BA_ "DiagConnection" BO_ 2671793140 62547;
BA_ "DiagRequest" BO_ 2671793140 1;
BA_ "GenMsgILSupport" BO_ 2671793140 0;
BA_ "GenMsgSendType" BO_ 2671793140 8;
BA_ "DiagConnection" BO_ 2671792884 62546;
BA_ "DiagRequest" BO_ 2671792884 1;
BA_ "GenMsgILSupport" BO_ 2671792884 0;
BA_ "GenMsgSendType" BO_ 2671792884 8;
BA_ "DiagConnection" BO_ 2671792628 62545;
BA_ "DiagRequest" BO_ 2671792628 1;
BA_ "GenMsgILSupport" BO_ 2671792628 0;
BA_ "GenMsgSendType" BO_ 2671792628 8;
BA_ "DiagConnection" BO_ 2671792372 62544;
BA_ "DiagRequest" BO_ 2671792372 1;
BA_ "GenMsgILSupport" BO_ 2671792372 0;
BA_ "GenMsgSendType" BO_ 2671792372 8;
BA_ "DiagConnection" BO_ 2671788276 62528;
BA_ "DiagRequest" BO_ 2671788276 1;
BA_ "GenMsgILSupport" BO_ 2671788276 0;
BA_ "GenMsgSendType" BO_ 2671788276 8;
BA_ "DiagConnection" BO_ 2671784436 62513;
BA_ "DiagRequest" BO_ 2671784436 1;
BA_ "GenMsgILSupport" BO_ 2671784436 0;
BA_ "GenMsgSendType" BO_ 2671784436 8;
BA_ "DiagConnection" BO_ 2671784180 62512;
BA_ "DiagRequest" BO_ 2671784180 1;
BA_ "GenMsgILSupport" BO_ 2671784180 0;
BA_ "GenMsgSendType" BO_ 2671784180 8;
BA_ "DiagConnection" BO_ 2671781620 62502;
BA_ "DiagRequest" BO_ 2671781620 1;
BA_ "GenMsgILSupport" BO_ 2671781620 0;
BA_ "GenMsgSendType" BO_ 2671781620 8;
BA_ "DiagConnection" BO_ 2671781364 62501;
BA_ "DiagRequest" BO_ 2671781364 1;
BA_ "GenMsgILSupport" BO_ 2671781364 0;
BA_ "GenMsgSendType" BO_ 2671781364 8;
BA_ "DiagConnection" BO_ 2671781108 62500;
BA_ "DiagRequest" BO_ 2671781108 1;
BA_ "GenMsgILSupport" BO_ 2671781108 0;
BA_ "GenMsgSendType" BO_ 2671781108 8;
BA_ "DiagConnection" BO_ 2671780852 62499;
BA_ "DiagRequest" BO_ 2671780852 1;
BA_ "GenMsgILSupport" BO_ 2671780852 0;
BA_ "GenMsgSendType" BO_ 2671780852 8;
BA_ "DiagConnection" BO_ 2671780596 62498;
BA_ "DiagRequest" BO_ 2671780596 1;
BA_ "GenMsgILSupport" BO_ 2671780596 0;
BA_ "GenMsgSendType" BO_ 2671780596 8;
BA_ "DiagConnection" BO_ 2671780340 62497;
BA_ "DiagRequest" BO_ 2671780340 1;
BA_ "GenMsgILSupport" BO_ 2671780340 0;
BA_ "GenMsgSendType" BO_ 2671780340 8;
BA_ "DiagConnection" BO_ 2671780084 62496;
BA_ "DiagRequest" BO_ 2671780084 1;
BA_ "GenMsgILSupport" BO_ 2671780084 0;
BA_ "GenMsgSendType" BO_ 2671780084 8;
BA_ "DiagConnection" BO_ 2671778548 62490;
BA_ "DiagRequest" BO_ 2671778548 1;
BA_ "GenMsgILSupport" BO_ 2671778548 0;
BA_ "GenMsgSendType" BO_ 2671778548 8;
BA_ "DiagConnection" BO_ 2671778036 62488;
BA_ "DiagRequest" BO_ 2671778036 1;
BA_ "GenMsgILSupport" BO_ 2671778036 0;
BA_ "GenMsgSendType" BO_ 2671778036 8;
BA_ "DiagConnection" BO_ 2671775988 62480;
BA_ "DiagRequest" BO_ 2671775988 1;
BA_ "GenMsgILSupport" BO_ 2671775988 0;
BA_ "GenMsgSendType" BO_ 2671775988 8;
BA_ "DiagConnection" BO_ 2671830771 62438;
BA_ "DiagRequest" BO_ 2671830771 1;
BA_ "GenMsgILSupport" BO_ 2671830771 0;
BA_ "GenMsgSendType" BO_ 2671830771 8;
BA_ "DiagConnection" BO_ 2671830515 62437;
BA_ "DiagRequest" BO_ 2671830515 1;
BA_ "GenMsgILSupport" BO_ 2671830515 0;
BA_ "GenMsgSendType" BO_ 2671830515 8;
BA_ "DiagConnection" BO_ 2671821043 62400;
BA_ "DiagRequest" BO_ 2671821043 1;
BA_ "GenMsgILSupport" BO_ 2671821043 0;
BA_ "GenMsgSendType" BO_ 2671821043 8;
BA_ "DiagConnection" BO_ 2671813363 62370;
BA_ "DiagRequest" BO_ 2671813363 1;
BA_ "GenMsgILSupport" BO_ 2671813363 0;
BA_ "GenMsgSendType" BO_ 2671813363 8;
BA_ "DiagConnection" BO_ 2671813107 62369;
BA_ "DiagRequest" BO_ 2671813107 1;
BA_ "GenMsgILSupport" BO_ 2671813107 0;
BA_ "GenMsgSendType" BO_ 2671813107 8;
BA_ "DiagConnection" BO_ 2671812851 62368;
BA_ "DiagRequest" BO_ 2671812851 1;
BA_ "GenMsgILSupport" BO_ 2671812851 0;
BA_ "GenMsgSendType" BO_ 2671812851 8;
BA_ "DiagConnection" BO_ 2671810803 62360;
BA_ "DiagRequest" BO_ 2671810803 1;
BA_ "GenMsgILSupport" BO_ 2671810803 0;
BA_ "GenMsgSendType" BO_ 2671810803 8;
BA_ "DiagConnection" BO_ 2671801075 62322;
BA_ "DiagRequest" BO_ 2671801075 1;
BA_ "GenMsgILSupport" BO_ 2671801075 0;
BA_ "GenMsgSendType" BO_ 2671801075 8;
BA_ "DiagConnection" BO_ 2671800819 62321;
BA_ "DiagRequest" BO_ 2671800819 1;
BA_ "GenMsgILSupport" BO_ 2671800819 0;
BA_ "GenMsgSendType" BO_ 2671800819 8;
BA_ "DiagConnection" BO_ 2671793139 62291;
BA_ "DiagRequest" BO_ 2671793139 1;
BA_ "GenMsgILSupport" BO_ 2671793139 0;
BA_ "GenMsgSendType" BO_ 2671793139 8;
BA_ "DiagConnection" BO_ 2671792883 62290;
BA_ "DiagRequest" BO_ 2671792883 1;
BA_ "GenMsgILSupport" BO_ 2671792883 0;
BA_ "GenMsgSendType" BO_ 2671792883 8;
BA_ "DiagConnection" BO_ 2671792627 62289;
BA_ "DiagRequest" BO_ 2671792627 1;
BA_ "GenMsgILSupport" BO_ 2671792627 0;
BA_ "GenMsgSendType" BO_ 2671792627 8;
BA_ "DiagConnection" BO_ 2671792371 62288;
BA_ "DiagRequest" BO_ 2671792371 1;
BA_ "GenMsgILSupport" BO_ 2671792371 0;
BA_ "GenMsgSendType" BO_ 2671792371 8;
BA_ "DiagConnection" BO_ 2671788275 62272;
BA_ "DiagRequest" BO_ 2671788275 1;
BA_ "GenMsgILSupport" BO_ 2671788275 0;
BA_ "GenMsgSendType" BO_ 2671788275 8;
BA_ "DiagConnection" BO_ 2671784435 62257;
BA_ "DiagRequest" BO_ 2671784435 1;
BA_ "GenMsgILSupport" BO_ 2671784435 0;
BA_ "GenMsgSendType" BO_ 2671784435 8;
BA_ "DiagConnection" BO_ 2671784179 62256;
BA_ "DiagRequest" BO_ 2671784179 1;
BA_ "GenMsgILSupport" BO_ 2671784179 0;
BA_ "GenMsgSendType" BO_ 2671784179 8;
BA_ "DiagConnection" BO_ 2671781619 62246;
BA_ "DiagRequest" BO_ 2671781619 1;
BA_ "GenMsgILSupport" BO_ 2671781619 0;
BA_ "GenMsgSendType" BO_ 2671781619 8;
BA_ "DiagConnection" BO_ 2671781363 62245;
BA_ "DiagRequest" BO_ 2671781363 1;
BA_ "GenMsgILSupport" BO_ 2671781363 0;
BA_ "GenMsgSendType" BO_ 2671781363 8;
BA_ "DiagConnection" BO_ 2671781107 62244;
BA_ "DiagRequest" BO_ 2671781107 1;
BA_ "GenMsgILSupport" BO_ 2671781107 0;
BA_ "GenMsgSendType" BO_ 2671781107 8;
BA_ "DiagConnection" BO_ 2671780851 62243;
BA_ "DiagRequest" BO_ 2671780851 1;
BA_ "GenMsgILSupport" BO_ 2671780851 0;
BA_ "GenMsgSendType" BO_ 2671780851 8;
BA_ "DiagConnection" BO_ 2671780595 62242;
BA_ "DiagRequest" BO_ 2671780595 1;
BA_ "GenMsgILSupport" BO_ 2671780595 0;
BA_ "GenMsgSendType" BO_ 2671780595 8;
BA_ "DiagConnection" BO_ 2671780339 62241;
BA_ "DiagRequest" BO_ 2671780339 1;
BA_ "GenMsgILSupport" BO_ 2671780339 0;
BA_ "GenMsgSendType" BO_ 2671780339 8;
BA_ "DiagConnection" BO_ 2671780083 62240;
BA_ "DiagRequest" BO_ 2671780083 1;
BA_ "GenMsgILSupport" BO_ 2671780083 0;
BA_ "GenMsgSendType" BO_ 2671780083 8;
BA_ "DiagConnection" BO_ 2671778547 62234;
BA_ "DiagRequest" BO_ 2671778547 1;
BA_ "GenMsgILSupport" BO_ 2671778547 0;
BA_ "GenMsgSendType" BO_ 2671778547 8;
BA_ "DiagConnection" BO_ 2671778035 62232;
BA_ "DiagRequest" BO_ 2671778035 1;
BA_ "GenMsgILSupport" BO_ 2671778035 0;
BA_ "GenMsgSendType" BO_ 2671778035 8;
BA_ "DiagConnection" BO_ 2671775987 62224;
BA_ "DiagRequest" BO_ 2671775987 1;
BA_ "GenMsgILSupport" BO_ 2671775987 0;
BA_ "GenMsgSendType" BO_ 2671775987 8;
BA_ "GenMsgSendType" BO_ 2147485168 8;
BA_ "GenMsgDelayTime" BO_ 2147485168 75;
BA_ "GenMsgCycleTime" BO_ 2147485136 1000;
BA_ "GenMsgDelayTime" BO_ 2147485136 85;
BA_ "GenMsgStartDelayTime" BO_ 2147485136 15;
BA_ "GenMsgSendType" BO_ 2147485150 8;
BA_ "GenMsgDelayTime" BO_ 2147485150 75;
BA_ "GenMsgCycleTime" BO_ 2147485167 1000;
BA_ "GenMsgDelayTime" BO_ 2147485167 85;
BA_ "GenMsgStartDelayTime" BO_ 2147485167 25;
BA_ "GenMsgSendType" BO_ 2147485165 8;
BA_ "GenMsgDelayTime" BO_ 2147485165 75;
BA_ "GenMsgSendType" BO_ 2147485164 8;
BA_ "GenMsgDelayTime" BO_ 2147485164 75;
BA_ "GenMsgSendType" BO_ 2147485163 8;
BA_ "GenMsgDelayTime" BO_ 2147485163 75;
BA_ "GenMsgSendType" BO_ 2147485162 8;
BA_ "GenMsgDelayTime" BO_ 2147485162 75;
BA_ "GenMsgSendType" BO_ 2147485161 8;
BA_ "GenMsgDelayTime" BO_ 2147485161 75;
BA_ "GenMsgSendType" BO_ 2147485145 8;
BA_ "GenMsgDelayTime" BO_ 2147485145 75;
BA_ "GenMsgSendType" BO_ 2147485144 8;
BA_ "GenMsgDelayTime" BO_ 2147485144 75;
BA_ "GenMsgSendType" BO_ 2147485160 8;
BA_ "GenMsgDelayTime" BO_ 2147485160 75;
BA_ "GenMsgSendType" BO_ 2147485147 8;
BA_ "GenMsgDelayTime" BO_ 2147485147 75;
BA_ "GenMsgSendType" BO_ 2147485139 8;
BA_ "GenMsgDelayTime" BO_ 2147485139 75;
BA_ "GenMsgCycleTime" BO_ 2147485159 1000;
BA_ "GenMsgDelayTime" BO_ 2147485159 85;
BA_ "GenMsgStartDelayTime" BO_ 2147485159 25;
BA_ "GenMsgSendType" BO_ 2147485141 8;
BA_ "GenMsgDelayTime" BO_ 2147485141 75;
BA_ "GenMsgSendType" BO_ 2147485158 8;
BA_ "GenMsgDelayTime" BO_ 2147485158 75;
BA_ "GenMsgCycleTime" BO_ 2147485157 1000;
BA_ "GenMsgDelayTime" BO_ 2147485157 85;
BA_ "GenMsgStartDelayTime" BO_ 2147485157 25;
BA_ "GenMsgCycleTime" BO_ 2147485156 1000;
BA_ "GenMsgDelayTime" BO_ 2147485156 85;
BA_ "GenMsgStartDelayTime" BO_ 2147485156 145;
BA_ "GenMsgSendType" BO_ 2147485155 8;
BA_ "GenMsgDelayTime" BO_ 2147485155 75;
BA_ "GenMsgSendType" BO_ 2147485138 8;
BA_ "GenMsgDelayTime" BO_ 2147485138 75;
BA_ "GenMsgSendType" BO_ 2147485142 8;
BA_ "GenMsgDelayTime" BO_ 2147485142 75;
BA_ "GenMsgCycleTime" BO_ 2147485154 1000;
BA_ "GenMsgDelayTime" BO_ 2147485154 85;
BA_ "GenMsgStartDelayTime" BO_ 2147485154 35;
BA_ "GenMsgSendType" BO_ 2147485153 8;
BA_ "GenMsgDelayTime" BO_ 2147485153 85;
BA_ "GenSigCycleTime" SG_ 2147485039 OilPrediction_Quality 100;
BA_ "GenSigCycleTimeActive" SG_ 2147485039 OilPrediction_Quality 100;
BA_ "GenSigStartValue" SG_ 2147485039 OilPrediction_Quality 7;
BA_ "Platform_VMCU1_Sig" SG_ 2147485039 OilPrediction_Quality 1;
BA_ "GenSigCycleTime" SG_ 2147485039 TimeLeftToVehSpdReduction_OBD 100;
BA_ "GenSigCycleTimeActive" SG_ 2147485039 TimeLeftToVehSpdReduction_OBD 100;
BA_ "GenSigStartValue" SG_ 2147485039 TimeLeftToVehSpdReduction_OBD 511;
BA_ "Platform_VMCU1_Sig" SG_ 2147485039 TimeLeftToVehSpdReduction_OBD 1;
BA_ "GenSigCycleTime" SG_ 2147485039 OilPrediction_RemainDist 100;
BA_ "GenSigCycleTimeActive" SG_ 2147485039 OilPrediction_RemainDist 100;
BA_ "GenSigStartValue" SG_ 2147485039 OilPrediction_RemainDist 65535;
BA_ "Platform_VMCU1_Sig" SG_ 2147485039 OilPrediction_RemainDist 1;
BA_ "GenSigCycleTime" SG_ 2147485039 TimeToCorrectOilLevel_ISig_4 100;
BA_ "GenSigCycleTimeActive" SG_ 2147485039 TimeToCorrectOilLevel_ISig_4 100;
BA_ "GenSigStartValue" SG_ 2147485039 TimeToCorrectOilLevel_ISig_4 255;
BA_ "Platform_VMCU1_Sig" SG_ 2147485039 TimeToCorrectOilLevel_ISig_4 1;
BA_ "GenSigCycleTime" SG_ 2147485039 OilPrediction_RemainTime 100;
BA_ "GenSigCycleTimeActive" SG_ 2147485039 OilPrediction_RemainTime 100;
BA_ "GenSigStartValue" SG_ 2147485039 OilPrediction_RemainTime 65535;
BA_ "Platform_VMCU1_Sig" SG_ 2147485039 OilPrediction_RemainTime 1;
BA_ "GenSigCycleTime" SG_ 2147485039 OilPrediction_Status 100;
BA_ "GenSigCycleTimeActive" SG_ 2147485039 OilPrediction_Status 100;
BA_ "GenSigStartValue" SG_ 2147485039 OilPrediction_Status 7;
BA_ "Platform_VMCU1_Sig" SG_ 2147485039 OilPrediction_Status 1;
BA_ "GenSigCycleTime" SG_ 2147484924 EngineCoolingFanSpeed_ISig_4 100;
BA_ "GenSigCycleTimeActive" SG_ 2147484924 EngineCoolingFanSpeed_ISig_4 100;
BA_ "GenSigStartValue" SG_ 2147484924 EngineCoolingFanSpeed_ISig_4 65535;
BA_ "Platform_VMCU1_Sig" SG_ 2147484924 EngineCoolingFanSpeed_ISig_4 1;
BA_ "GenSigCycleTime" SG_ 2147484924 DMSDriverFollow 100;
BA_ "GenSigCycleTimeActive" SG_ 2147484924 DMSDriverFollow 100;
BA_ "GenSigStartValue" SG_ 2147484924 DMSDriverFollow 3;
BA_ "GenSigMaxLatency" SG_ 2147484924 DMSDriverFollow 270;
BA_ "Platform_VMCU1_Sig" SG_ 2147484924 DMSDriverFollow 1;
BA_ "GenSigCycleTime" SG_ 2147484924 CoolantPumpEngagementStatus_ISig 100;
BA_ "GenSigCycleTimeActive" SG_ 2147484924 CoolantPumpEngagementStatus_ISig 100;
BA_ "GenSigStartValue" SG_ 2147484924 CoolantPumpEngagementStatus_ISig 255;
BA_ "Platform_VMCU1_Sig" SG_ 2147484924 CoolantPumpEngagementStatus_ISig 1;
BA_ "SystemSignalLongSymbol" SG_ 2147484924 CoolantPumpEngagementStatus_ISig "CoolantPumpEngagementStatus_ISig_4";
BA_ "GenSigCycleTime" SG_ 2147484924 AverageFuelEconomy_ISig_4 100;
BA_ "GenSigCycleTimeActive" SG_ 2147484924 AverageFuelEconomy_ISig_4 100;
BA_ "GenSigMaxLatency" SG_ 2147484924 AverageFuelEconomy_ISig_4 270;
BA_ "Platform_VMCU1_Sig" SG_ 2147484924 AverageFuelEconomy_ISig_4 1;
BA_ "GenSigCycleTime" SG_ 2147484924 EngineGasRate 100;
BA_ "GenSigCycleTimeActive" SG_ 2147484924 EngineGasRate 100;
BA_ "GenSigStartValue" SG_ 2147484924 EngineGasRate 65535;
BA_ "Platform_VMCU1_Sig" SG_ 2147484924 EngineGasRate 1;
BA_ "GenSigCycleTime" SG_ 2147484924 FuelEcoEngStatus 100;
BA_ "GenSigCycleTimeActive" SG_ 2147484924 FuelEcoEngStatus 100;
BA_ "GenSigStartValue" SG_ 2147484924 FuelEcoEngStatus 3;
BA_ "Platform_VMCU1_Sig" SG_ 2147484924 FuelEcoEngStatus 1;
BA_ "GenSigCycleTime" SG_ 2147484939 DrainPrimingStatus 100;
BA_ "GenSigCycleTimeActive" SG_ 2147484939 DrainPrimingStatus 100;
BA_ "GenSigStartValue" SG_ 2147484939 DrainPrimingStatus 7;
BA_ "GenSigMaxLatency" SG_ 2147484939 DrainPrimingStatus 258;
BA_ "Platform_VMCU1_Sig" SG_ 2147484939 DrainPrimingStatus 1;
BA_ "SeToolAncestorID_SIGNAL" SG_ 2147484939 DrainPrimingStatus "x0000001D041410EE";
BA_ "SeToolItemID_SIGNAL" SG_ 2147484939 DrainPrimingStatus "x0000001D042EB380";
BA_ "SeToolName_SIGNAL" SG_ 2147484939 DrainPrimingStatus "DrainPrimingStatus";
BA_ "SeToolVersion_SIGNAL" SG_ 2147484939 DrainPrimingStatus "2";
BA_ "GenSigCycleTime" SG_ 2147484939 CoolantTempHigh_ISig_4 100;
BA_ "GenSigCycleTimeActive" SG_ 2147484939 CoolantTempHigh_ISig_4 100;
BA_ "GenSigStartValue" SG_ 2147484939 CoolantTempHigh_ISig_4 7;
BA_ "GenSigMaxLatency" SG_ 2147484939 CoolantTempHigh_ISig_4 258;
BA_ "Platform_VMCU1_Sig" SG_ 2147484939 CoolantTempHigh_ISig_4 1;
BA_ "SeToolAncestorID_SIGNAL" SG_ 2147484939 CoolantTempHigh_ISig_4 "x0000001D0412B8A6";
BA_ "SeToolItemID_SIGNAL" SG_ 2147484939 CoolantTempHigh_ISig_4 "x0000001D0412B8A6";
BA_ "SeToolName_SIGNAL" SG_ 2147484939 CoolantTempHigh_ISig_4 "CoolantTempHigh";
BA_ "SeToolVersion_SIGNAL" SG_ 2147484939 CoolantTempHigh_ISig_4 "1";
BA_ "GenSigCycleTime" SG_ 2147484939 CoolantLevelLow_ISig_4 100;
BA_ "GenSigCycleTimeActive" SG_ 2147484939 CoolantLevelLow_ISig_4 100;
BA_ "GenSigStartValue" SG_ 2147484939 CoolantLevelLow_ISig_4 7;
BA_ "GenSigMaxLatency" SG_ 2147484939 CoolantLevelLow_ISig_4 258;
BA_ "Platform_VMCU1_Sig" SG_ 2147484939 CoolantLevelLow_ISig_4 1;
BA_ "SeToolAncestorID_SIGNAL" SG_ 2147484939 CoolantLevelLow_ISig_4 "x0000001D0412B8A4";
BA_ "SeToolItemID_SIGNAL" SG_ 2147484939 CoolantLevelLow_ISig_4 "x0000001D0412B8A4";
BA_ "SeToolName_SIGNAL" SG_ 2147484939 CoolantLevelLow_ISig_4 "CoolantLevelLow";
BA_ "SeToolVersion_SIGNAL" SG_ 2147484939 CoolantLevelLow_ISig_4 "1";
BA_ "GenSigCycleTime" SG_ 2147484939 AutoWheelBrakesStatus 100;
BA_ "GenSigCycleTimeActive" SG_ 2147484939 AutoWheelBrakesStatus 100;
BA_ "GenSigStartValue" SG_ 2147484939 AutoWheelBrakesStatus 7;
BA_ "GenSigCycleTime" SG_ 2147484939 OilPressureLow_ISig_4 100;
BA_ "GenSigCycleTimeActive" SG_ 2147484939 OilPressureLow_ISig_4 100;
BA_ "GenSigStartValue" SG_ 2147484939 OilPressureLow_ISig_4 7;
BA_ "GenSigMaxLatency" SG_ 2147484939 OilPressureLow_ISig_4 513;
BA_ "Platform_VMCU1_Sig" SG_ 2147484939 OilPressureLow_ISig_4 1;
BA_ "SeToolAncestorID_SIGNAL" SG_ 2147484939 OilPressureLow_ISig_4 "x0000001D0412B8B1";
BA_ "SeToolItemID_SIGNAL" SG_ 2147484939 OilPressureLow_ISig_4 "x0000001D0412B8B1";
BA_ "SeToolName_SIGNAL" SG_ 2147484939 OilPressureLow_ISig_4 "OilPressureLow";
BA_ "SeToolVersion_SIGNAL" SG_ 2147484939 OilPressureLow_ISig_4 "1";
BA_ "GenSigCycleTime" SG_ 2147484939 EngineTotalFuelConsumed_ISig_4 100;
BA_ "GenSigCycleTimeActive" SG_ 2147484939 EngineTotalFuelConsumed_ISig_4 100;
BA_ "GenSigStartValue" SG_ 2147484939 EngineTotalFuelConsumed_ISig_4 4294967295;
BA_ "GenSigMaxLatency" SG_ 2147484939 EngineTotalFuelConsumed_ISig_4 258;
BA_ "Platform_VMCU1_Sig" SG_ 2147484939 EngineTotalFuelConsumed_ISig_4 1;
BA_ "SeToolAncestorID_SIGNAL" SG_ 2147484939 EngineTotalFuelConsumed_ISig_4 "x0000001D04172521";
BA_ "SeToolItemID_SIGNAL" SG_ 2147484939 EngineTotalFuelConsumed_ISig_4 "x0000001D04172521";
BA_ "SeToolName_SIGNAL" SG_ 2147484939 EngineTotalFuelConsumed_ISig_4 "EngineTotalFuelConsumed";
BA_ "SeToolVersion_SIGNAL" SG_ 2147484939 EngineTotalFuelConsumed_ISig_4 "1";
BA_ "GenSigCycleTime" SG_ 2147484939 TopGearMode_ISig_4 100;
BA_ "GenSigCycleTimeActive" SG_ 2147484939 TopGearMode_ISig_4 100;
BA_ "GenSigStartValue" SG_ 2147484939 TopGearMode_ISig_4 3;
BA_ "Platform_VMCU1_Sig" SG_ 2147484939 TopGearMode_ISig_4 1;
BA_ "GenSigCycleTime" SG_ 2147484939 OilLevelLow_ISig_4 100;
BA_ "GenSigCycleTimeActive" SG_ 2147484939 OilLevelLow_ISig_4 100;
BA_ "GenSigStartValue" SG_ 2147484939 OilLevelLow_ISig_4 7;
BA_ "GenSigMaxLatency" SG_ 2147484939 OilLevelLow_ISig_4 513;
BA_ "Platform_VMCU1_Sig" SG_ 2147484939 OilLevelLow_ISig_4 1;
BA_ "SeToolAncestorID_SIGNAL" SG_ 2147484939 OilLevelLow_ISig_4 "x0000001D0412B8AA";
BA_ "SeToolItemID_SIGNAL" SG_ 2147484939 OilLevelLow_ISig_4 "x0000001D0412B8AA";
BA_ "SeToolName_SIGNAL" SG_ 2147484939 OilLevelLow_ISig_4 "OilLevelLow";
BA_ "SeToolVersion_SIGNAL" SG_ 2147484939 OilLevelLow_ISig_4 "1";
BA_ "GenSigCycleTime" SG_ 2147484939 BarometricPressure_ISig_4 100;
BA_ "GenSigCycleTimeActive" SG_ 2147484939 BarometricPressure_ISig_4 100;
BA_ "GenSigStartValue" SG_ 2147484939 BarometricPressure_ISig_4 255;
BA_ "GenSigMaxLatency" SG_ 2147484939 BarometricPressure_ISig_4 258;
BA_ "Platform_VMCU1_Sig" SG_ 2147484939 BarometricPressure_ISig_4 1;
BA_ "SeToolAncestorID_SIGNAL" SG_ 2147484939 BarometricPressure_ISig_4 "x0000001D040FEBBD";
BA_ "SeToolItemID_SIGNAL" SG_ 2147484939 BarometricPressure_ISig_4 "x0000001D040FEBBD";
BA_ "SeToolName_SIGNAL" SG_ 2147484939 BarometricPressure_ISig_4 "BarometricPressure";
BA_ "SeToolVersion_SIGNAL" SG_ 2147484939 BarometricPressure_ISig_4 "1";
BA_ "GenSigCycleTime" SG_ 2147484939 InletAirHeaterStatus1 100;
BA_ "GenSigCycleTimeActive" SG_ 2147484939 InletAirHeaterStatus1 100;
BA_ "GenSigStartValue" SG_ 2147484939 InletAirHeaterStatus1 3;
BA_ "GenSigMaxLatency" SG_ 2147484939 InletAirHeaterStatus1 258;
BA_ "Platform_VMCU1_Sig" SG_ 2147484939 InletAirHeaterStatus1 1;
BA_ "SeToolAncestorID_SIGNAL" SG_ 2147484939 InletAirHeaterStatus1 "x0000001D04130F0B";
BA_ "SeToolItemID_SIGNAL" SG_ 2147484939 InletAirHeaterStatus1 "x0000001D043210A4";
BA_ "SeToolName_SIGNAL" SG_ 2147484939 InletAirHeaterStatus1 "InletAirHeaterStatus1";
BA_ "SeToolVersion_SIGNAL" SG_ 2147484939 InletAirHeaterStatus1 "2";
BA_ "GenSigCycleTime" SG_ 2147484927 FuelFilterClogged 100;
BA_ "GenSigCycleTimeActive" SG_ 2147484927 FuelFilterClogged 100;
BA_ "GenSigStartValue" SG_ 2147484927 FuelFilterClogged 7;
BA_ "GenSigMaxLatency" SG_ 2147484927 FuelFilterClogged 257;
BA_ "Platform_VMCU1_Sig" SG_ 2147484927 FuelFilterClogged 1;
BA_ "SeToolAncestorID_SIGNAL" SG_ 2147484927 FuelFilterClogged "x0000001D04181612";
BA_ "SeToolItemID_SIGNAL" SG_ 2147484927 FuelFilterClogged "x0000001D04181612";
BA_ "SeToolName_SIGNAL" SG_ 2147484927 FuelFilterClogged "FuelFilterClogged";
BA_ "SeToolVersion_SIGNAL" SG_ 2147484927 FuelFilterClogged "1";
BA_ "GenSigCycleTime" SG_ 2147484927 EngineAirInletTemperature 100;
BA_ "GenSigCycleTimeActive" SG_ 2147484927 EngineAirInletTemperature 100;
BA_ "GenSigStartValue" SG_ 2147484927 EngineAirInletTemperature 255;
BA_ "GenSigMaxLatency" SG_ 2147484927 EngineAirInletTemperature 257;
BA_ "Platform_VMCU1_Sig" SG_ 2147484927 EngineAirInletTemperature 1;
BA_ "SeToolAncestorID_SIGNAL" SG_ 2147484927 EngineAirInletTemperature "x0000001D041943AE";
BA_ "SeToolItemID_SIGNAL" SG_ 2147484927 EngineAirInletTemperature "x0000001D0421DC80";
BA_ "SeToolName_SIGNAL" SG_ 2147484927 EngineAirInletTemperature "EngineAirInletTemperature";
BA_ "SeToolVersion_SIGNAL" SG_ 2147484927 EngineAirInletTemperature "2";
BA_ "GenSigCycleTime" SG_ 2147484927 StarterMotorRecoveryTime 100;
BA_ "GenSigCycleTimeActive" SG_ 2147484927 StarterMotorRecoveryTime 100;
BA_ "GenSigStartValue" SG_ 2147484927 StarterMotorRecoveryTime 65535;
BA_ "GenSigMaxLatency" SG_ 2147484927 StarterMotorRecoveryTime 257;
BA_ "Platform_VMCU1_Sig" SG_ 2147484927 StarterMotorRecoveryTime 1;
BA_ "SeToolAncestorID_SIGNAL" SG_ 2147484927 StarterMotorRecoveryTime "x0000001D0421E90A";
BA_ "SeToolItemID_SIGNAL" SG_ 2147484927 StarterMotorRecoveryTime "x0000001D0421E90A";
BA_ "SeToolName_SIGNAL" SG_ 2147484927 StarterMotorRecoveryTime "StarterMotorRecoveryTime";
BA_ "SeToolVersion_SIGNAL" SG_ 2147484927 StarterMotorRecoveryTime "1";
BA_ "GenSigCycleTime" SG_ 2147484927 EngineFanOverspeed 100;
BA_ "GenSigCycleTimeActive" SG_ 2147484927 EngineFanOverspeed 100;
BA_ "GenSigStartValue" SG_ 2147484927 EngineFanOverspeed 3;
BA_ "GenSigCycleTime" SG_ 2147484927 AppliedVehicleSpeedLimit 100;
BA_ "GenSigCycleTimeActive" SG_ 2147484927 AppliedVehicleSpeedLimit 100;
BA_ "GenSigStartValue" SG_ 2147484927 AppliedVehicleSpeedLimit 65535;
BA_ "Platform_VMCU1_Sig" SG_ 2147484927 AppliedVehicleSpeedLimit 1;
BA_ "GenSigCycleTime" SG_ 2147484927 EngineProtDerateStat 100;
BA_ "GenSigCycleTimeActive" SG_ 2147484927 EngineProtDerateStat 100;
BA_ "GenSigStartValue" SG_ 2147484927 EngineProtDerateStat 3;
BA_ "Platform_VMCU1_Sig" SG_ 2147484927 EngineProtDerateStat 1;
BA_ "GenSigCycleTime" SG_ 2147484927 CoolantTempGaugeAdjustment 100;
BA_ "GenSigCycleTimeActive" SG_ 2147484927 CoolantTempGaugeAdjustment 100;
BA_ "GenSigStartValue" SG_ 2147484927 CoolantTempGaugeAdjustment 255;
BA_ "Platform_VMCU1_Sig" SG_ 2147484927 CoolantTempGaugeAdjustment 1;
BA_ "GenSigCycleTime" SG_ 2147484927 AirFilterPressureDrop 100;
BA_ "GenSigCycleTimeActive" SG_ 2147484927 AirFilterPressureDrop 100;
BA_ "GenSigStartValue" SG_ 2147484927 AirFilterPressureDrop 7;
BA_ "GenSigCycleTime" SG_ 2147484381 AirFilter_AirMassFlowValidated 100;
BA_ "GenSigCycleTimeActive" SG_ 2147484381 AirFilter_AirMassFlowValidated 100;
BA_ "GenSigStartValue" SG_ 2147484381 AirFilter_AirMassFlowValidated 255;
BA_ "GenSigCycleTime" SG_ 2147484381 DPF_LimitedSpeedDuetoInhibit 100;
BA_ "GenSigCycleTimeActive" SG_ 2147484381 DPF_LimitedSpeedDuetoInhibit 100;
BA_ "GenSigStartValue" SG_ 2147484381 DPF_LimitedSpeedDuetoInhibit 7;
BA_ "Platform_VMCU1_Sig" SG_ 2147484381 DPF_LimitedSpeedDuetoInhibit 1;
BA_ "GenSigCycleTime" SG_ 2147484381 XARSystemState 100;
BA_ "GenSigCycleTimeActive" SG_ 2147484381 XARSystemState 100;
BA_ "GenSigStartValue" SG_ 2147484381 XARSystemState 3;
BA_ "GenSigMaxLatency" SG_ 2147484381 XARSystemState 58;
BA_ "Platform_VMCU1_Sig" SG_ 2147484381 XARSystemState 1;
BA_ "SeToolAncestorID_SIGNAL" SG_ 2147484381 XARSystemState "x0000001D0425407E";
BA_ "SeToolItemID_SIGNAL" SG_ 2147484381 XARSystemState "x0000001D0425407E";
BA_ "SeToolName_SIGNAL" SG_ 2147484381 XARSystemState "XARSystemState";
BA_ "SeToolVersion_SIGNAL" SG_ 2147484381 XARSystemState "1";
BA_ "GenSigCycleTime" SG_ 2147484381 XARActiveControlMode 100;
BA_ "GenSigCycleTimeActive" SG_ 2147484381 XARActiveControlMode 100;
BA_ "GenSigStartValue" SG_ 2147484381 XARActiveControlMode 7;
BA_ "GenSigMaxLatency" SG_ 2147484381 XARActiveControlMode 58;
BA_ "Platform_VMCU1_Sig" SG_ 2147484381 XARActiveControlMode 1;
BA_ "SeToolAncestorID_SIGNAL" SG_ 2147484381 XARActiveControlMode "x0000001D04254078";
BA_ "SeToolItemID_SIGNAL" SG_ 2147484381 XARActiveControlMode "x0000001D043C593D";
BA_ "SeToolName_SIGNAL" SG_ 2147484381 XARActiveControlMode "XARActiveControlMode";
BA_ "SeToolVersion_SIGNAL" SG_ 2147484381 XARActiveControlMode "2";
BA_ "GenSigCycleTime" SG_ 2147484381 AirFilter_Pressure 100;
BA_ "GenSigCycleTimeActive" SG_ 2147484381 AirFilter_Pressure 100;
BA_ "GenSigStartValue" SG_ 2147484381 AirFilter_Pressure 2047;
BA_ "GenSigCycleTime" SG_ 2147484381 CCBSetSpeedApplied 100;
BA_ "GenSigCycleTimeActive" SG_ 2147484381 CCBSetSpeedApplied 100;
BA_ "GenSigStartValue" SG_ 2147484381 CCBSetSpeedApplied 255;
BA_ "Platform_VMCU1_Sig" SG_ 2147484381 CCBSetSpeedApplied 1;
BA_ "GenSigCycleTime" SG_ 2147484367 CCControllerMode_ISig_4 100;
BA_ "GenSigCycleTimeActive" SG_ 2147484367 CCControllerMode_ISig_4 100;
BA_ "GenSigStartValue" SG_ 2147484367 CCControllerMode_ISig_4 7;
BA_ "GenSigMaxLatency" SG_ 2147484367 CCControllerMode_ISig_4 55;
BA_ "Platform_VMCU1_Sig" SG_ 2147484367 CCControllerMode_ISig_4 1;
BA_ "SeToolAncestorID_SIGNAL" SG_ 2147484367 CCControllerMode_ISig_4 "x0000001D0422FAAD";
BA_ "SeToolItemID_SIGNAL" SG_ 2147484367 CCControllerMode_ISig_4 "x0000001D043FE012";
BA_ "SeToolName_SIGNAL" SG_ 2147484367 CCControllerMode_ISig_4 "CCControllerMode";
BA_ "SeToolVersion_SIGNAL" SG_ 2147484367 CCControllerMode_ISig_4 "3";
BA_ "GenSigCycleTime" SG_ 2147484367 CrankcasePressureHigh_ISig_4 100;
BA_ "GenSigCycleTimeActive" SG_ 2147484367 CrankcasePressureHigh_ISig_4 100;
BA_ "GenSigStartValue" SG_ 2147484367 CrankcasePressureHigh_ISig_4 3;
BA_ "Platform_VMCU1_Sig" SG_ 2147484367 CrankcasePressureHigh_ISig_4 1;
BA_ "GenSigCycleTime" SG_ 2147484367 EngineSystemPowerDownAck 100;
BA_ "GenSigCycleTimeActive" SG_ 2147484367 EngineSystemPowerDownAck 100;
BA_ "GenSigStartValue" SG_ 2147484367 EngineSystemPowerDownAck 3;
BA_ "GenSigMaxLatency" SG_ 2147484367 EngineSystemPowerDownAck 55;
BA_ "Platform_VMCU1_Sig" SG_ 2147484367 EngineSystemPowerDownAck 1;
BA_ "SeToolAncestorID_SIGNAL" SG_ 2147484367 EngineSystemPowerDownAck "x0000001D0436C68E";
BA_ "SeToolItemID_SIGNAL" SG_ 2147484367 EngineSystemPowerDownAck "x0000001D0436C68E";
BA_ "SeToolName_SIGNAL" SG_ 2147484367 EngineSystemPowerDownAck "EngineSystemPowerDownAck";
BA_ "SeToolVersion_SIGNAL" SG_ 2147484367 EngineSystemPowerDownAck "1";
BA_ "GenSigCycleTime" SG_ 2147484367 EngineActiveStatus_ISig_4 100;
BA_ "GenSigCycleTimeActive" SG_ 2147484367 EngineActiveStatus_ISig_4 100;
BA_ "GenSigStartValue" SG_ 2147484367 EngineActiveStatus_ISig_4 15;
BA_ "GenSigMaxLatency" SG_ 2147484367 EngineActiveStatus_ISig_4 55;
BA_ "Platform_VMCU1_Sig" SG_ 2147484367 EngineActiveStatus_ISig_4 1;
BA_ "SeToolAncestorID_SIGNAL" SG_ 2147484367 EngineActiveStatus_ISig_4 "x0000001D0421DFD5";
BA_ "SeToolItemID_SIGNAL" SG_ 2147484367 EngineActiveStatus_ISig_4 "x0000001D0421DFD5";
BA_ "SeToolName_SIGNAL" SG_ 2147484367 EngineActiveStatus_ISig_4 "EngineActiveStatus";
BA_ "SeToolVersion_SIGNAL" SG_ 2147484367 EngineActiveStatus_ISig_4 "1";
BA_ "GenSigCycleTime" SG_ 2147484367 XRSLControllerMode 100;
BA_ "GenSigCycleTimeActive" SG_ 2147484367 XRSLControllerMode 100;
BA_ "GenSigStartValue" SG_ 2147484367 XRSLControllerMode 3;
BA_ "Platform_VMCU1_Sig" SG_ 2147484367 XRSLControllerMode 1;
BA_ "GenSigCycleTime" SG_ 2147484367 RegenInhibDueHeight 100;
BA_ "GenSigCycleTimeActive" SG_ 2147484367 RegenInhibDueHeight 100;
BA_ "GenSigStartValue" SG_ 2147484367 RegenInhibDueHeight 3;
BA_ "Platform_VMCU1_Sig" SG_ 2147484367 RegenInhibDueHeight 1;
BA_ "GenSigCycleTime" SG_ 2147484367 ExhManif_AirInjActive_ISig_4 100;
BA_ "GenSigCycleTimeActive" SG_ 2147484367 ExhManif_AirInjActive_ISig_4 100;
BA_ "GenSigStartValue" SG_ 2147484367 ExhManif_AirInjActive_ISig_4 3;
BA_ "GenSigCycleTime" SG_ 2147484367 CCBControllerMode 100;
BA_ "GenSigCycleTimeActive" SG_ 2147484367 CCBControllerMode 100;
BA_ "GenSigStartValue" SG_ 2147484367 CCBControllerMode 7;
BA_ "GenSigMaxLatency" SG_ 2147484367 CCBControllerMode 55;
BA_ "Platform_VMCU1_Sig" SG_ 2147484367 CCBControllerMode 1;
BA_ "SeToolAncestorID_SIGNAL" SG_ 2147484367 CCBControllerMode "x0000001D043FE01A";
BA_ "SeToolItemID_SIGNAL" SG_ 2147484367 CCBControllerMode "x0000001D043FE01A";
BA_ "SeToolName_SIGNAL" SG_ 2147484367 CCBControllerMode "CCBControllerMode";
BA_ "SeToolVersion_SIGNAL" SG_ 2147484367 CCBControllerMode "1";
BA_ "GenSigCycleTime" SG_ 2147484367 InhibitIdleShutdownStatus 100;
BA_ "GenSigCycleTimeActive" SG_ 2147484367 InhibitIdleShutdownStatus 100;
BA_ "GenSigStartValue" SG_ 2147484367 InhibitIdleShutdownStatus 7;
BA_ "GenSigMaxLatency" SG_ 2147484367 InhibitIdleShutdownStatus 55;
BA_ "Platform_VMCU1_Sig" SG_ 2147484367 InhibitIdleShutdownStatus 1;
BA_ "SeToolAncestorID_SIGNAL" SG_ 2147484367 InhibitIdleShutdownStatus "x0000001D041620E7";
BA_ "SeToolItemID_SIGNAL" SG_ 2147484367 InhibitIdleShutdownStatus "x0000001D043C6713";
BA_ "SeToolName_SIGNAL" SG_ 2147484367 InhibitIdleShutdownStatus "InhibitIdleShutdownStatus";
BA_ "SeToolVersion_SIGNAL" SG_ 2147484367 InhibitIdleShutdownStatus "2";
BA_ "GenSigCycleTime" SG_ 2147484367 EngCompartmentStopSwitchStat 100;
BA_ "GenSigCycleTimeActive" SG_ 2147484367 EngCompartmentStopSwitchStat 100;
BA_ "GenSigStartValue" SG_ 2147484367 EngCompartmentStopSwitchStat 3;
BA_ "GenSigMaxLatency" SG_ 2147484367 EngCompartmentStopSwitchStat 55;
BA_ "Platform_VMCU1_Sig" SG_ 2147484367 EngCompartmentStopSwitchStat 1;
BA_ "SeToolAncestorID_SIGNAL" SG_ 2147484367 EngCompartmentStopSwitchStat "x0000001D041308F3";
BA_ "SeToolItemID_SIGNAL" SG_ 2147484367 EngCompartmentStopSwitchStat "x0000001D0428D42A";
BA_ "SeToolName_SIGNAL" SG_ 2147484367 EngCompartmentStopSwitchStat "EngCompartmentStopSwitchStat";
BA_ "SeToolVersion_SIGNAL" SG_ 2147484367 EngCompartmentStopSwitchStat "2";
BA_ "GenSigCycleTime" SG_ 2147484367 EngineAirInletPressure 100;
BA_ "GenSigCycleTimeActive" SG_ 2147484367 EngineAirInletPressure 100;
BA_ "GenSigStartValue" SG_ 2147484367 EngineAirInletPressure 255;
BA_ "Platform_VMCU1_Sig" SG_ 2147484367 EngineAirInletPressure 1;
BA_ "GenSigCycleTime" SG_ 2147484367 EngineStartAuth_rqst 100;
BA_ "GenSigCycleTimeActive" SG_ 2147484367 EngineStartAuth_rqst 100;
BA_ "GenSigStartValue" SG_ 2147484367 EngineStartAuth_rqst 7;
BA_ "Platform_VMCU1_Sig" SG_ 2147484367 EngineStartAuth_rqst 1;
BA_ "GenSigCycleTime" SG_ 2147484367 IntakeAirTemperatureAlert 100;
BA_ "GenSigCycleTimeActive" SG_ 2147484367 IntakeAirTemperatureAlert 100;
BA_ "GenSigStartValue" SG_ 2147484367 IntakeAirTemperatureAlert 3;
BA_ "Platform_VMCU1_Sig" SG_ 2147484367 IntakeAirTemperatureAlert 1;
BA_ "GenSigCycleTime" SG_ 2147484367 EngineOilTempHigh_ISig_4 100;
BA_ "GenSigCycleTimeActive" SG_ 2147484367 EngineOilTempHigh_ISig_4 100;
BA_ "GenSigStartValue" SG_ 2147484367 EngineOilTempHigh_ISig_4 7;
BA_ "Platform_VMCU1_Sig" SG_ 2147484367 EngineOilTempHigh_ISig_4 1;
BA_ "GenSigCycleTime" SG_ 2147484367 WarmUpCycle 100;
BA_ "GenSigCycleTimeActive" SG_ 2147484367 WarmUpCycle 100;
BA_ "GenSigStartValue" SG_ 2147484367 WarmUpCycle 3;
BA_ "Platform_VMCU1_Sig" SG_ 2147484367 WarmUpCycle 1;
BA_ "GenSigCycleTime" SG_ 2147484367 DeterminedGear 100;
BA_ "GenSigCycleTimeActive" SG_ 2147484367 DeterminedGear 100;
BA_ "GenSigStartValue" SG_ 2147484367 DeterminedGear 255;
BA_ "Platform_VMCU1_Sig" SG_ 2147484367 DeterminedGear 1;
BA_ "GenSigCycleTime" SG_ 2147484367 CCSetSpeedApplied_ISig_4 100;
BA_ "GenSigCycleTimeActive" SG_ 2147484367 CCSetSpeedApplied_ISig_4 100;
BA_ "GenSigStartValue" SG_ 2147484367 CCSetSpeedApplied_ISig_4 255;
BA_ "GenSigMaxLatency" SG_ 2147484367 CCSetSpeedApplied_ISig_4 55;
BA_ "Platform_VMCU1_Sig" SG_ 2147484367 CCSetSpeedApplied_ISig_4 1;
BA_ "SeToolAncestorID_SIGNAL" SG_ 2147484367 CCSetSpeedApplied_ISig_4 "x0000001D04352A03";
BA_ "SeToolItemID_SIGNAL" SG_ 2147484367 CCSetSpeedApplied_ISig_4 "x0000001D04352A03";
BA_ "SeToolName_SIGNAL" SG_ 2147484367 CCSetSpeedApplied_ISig_4 "CCSetSpeedApplied";
BA_ "SeToolVersion_SIGNAL" SG_ 2147484367 CCSetSpeedApplied_ISig_4 "1";
BA_ "GenSigSendType" SG_ 2671964902 DiagUUDTRespSig_F2_E6_ISig_4 7;
BA_ "Platform_VMCU1_Sig" SG_ 2671964902 DiagUUDTRespSig_F2_E6_ISig_4 1;
BA_ "GenSigSendType" SG_ 2671964901 DiagUUDTRespSig_F2_E5_ISig_4 7;
BA_ "GenSigSendType" SG_ 2671964864 DiagUUDTRespSig_F2_C0_ISig_4 7;
BA_ "Platform_VMCU1_Sig" SG_ 2671964864 DiagUUDTRespSig_F2_C0_ISig_4 1;
BA_ "GenSigSendType" SG_ 2671964834 DiagUUDTRespSig_F2_A2_ISig_4 7;
BA_ "Platform_VMCU1_Sig" SG_ 2671964834 DiagUUDTRespSig_F2_A2_ISig_4 1;
BA_ "GenSigSendType" SG_ 2671964833 DiagUUDTRespSig_F2_A1_ISig_4 7;
BA_ "Platform_VMCU1_Sig" SG_ 2671964833 DiagUUDTRespSig_F2_A1_ISig_4 1;
BA_ "GenSigSendType" SG_ 2671964832 DiagUUDTRespSig_F2_A0_ISig_4 7;
BA_ "Platform_VMCU1_Sig" SG_ 2671964832 DiagUUDTRespSig_F2_A0_ISig_4 1;
BA_ "GenSigSendType" SG_ 2671964824 DiagUUDTRespSig_F2_98_ISig_4 7;
BA_ "Platform_VMCU1_Sig" SG_ 2671964824 DiagUUDTRespSig_F2_98_ISig_4 1;
BA_ "GenSigSendType" SG_ 2671964803 DiagUUDTRespSig_F2_83_ISig_4 7;
BA_ "GenSigSendType" SG_ 2671964802 DiagUUDTRespSig_F2_82_ISig_4 7;
BA_ "Platform_VMCU1_Sig" SG_ 2671964802 DiagUUDTRespSig_F2_82_ISig_4 1;
BA_ "GenSigSendType" SG_ 2671964772 DiagUUDTRespSig_F2_64_ISig_4 7;
BA_ "GenSigSendType" SG_ 2671964769 DiagUUDTRespSig_F2_61_ISig_4 7;
BA_ "Platform_VMCU1_Sig" SG_ 2671964769 DiagUUDTRespSig_F2_61_ISig_4 1;
BA_ "GenSigSendType" SG_ 2671964768 DiagUUDTRespSig_F2_60_ISig_4 7;
BA_ "Platform_VMCU1_Sig" SG_ 2671964768 DiagUUDTRespSig_F2_60_ISig_4 1;
BA_ "GenSigSendType" SG_ 2671964755 DiagUUDTRespSig_F2_53_ISig_4 7;
BA_ "Platform_VMCU1_Sig" SG_ 2671964755 DiagUUDTRespSig_F2_53_ISig_4 1;
BA_ "GenSigSendType" SG_ 2671964754 DiagUUDTRespSig_F2_52_ISig_4 7;
BA_ "Platform_VMCU1_Sig" SG_ 2671964754 DiagUUDTRespSig_F2_52_ISig_4 1;
BA_ "GenSigSendType" SG_ 2671964753 DiagUUDTRespSig_F2_51_ISig_4 7;
BA_ "Platform_VMCU1_Sig" SG_ 2671964753 DiagUUDTRespSig_F2_51_ISig_4 1;
BA_ "GenSigSendType" SG_ 2671964752 DiagUUDTRespSig_F2_50_ISig_4 7;
BA_ "Platform_VMCU1_Sig" SG_ 2671964752 DiagUUDTRespSig_F2_50_ISig_4 1;
BA_ "GenSigSendType" SG_ 2671964737 DiagUUDTRespSig_F2_41_ISig_4 7;
BA_ "Platform_VMCU1_Sig" SG_ 2671964737 DiagUUDTRespSig_F2_41_ISig_4 1;
BA_ "GenSigSendType" SG_ 2671964736 DiagUUDTRespSig_F2_40_ISig_4 7;
BA_ "Platform_VMCU1_Sig" SG_ 2671964736 DiagUUDTRespSig_F2_40_ISig_4 1;
BA_ "GenSigSendType" SG_ 2671964710 DiagUUDTRespSig_F2_26_ISig_4 7;
BA_ "Platform_VMCU1_Sig" SG_ 2671964710 DiagUUDTRespSig_F2_26_ISig_4 1;
BA_ "GenSigSendType" SG_ 2671964696 DiagUUDTRespSig_F2_18_ISig_4 7;
BA_ "Platform_VMCU1_Sig" SG_ 2671964696 DiagUUDTRespSig_F2_18_ISig_4 1;
BA_ "GenSigSendType" SG_ 2671964688 DiagUUDTRespSig_F2_10_ISig_4 7;
BA_ "Platform_VMCU1_Sig" SG_ 2671964688 DiagUUDTRespSig_F2_10_ISig_4 1;
BA_ "GenSigSendType" SG_ 2671834342 InternalTesterDiagSig_F4_E6_ISig 7;
BA_ "Platform_VMCU1_Sig" SG_ 2671834342 InternalTesterDiagSig_F4_E6_ISig 1;
BA_ "SystemSignalLongSymbol" SG_ 2671834342 InternalTesterDiagSig_F4_E6_ISig "InternalTesterDiagSig_F4_E6_ISig_4";
BA_ "GenSigSendType" SG_ 2671834341 InternalTesterDiagSig_F4_E5_ISig 7;
BA_ "SystemSignalLongSymbol" SG_ 2671834341 InternalTesterDiagSig_F4_E5_ISig "InternalTesterDiagSig_F4_E5_ISig_4";
BA_ "GenSigSendType" SG_ 2671834304 InternalTesterDiagSig_F4_C0_ISig 7;
BA_ "Platform_VMCU1_Sig" SG_ 2671834304 InternalTesterDiagSig_F4_C0_ISig 1;
BA_ "SystemSignalLongSymbol" SG_ 2671834304 InternalTesterDiagSig_F4_C0_ISig "InternalTesterDiagSig_F4_C0_ISig_4";
BA_ "GenSigSendType" SG_ 2671834274 InternalTesterDiagSig_F4_A2_ISig 7;
BA_ "Platform_VMCU1_Sig" SG_ 2671834274 InternalTesterDiagSig_F4_A2_ISig 1;
BA_ "SystemSignalLongSymbol" SG_ 2671834274 InternalTesterDiagSig_F4_A2_ISig "InternalTesterDiagSig_F4_A2_ISig_4";
BA_ "GenSigSendType" SG_ 2671834273 InternalTesterDiagSig_F4_A1_ISig 7;
BA_ "Platform_VMCU1_Sig" SG_ 2671834273 InternalTesterDiagSig_F4_A1_ISig 1;
BA_ "SystemSignalLongSymbol" SG_ 2671834273 InternalTesterDiagSig_F4_A1_ISig "InternalTesterDiagSig_F4_A1_ISig_4";
BA_ "GenSigSendType" SG_ 2671834272 InternalTesterDiagSig_F4_A0_ISig 7;
BA_ "Platform_VMCU1_Sig" SG_ 2671834272 InternalTesterDiagSig_F4_A0_ISig 1;
BA_ "SystemSignalLongSymbol" SG_ 2671834272 InternalTesterDiagSig_F4_A0_ISig "InternalTesterDiagSig_F4_A0_ISig_4";
BA_ "GenSigSendType" SG_ 2671834264 InternalTesterDiagSig_F4_98_ISig 7;
BA_ "Platform_VMCU1_Sig" SG_ 2671834264 InternalTesterDiagSig_F4_98_ISig 1;
BA_ "SystemSignalLongSymbol" SG_ 2671834264 InternalTesterDiagSig_F4_98_ISig "InternalTesterDiagSig_F4_98_ISig_4";
BA_ "GenSigSendType" SG_ 2671834226 InternalTesterDiagSig_F4_72_ISig 7;
BA_ "SystemSignalLongSymbol" SG_ 2671834226 InternalTesterDiagSig_F4_72_ISig "InternalTesterDiagSig_F4_72_ISig_4";
BA_ "GenSigSendType" SG_ 2671834225 InternalTesterDiagSig_F4_71_ISig 7;
BA_ "SystemSignalLongSymbol" SG_ 2671834225 InternalTesterDiagSig_F4_71_ISig "InternalTesterDiagSig_F4_71_ISig_4";
BA_ "GenSigSendType" SG_ 2671834195 InternalTesterDiagSig_F4_53_ISig 7;
BA_ "Platform_VMCU1_Sig" SG_ 2671834195 InternalTesterDiagSig_F4_53_ISig 1;
BA_ "SystemSignalLongSymbol" SG_ 2671834195 InternalTesterDiagSig_F4_53_ISig "InternalTesterDiagSig_F4_53_ISig_4";
BA_ "GenSigSendType" SG_ 2671834194 InternalTesterDiagSig_F4_52_ISig 7;
BA_ "Platform_VMCU1_Sig" SG_ 2671834194 InternalTesterDiagSig_F4_52_ISig 1;
BA_ "SystemSignalLongSymbol" SG_ 2671834194 InternalTesterDiagSig_F4_52_ISig "InternalTesterDiagSig_F4_52_ISig_4";
BA_ "GenSigSendType" SG_ 2671834193 InternalTesterDiagSig_F4_51_ISig 7;
BA_ "Platform_VMCU1_Sig" SG_ 2671834193 InternalTesterDiagSig_F4_51_ISig 1;
BA_ "SystemSignalLongSymbol" SG_ 2671834193 InternalTesterDiagSig_F4_51_ISig "InternalTesterDiagSig_F4_51_ISig_4";
BA_ "GenSigSendType" SG_ 2671834192 InternalTesterDiagSig_F4_50_ISig 7;
BA_ "Platform_VMCU1_Sig" SG_ 2671834192 InternalTesterDiagSig_F4_50_ISig 1;
BA_ "SystemSignalLongSymbol" SG_ 2671834192 InternalTesterDiagSig_F4_50_ISig "InternalTesterDiagSig_F4_50_ISig_4";
BA_ "GenSigSendType" SG_ 2671834176 InternalTesterDiagSig_F4_40_ISig 7;
BA_ "Platform_VMCU1_Sig" SG_ 2671834176 InternalTesterDiagSig_F4_40_ISig 1;
BA_ "SystemSignalLongSymbol" SG_ 2671834176 InternalTesterDiagSig_F4_40_ISig "InternalTesterDiagSig_F4_40_ISig_4";
BA_ "GenSigSendType" SG_ 2671834161 InternalTesterDiagSig_F4_31_ISig 7;
BA_ "Platform_VMCU1_Sig" SG_ 2671834161 InternalTesterDiagSig_F4_31_ISig 1;
BA_ "SystemSignalLongSymbol" SG_ 2671834161 InternalTesterDiagSig_F4_31_ISig "InternalTesterDiagSig_F4_31_ISig_4";
BA_ "GenSigSendType" SG_ 2671834160 InternalTesterDiagSig_F4_30_ISig 7;
BA_ "Platform_VMCU1_Sig" SG_ 2671834160 InternalTesterDiagSig_F4_30_ISig 1;
BA_ "SystemSignalLongSymbol" SG_ 2671834160 InternalTesterDiagSig_F4_30_ISig "InternalTesterDiagSig_F4_30_ISig_4";
BA_ "GenSigSendType" SG_ 2671834150 InternalTesterDiagSig_F4_26_ISig 7;
BA_ "Platform_VMCU1_Sig" SG_ 2671834150 InternalTesterDiagSig_F4_26_ISig 1;
BA_ "SystemSignalLongSymbol" SG_ 2671834150 InternalTesterDiagSig_F4_26_ISig "InternalTesterDiagSig_F4_26_ISig_4";
BA_ "GenSigSendType" SG_ 2671834149 InternalTesterDiagSig_F4_25_ISig 7;
BA_ "Platform_VMCU1_Sig" SG_ 2671834149 InternalTesterDiagSig_F4_25_ISig 1;
BA_ "SystemSignalLongSymbol" SG_ 2671834149 InternalTesterDiagSig_F4_25_ISig "InternalTesterDiagSig_F4_25_ISig_4";
BA_ "GenSigSendType" SG_ 2671834148 InternalTesterDiagSig_F4_24_ISig 7;
BA_ "Platform_VMCU1_Sig" SG_ 2671834148 InternalTesterDiagSig_F4_24_ISig 1;
BA_ "SystemSignalLongSymbol" SG_ 2671834148 InternalTesterDiagSig_F4_24_ISig "InternalTesterDiagSig_F4_24_ISig_4";
BA_ "GenSigSendType" SG_ 2671834147 InternalTesterDiagSig_F4_23_ISig 7;
BA_ "Platform_VMCU1_Sig" SG_ 2671834147 InternalTesterDiagSig_F4_23_ISig 1;
BA_ "SystemSignalLongSymbol" SG_ 2671834147 InternalTesterDiagSig_F4_23_ISig "InternalTesterDiagSig_F4_23_ISig_4";
BA_ "GenSigSendType" SG_ 2671834146 InternalTesterDiagSig_F4_22_ISig 7;
BA_ "Platform_VMCU1_Sig" SG_ 2671834146 InternalTesterDiagSig_F4_22_ISig 1;
BA_ "SystemSignalLongSymbol" SG_ 2671834146 InternalTesterDiagSig_F4_22_ISig "InternalTesterDiagSig_F4_22_ISig_4";
BA_ "GenSigSendType" SG_ 2671834145 InternalTesterDiagSig_F4_21_ISig 7;
BA_ "Platform_VMCU1_Sig" SG_ 2671834145 InternalTesterDiagSig_F4_21_ISig 1;
BA_ "SystemSignalLongSymbol" SG_ 2671834145 InternalTesterDiagSig_F4_21_ISig "InternalTesterDiagSig_F4_21_ISig_4";
BA_ "GenSigSendType" SG_ 2671834144 InternalTesterDiagSig_F4_20_ISig 7;
BA_ "Platform_VMCU1_Sig" SG_ 2671834144 InternalTesterDiagSig_F4_20_ISig 1;
BA_ "SystemSignalLongSymbol" SG_ 2671834144 InternalTesterDiagSig_F4_20_ISig "InternalTesterDiagSig_F4_20_ISig_4";
BA_ "GenSigSendType" SG_ 2671834138 InternalTesterDiagSig_F4_1A_ISig 7;
BA_ "SystemSignalLongSymbol" SG_ 2671834138 InternalTesterDiagSig_F4_1A_ISig "InternalTesterDiagSig_F4_1A_ISig_4";
BA_ "GenSigSendType" SG_ 2671834136 InternalTesterDiagSig_F4_18_ISig 7;
BA_ "Platform_VMCU1_Sig" SG_ 2671834136 InternalTesterDiagSig_F4_18_ISig 1;
BA_ "SystemSignalLongSymbol" SG_ 2671834136 InternalTesterDiagSig_F4_18_ISig "InternalTesterDiagSig_F4_18_ISig_4";
BA_ "GenSigSendType" SG_ 2671834128 InternalTesterDiagSig_F4_10_ISig 7;
BA_ "Platform_VMCU1_Sig" SG_ 2671834128 InternalTesterDiagSig_F4_10_ISig 1;
BA_ "SystemSignalLongSymbol" SG_ 2671834128 InternalTesterDiagSig_F4_10_ISig "InternalTesterDiagSig_F4_10_ISig_4";
BA_ "GenSigSendType" SG_ 2671834086 InternalTesterDiagSig_F3_E6 7;
BA_ "Platform_VMCU1_Sig" SG_ 2671834086 InternalTesterDiagSig_F3_E6 1;
BA_ "GenSigSendType" SG_ 2671834085 InternalTesterDiagSig_F3_E5_ISig 7;
BA_ "SystemSignalLongSymbol" SG_ 2671834085 InternalTesterDiagSig_F3_E5_ISig "InternalTesterDiagSig_F3_E5_ISig_4";
BA_ "GenSigSendType" SG_ 2671834048 InternalTesterDiagSig_F3_C0_ISig 7;
BA_ "Platform_VMCU1_Sig" SG_ 2671834048 InternalTesterDiagSig_F3_C0_ISig 1;
BA_ "SystemSignalLongSymbol" SG_ 2671834048 InternalTesterDiagSig_F3_C0_ISig "InternalTesterDiagSig_F3_C0_ISig_4";
BA_ "GenSigSendType" SG_ 2671834018 InternalTesterDiagSig_F3_A2_ISig 7;
BA_ "Platform_VMCU1_Sig" SG_ 2671834018 InternalTesterDiagSig_F3_A2_ISig 1;
BA_ "SystemSignalLongSymbol" SG_ 2671834018 InternalTesterDiagSig_F3_A2_ISig "InternalTesterDiagSig_F3_A2_ISig_4";
BA_ "GenSigSendType" SG_ 2671834017 InternalTesterDiagSig_F3_A1_ISig 7;
BA_ "Platform_VMCU1_Sig" SG_ 2671834017 InternalTesterDiagSig_F3_A1_ISig 1;
BA_ "SystemSignalLongSymbol" SG_ 2671834017 InternalTesterDiagSig_F3_A1_ISig "InternalTesterDiagSig_F3_A1_ISig_4";
BA_ "GenSigSendType" SG_ 2671834016 InternalTesterDiagSig_F3_A0_ISig 7;
BA_ "Platform_VMCU1_Sig" SG_ 2671834016 InternalTesterDiagSig_F3_A0_ISig 1;
BA_ "SystemSignalLongSymbol" SG_ 2671834016 InternalTesterDiagSig_F3_A0_ISig "InternalTesterDiagSig_F3_A0_ISig_4";
BA_ "GenSigSendType" SG_ 2671834008 InternalTesterDiagSig_F3_98_ISig 7;
BA_ "Platform_VMCU1_Sig" SG_ 2671834008 InternalTesterDiagSig_F3_98_ISig 1;
BA_ "SystemSignalLongSymbol" SG_ 2671834008 InternalTesterDiagSig_F3_98_ISig "InternalTesterDiagSig_F3_98_ISig_4";
BA_ "GenSigSendType" SG_ 2671833970 InternalTesterDiagSig_F3_72_ISig 7;
BA_ "SystemSignalLongSymbol" SG_ 2671833970 InternalTesterDiagSig_F3_72_ISig "InternalTesterDiagSig_F3_72_ISig_4";
BA_ "GenSigSendType" SG_ 2671833969 InternalTesterDiagSig_F3_71_ISig 7;
BA_ "SystemSignalLongSymbol" SG_ 2671833969 InternalTesterDiagSig_F3_71_ISig "InternalTesterDiagSig_F3_71_ISig_4";
BA_ "GenSigSendType" SG_ 2671833939 InternalTesterDiagSig_F3_53_ISig 7;
BA_ "Platform_VMCU1_Sig" SG_ 2671833939 InternalTesterDiagSig_F3_53_ISig 1;
BA_ "SystemSignalLongSymbol" SG_ 2671833939 InternalTesterDiagSig_F3_53_ISig "InternalTesterDiagSig_F3_53_ISig_4";
BA_ "GenSigSendType" SG_ 2671833938 InternalTesterDiagSig_F3_52_ISig 7;
BA_ "Platform_VMCU1_Sig" SG_ 2671833938 InternalTesterDiagSig_F3_52_ISig 1;
BA_ "SystemSignalLongSymbol" SG_ 2671833938 InternalTesterDiagSig_F3_52_ISig "InternalTesterDiagSig_F3_52_ISig_4";
BA_ "GenSigSendType" SG_ 2671833937 InternalTesterDiagSig_F3_51_ISig 7;
BA_ "Platform_VMCU1_Sig" SG_ 2671833937 InternalTesterDiagSig_F3_51_ISig 1;
BA_ "SystemSignalLongSymbol" SG_ 2671833937 InternalTesterDiagSig_F3_51_ISig "InternalTesterDiagSig_F3_51_ISig_4";
BA_ "GenSigSendType" SG_ 2671833936 InternalTesterDiagSig_F3_50 7;
BA_ "Platform_VMCU1_Sig" SG_ 2671833936 InternalTesterDiagSig_F3_50 1;
BA_ "GenSigSendType" SG_ 2671833920 InternalTesterDiagSig_F3_40 7;
BA_ "Platform_VMCU1_Sig" SG_ 2671833920 InternalTesterDiagSig_F3_40 1;
BA_ "GenSigSendType" SG_ 2671833905 InternalTesterDiagSig_F3_31_ISig 7;
BA_ "Platform_VMCU1_Sig" SG_ 2671833905 InternalTesterDiagSig_F3_31_ISig 1;
BA_ "SystemSignalLongSymbol" SG_ 2671833905 InternalTesterDiagSig_F3_31_ISig "InternalTesterDiagSig_F3_31_ISig_4";
BA_ "GenSigSendType" SG_ 2671833904 InternalTesterDiagSig_F3_30_ISig 7;
BA_ "Platform_VMCU1_Sig" SG_ 2671833904 InternalTesterDiagSig_F3_30_ISig 1;
BA_ "SystemSignalLongSymbol" SG_ 2671833904 InternalTesterDiagSig_F3_30_ISig "InternalTesterDiagSig_F3_30_ISig_4";
BA_ "GenSigSendType" SG_ 2671833894 InternalTesterDiagSig_F3_26_ISig 7;
BA_ "Platform_VMCU1_Sig" SG_ 2671833894 InternalTesterDiagSig_F3_26_ISig 1;
BA_ "SystemSignalLongSymbol" SG_ 2671833894 InternalTesterDiagSig_F3_26_ISig "InternalTesterDiagSig_F3_26_ISig_4";
BA_ "GenSigSendType" SG_ 2671833893 InternalTesterDiagSig_F3_25_ISig 7;
BA_ "Platform_VMCU1_Sig" SG_ 2671833893 InternalTesterDiagSig_F3_25_ISig 1;
BA_ "SystemSignalLongSymbol" SG_ 2671833893 InternalTesterDiagSig_F3_25_ISig "InternalTesterDiagSig_F3_25_ISig_4";
BA_ "GenSigSendType" SG_ 2671833892 InternalTesterDiagSig_F3_24 7;
BA_ "Platform_VMCU1_Sig" SG_ 2671833892 InternalTesterDiagSig_F3_24 1;
BA_ "GenSigSendType" SG_ 2671833891 InternalTesterDiagSig_F3_23_ISig 7;
BA_ "Platform_VMCU1_Sig" SG_ 2671833891 InternalTesterDiagSig_F3_23_ISig 1;
BA_ "SystemSignalLongSymbol" SG_ 2671833891 InternalTesterDiagSig_F3_23_ISig "InternalTesterDiagSig_F3_23_ISig_4";
BA_ "GenSigSendType" SG_ 2671833890 InternalTesterDiagSig_F3_22_ISig 7;
BA_ "Platform_VMCU1_Sig" SG_ 2671833890 InternalTesterDiagSig_F3_22_ISig 1;
BA_ "SystemSignalLongSymbol" SG_ 2671833890 InternalTesterDiagSig_F3_22_ISig "InternalTesterDiagSig_F3_22_ISig_4";
BA_ "GenSigSendType" SG_ 2671833889 InternalTesterDiagSig_F3_21_ISig 7;
BA_ "Platform_VMCU1_Sig" SG_ 2671833889 InternalTesterDiagSig_F3_21_ISig 1;
BA_ "SystemSignalLongSymbol" SG_ 2671833889 InternalTesterDiagSig_F3_21_ISig "InternalTesterDiagSig_F3_21_ISig_4";
BA_ "GenSigSendType" SG_ 2671833888 InternalTesterDiagSig_F3_20_ISig 7;
BA_ "Platform_VMCU1_Sig" SG_ 2671833888 InternalTesterDiagSig_F3_20_ISig 1;
BA_ "SystemSignalLongSymbol" SG_ 2671833888 InternalTesterDiagSig_F3_20_ISig "InternalTesterDiagSig_F3_20_ISig_4";
BA_ "GenSigSendType" SG_ 2671833882 InternalTesterDiagSig_F3_1A_ISig 7;
BA_ "SystemSignalLongSymbol" SG_ 2671833882 InternalTesterDiagSig_F3_1A_ISig "InternalTesterDiagSig_F3_1A_ISig_4";
BA_ "GenSigSendType" SG_ 2671833880 InternalTesterDiagSig_F3_18 7;
BA_ "Platform_VMCU1_Sig" SG_ 2671833880 InternalTesterDiagSig_F3_18 1;
BA_ "GenSigSendType" SG_ 2671833872 InternalTesterDiagSig_F3_10 7;
BA_ "Platform_VMCU1_Sig" SG_ 2671833872 InternalTesterDiagSig_F3_10 1;
BA_ "GenSigSendType" SG_ 2671830772 InternalTesterDiagSig_E6_F4_ISig 7;
BA_ "Platform_VMCU1_Sig" SG_ 2671830772 InternalTesterDiagSig_E6_F4_ISig 1;
BA_ "SystemSignalLongSymbol" SG_ 2671830772 InternalTesterDiagSig_E6_F4_ISig "InternalTesterDiagSig_E6_F4_ISig_4";
BA_ "GenSigSendType" SG_ 2671830516 InternalTesterDiagSig_E5_F4_ISig 7;
BA_ "SystemSignalLongSymbol" SG_ 2671830516 InternalTesterDiagSig_E5_F4_ISig "InternalTesterDiagSig_E5_F4_ISig_4";
BA_ "GenSigSendType" SG_ 2671821044 InternalTesterDiagSig_C0_F4_ISig 7;
BA_ "Platform_VMCU1_Sig" SG_ 2671821044 InternalTesterDiagSig_C0_F4_ISig 1;
BA_ "SystemSignalLongSymbol" SG_ 2671821044 InternalTesterDiagSig_C0_F4_ISig "InternalTesterDiagSig_C0_F4_ISig_4";
BA_ "GenSigSendType" SG_ 2671813364 InternalTesterDiagSig_A2_F4_ISig 7;
BA_ "Platform_VMCU1_Sig" SG_ 2671813364 InternalTesterDiagSig_A2_F4_ISig 1;
BA_ "SystemSignalLongSymbol" SG_ 2671813364 InternalTesterDiagSig_A2_F4_ISig "InternalTesterDiagSig_A2_F4_ISig_4";
BA_ "GenSigSendType" SG_ 2671813108 InternalTesterDiagSig_A1_F4_ISig 7;
BA_ "Platform_VMCU1_Sig" SG_ 2671813108 InternalTesterDiagSig_A1_F4_ISig 1;
BA_ "SystemSignalLongSymbol" SG_ 2671813108 InternalTesterDiagSig_A1_F4_ISig "InternalTesterDiagSig_A1_F4_ISig_4";
BA_ "GenSigSendType" SG_ 2671812852 InternalTesterDiagSig_A0_F4_ISig 7;
BA_ "Platform_VMCU1_Sig" SG_ 2671812852 InternalTesterDiagSig_A0_F4_ISig 1;
BA_ "SystemSignalLongSymbol" SG_ 2671812852 InternalTesterDiagSig_A0_F4_ISig "InternalTesterDiagSig_A0_F4_ISig_4";
BA_ "GenSigSendType" SG_ 2671810804 InternalTesterDiagSig_98_F4_ISig 7;
BA_ "Platform_VMCU1_Sig" SG_ 2671810804 InternalTesterDiagSig_98_F4_ISig 1;
BA_ "SystemSignalLongSymbol" SG_ 2671810804 InternalTesterDiagSig_98_F4_ISig "InternalTesterDiagSig_98_F4_ISig_4";
BA_ "GenSigSendType" SG_ 2671801076 InternalTesterDiagSig_72_F4_ISig 7;
BA_ "SystemSignalLongSymbol" SG_ 2671801076 InternalTesterDiagSig_72_F4_ISig "InternalTesterDiagSig_72_F4_ISig_4";
BA_ "GenSigSendType" SG_ 2671800820 InternalTesterDiagSig_71_F4_ISig 7;
BA_ "SystemSignalLongSymbol" SG_ 2671800820 InternalTesterDiagSig_71_F4_ISig "InternalTesterDiagSig_71_F4_ISig_4";
BA_ "GenSigSendType" SG_ 2671793140 InternalTesterDiagSig_53_F4_ISig 7;
BA_ "Platform_VMCU1_Sig" SG_ 2671793140 InternalTesterDiagSig_53_F4_ISig 1;
BA_ "SystemSignalLongSymbol" SG_ 2671793140 InternalTesterDiagSig_53_F4_ISig "InternalTesterDiagSig_53_F4_ISig_4";
BA_ "GenSigSendType" SG_ 2671792884 InternalTesterDiagSig_52_F4_ISig 7;
BA_ "Platform_VMCU1_Sig" SG_ 2671792884 InternalTesterDiagSig_52_F4_ISig 1;
BA_ "SystemSignalLongSymbol" SG_ 2671792884 InternalTesterDiagSig_52_F4_ISig "InternalTesterDiagSig_52_F4_ISig_4";
BA_ "GenSigSendType" SG_ 2671792628 InternalTesterDiagSig_51_F4_ISig 7;
BA_ "Platform_VMCU1_Sig" SG_ 2671792628 InternalTesterDiagSig_51_F4_ISig 1;
BA_ "SystemSignalLongSymbol" SG_ 2671792628 InternalTesterDiagSig_51_F4_ISig "InternalTesterDiagSig_51_F4_ISig_4";
BA_ "GenSigSendType" SG_ 2671792372 InternalTesterDiagSig_50_F4_ISig 7;
BA_ "Platform_VMCU1_Sig" SG_ 2671792372 InternalTesterDiagSig_50_F4_ISig 1;
BA_ "SystemSignalLongSymbol" SG_ 2671792372 InternalTesterDiagSig_50_F4_ISig "InternalTesterDiagSig_50_F4_ISig_4";
BA_ "GenSigSendType" SG_ 2671788276 InternalTesterDiagSig_40_F4_ISig 7;
BA_ "Platform_VMCU1_Sig" SG_ 2671788276 InternalTesterDiagSig_40_F4_ISig 1;
BA_ "SystemSignalLongSymbol" SG_ 2671788276 InternalTesterDiagSig_40_F4_ISig "InternalTesterDiagSig_40_F4_ISig_4";
BA_ "GenSigSendType" SG_ 2671784436 InternalTesterDiagSig_31_F4_ISig 7;
BA_ "Platform_VMCU1_Sig" SG_ 2671784436 InternalTesterDiagSig_31_F4_ISig 1;
BA_ "SystemSignalLongSymbol" SG_ 2671784436 InternalTesterDiagSig_31_F4_ISig "InternalTesterDiagSig_31_F4_ISig_4";
BA_ "GenSigSendType" SG_ 2671784180 InternalTesterDiagSig_30_F4_ISig 7;
BA_ "Platform_VMCU1_Sig" SG_ 2671784180 InternalTesterDiagSig_30_F4_ISig 1;
BA_ "SystemSignalLongSymbol" SG_ 2671784180 InternalTesterDiagSig_30_F4_ISig "InternalTesterDiagSig_30_F4_ISig_4";
BA_ "GenSigSendType" SG_ 2671781620 InternalTesterDiagSig_26_F4_ISig 7;
BA_ "Platform_VMCU1_Sig" SG_ 2671781620 InternalTesterDiagSig_26_F4_ISig 1;
BA_ "SystemSignalLongSymbol" SG_ 2671781620 InternalTesterDiagSig_26_F4_ISig "InternalTesterDiagSig_26_F4_ISig_4";
BA_ "GenSigSendType" SG_ 2671781364 InternalTesterDiagSig_25_F4_ISig 7;
BA_ "Platform_VMCU1_Sig" SG_ 2671781364 InternalTesterDiagSig_25_F4_ISig 1;
BA_ "SystemSignalLongSymbol" SG_ 2671781364 InternalTesterDiagSig_25_F4_ISig "InternalTesterDiagSig_25_F4_ISig_4";
BA_ "GenSigSendType" SG_ 2671781108 InternalTesterDiagSig_24_F4_ISig 7;
BA_ "Platform_VMCU1_Sig" SG_ 2671781108 InternalTesterDiagSig_24_F4_ISig 1;
BA_ "SystemSignalLongSymbol" SG_ 2671781108 InternalTesterDiagSig_24_F4_ISig "InternalTesterDiagSig_24_F4_ISig_4";
BA_ "GenSigSendType" SG_ 2671780852 InternalTesterDiagSig_23_F4_ISig 7;
BA_ "Platform_VMCU1_Sig" SG_ 2671780852 InternalTesterDiagSig_23_F4_ISig 1;
BA_ "SystemSignalLongSymbol" SG_ 2671780852 InternalTesterDiagSig_23_F4_ISig "InternalTesterDiagSig_23_F4_ISig_4";
BA_ "GenSigSendType" SG_ 2671780596 InternalTesterDiagSig_22_F4_ISig 7;
BA_ "Platform_VMCU1_Sig" SG_ 2671780596 InternalTesterDiagSig_22_F4_ISig 1;
BA_ "SystemSignalLongSymbol" SG_ 2671780596 InternalTesterDiagSig_22_F4_ISig "InternalTesterDiagSig_22_F4_ISig_4";
BA_ "GenSigSendType" SG_ 2671780340 InternalTesterDiagSig_21_F4_ISig 7;
BA_ "Platform_VMCU1_Sig" SG_ 2671780340 InternalTesterDiagSig_21_F4_ISig 1;
BA_ "SystemSignalLongSymbol" SG_ 2671780340 InternalTesterDiagSig_21_F4_ISig "InternalTesterDiagSig_21_F4_ISig_4";
BA_ "GenSigSendType" SG_ 2671780084 InternalTesterDiagSig_20_F4_ISig 7;
BA_ "Platform_VMCU1_Sig" SG_ 2671780084 InternalTesterDiagSig_20_F4_ISig 1;
BA_ "SystemSignalLongSymbol" SG_ 2671780084 InternalTesterDiagSig_20_F4_ISig "InternalTesterDiagSig_20_F4_ISig_4";
BA_ "GenSigSendType" SG_ 2671778548 InternalTesterDiagSig_1A_F4_ISig 7;
BA_ "SystemSignalLongSymbol" SG_ 2671778548 InternalTesterDiagSig_1A_F4_ISig "InternalTesterDiagSig_1A_F4_ISig_4";
BA_ "GenSigSendType" SG_ 2671778036 InternalTesterDiagSig_18_F4_ISig 7;
BA_ "Platform_VMCU1_Sig" SG_ 2671778036 InternalTesterDiagSig_18_F4_ISig 1;
BA_ "SystemSignalLongSymbol" SG_ 2671778036 InternalTesterDiagSig_18_F4_ISig "InternalTesterDiagSig_18_F4_ISig_4";
BA_ "GenSigSendType" SG_ 2671775988 InternalTesterDiagSig_10_F4_ISig 7;
BA_ "Platform_VMCU1_Sig" SG_ 2671775988 InternalTesterDiagSig_10_F4_ISig 1;
BA_ "SystemSignalLongSymbol" SG_ 2671775988 InternalTesterDiagSig_10_F4_ISig "InternalTesterDiagSig_10_F4_ISig_4";
BA_ "GenSigSendType" SG_ 2671830771 InternalTesterDiagSig_E6_F3 7;
BA_ "Platform_VMCU1_Sig" SG_ 2671830771 InternalTesterDiagSig_E6_F3 1;
BA_ "GenSigSendType" SG_ 2671830515 InternalTesterDiagSig_E5_F3_ISig 7;
BA_ "SystemSignalLongSymbol" SG_ 2671830515 InternalTesterDiagSig_E5_F3_ISig "InternalTesterDiagSig_E5_F3_ISig_4";
BA_ "GenSigSendType" SG_ 2671821043 InternalTesterDiagSig_C0_F3_ISig 7;
BA_ "Platform_VMCU1_Sig" SG_ 2671821043 InternalTesterDiagSig_C0_F3_ISig 1;
BA_ "SystemSignalLongSymbol" SG_ 2671821043 InternalTesterDiagSig_C0_F3_ISig "InternalTesterDiagSig_C0_F3_ISig_4";
BA_ "GenSigSendType" SG_ 2671813363 InternalTesterDiagSig_A2_F3_ISig 7;
BA_ "Platform_VMCU1_Sig" SG_ 2671813363 InternalTesterDiagSig_A2_F3_ISig 1;
BA_ "SystemSignalLongSymbol" SG_ 2671813363 InternalTesterDiagSig_A2_F3_ISig "InternalTesterDiagSig_A2_F3_ISig_4";
BA_ "GenSigSendType" SG_ 2671813107 InternalTesterDiagSig_A1_F3_ISig 7;
BA_ "Platform_VMCU1_Sig" SG_ 2671813107 InternalTesterDiagSig_A1_F3_ISig 1;
BA_ "SystemSignalLongSymbol" SG_ 2671813107 InternalTesterDiagSig_A1_F3_ISig "InternalTesterDiagSig_A1_F3_ISig_4";
BA_ "GenSigSendType" SG_ 2671812851 InternalTesterDiagSig_A0_F3_ISig 7;
BA_ "Platform_VMCU1_Sig" SG_ 2671812851 InternalTesterDiagSig_A0_F3_ISig 1;
BA_ "SystemSignalLongSymbol" SG_ 2671812851 InternalTesterDiagSig_A0_F3_ISig "InternalTesterDiagSig_A0_F3_ISig_4";
BA_ "GenSigSendType" SG_ 2671810803 InternalTesterDiagSig_98_F3_ISig 7;
BA_ "Platform_VMCU1_Sig" SG_ 2671810803 InternalTesterDiagSig_98_F3_ISig 1;
BA_ "SystemSignalLongSymbol" SG_ 2671810803 InternalTesterDiagSig_98_F3_ISig "InternalTesterDiagSig_98_F3_ISig_4";
BA_ "GenSigSendType" SG_ 2671801075 InternalTesterDiagSig_72_F3_ISig 7;
BA_ "SystemSignalLongSymbol" SG_ 2671801075 InternalTesterDiagSig_72_F3_ISig "InternalTesterDiagSig_72_F3_ISig_4";
BA_ "GenSigSendType" SG_ 2671800819 InternalTesterDiagSig_71_F3_ISig 7;
BA_ "SystemSignalLongSymbol" SG_ 2671800819 InternalTesterDiagSig_71_F3_ISig "InternalTesterDiagSig_71_F3_ISig_4";
BA_ "GenSigSendType" SG_ 2671793139 InternalTesterDiagSig_53_F3_ISig 7;
BA_ "Platform_VMCU1_Sig" SG_ 2671793139 InternalTesterDiagSig_53_F3_ISig 1;
BA_ "SystemSignalLongSymbol" SG_ 2671793139 InternalTesterDiagSig_53_F3_ISig "InternalTesterDiagSig_53_F3_ISig_4";
BA_ "GenSigSendType" SG_ 2671792883 InternalTesterDiagSig_52_F3_ISig 7;
BA_ "Platform_VMCU1_Sig" SG_ 2671792883 InternalTesterDiagSig_52_F3_ISig 1;
BA_ "SystemSignalLongSymbol" SG_ 2671792883 InternalTesterDiagSig_52_F3_ISig "InternalTesterDiagSig_52_F3_ISig_4";
BA_ "GenSigSendType" SG_ 2671792627 InternalTesterDiagSig_51_F3_ISig 7;
BA_ "Platform_VMCU1_Sig" SG_ 2671792627 InternalTesterDiagSig_51_F3_ISig 1;
BA_ "SystemSignalLongSymbol" SG_ 2671792627 InternalTesterDiagSig_51_F3_ISig "InternalTesterDiagSig_51_F3_ISig_4";
BA_ "GenSigSendType" SG_ 2671792371 InternalTesterDiagSig_50_F3 7;
BA_ "Platform_VMCU1_Sig" SG_ 2671792371 InternalTesterDiagSig_50_F3 1;
BA_ "GenSigSendType" SG_ 2671788275 InternalTesterDiagSig_40_F3 7;
BA_ "Platform_VMCU1_Sig" SG_ 2671788275 InternalTesterDiagSig_40_F3 1;
BA_ "GenSigSendType" SG_ 2671784435 InternalTesterDiagSig_31_F3_ISig 7;
BA_ "Platform_VMCU1_Sig" SG_ 2671784435 InternalTesterDiagSig_31_F3_ISig 1;
BA_ "SystemSignalLongSymbol" SG_ 2671784435 InternalTesterDiagSig_31_F3_ISig "InternalTesterDiagSig_31_F3_ISig_4";
BA_ "GenSigSendType" SG_ 2671784179 InternalTesterDiagSig_30_F3_ISig 7;
BA_ "Platform_VMCU1_Sig" SG_ 2671784179 InternalTesterDiagSig_30_F3_ISig 1;
BA_ "SystemSignalLongSymbol" SG_ 2671784179 InternalTesterDiagSig_30_F3_ISig "InternalTesterDiagSig_30_F3_ISig_4";
BA_ "GenSigSendType" SG_ 2671781619 InternalTesterDiagSig_26_F3_ISig 7;
BA_ "Platform_VMCU1_Sig" SG_ 2671781619 InternalTesterDiagSig_26_F3_ISig 1;
BA_ "SystemSignalLongSymbol" SG_ 2671781619 InternalTesterDiagSig_26_F3_ISig "InternalTesterDiagSig_26_F3_ISig_4";
BA_ "GenSigSendType" SG_ 2671781363 InternalTesterDiagSig_25_F3_ISig 7;
BA_ "Platform_VMCU1_Sig" SG_ 2671781363 InternalTesterDiagSig_25_F3_ISig 1;
BA_ "SystemSignalLongSymbol" SG_ 2671781363 InternalTesterDiagSig_25_F3_ISig "InternalTesterDiagSig_25_F3_ISig_4";
BA_ "GenSigSendType" SG_ 2671781107 InternalTesterDiagSig_24_F3 7;
BA_ "Platform_VMCU1_Sig" SG_ 2671781107 InternalTesterDiagSig_24_F3 1;
BA_ "GenSigSendType" SG_ 2671780851 InternalTesterDiagSig_23_F3_ISig 7;
BA_ "Platform_VMCU1_Sig" SG_ 2671780851 InternalTesterDiagSig_23_F3_ISig 1;
BA_ "SystemSignalLongSymbol" SG_ 2671780851 InternalTesterDiagSig_23_F3_ISig "InternalTesterDiagSig_23_F3_ISig_4";
BA_ "GenSigSendType" SG_ 2671780595 InternalTesterDiagSig_22_F3_ISig 7;
BA_ "Platform_VMCU1_Sig" SG_ 2671780595 InternalTesterDiagSig_22_F3_ISig 1;
BA_ "SystemSignalLongSymbol" SG_ 2671780595 InternalTesterDiagSig_22_F3_ISig "InternalTesterDiagSig_22_F3_ISig_4";
BA_ "GenSigSendType" SG_ 2671780339 InternalTesterDiagSig_21_F3_ISig 7;
BA_ "Platform_VMCU1_Sig" SG_ 2671780339 InternalTesterDiagSig_21_F3_ISig 1;
BA_ "SystemSignalLongSymbol" SG_ 2671780339 InternalTesterDiagSig_21_F3_ISig "InternalTesterDiagSig_21_F3_ISig_4";
BA_ "GenSigSendType" SG_ 2671780083 InternalTesterDiagSig_20_F3_ISig 7;
BA_ "Platform_VMCU1_Sig" SG_ 2671780083 InternalTesterDiagSig_20_F3_ISig 1;
BA_ "SystemSignalLongSymbol" SG_ 2671780083 InternalTesterDiagSig_20_F3_ISig "InternalTesterDiagSig_20_F3_ISig_4";
BA_ "GenSigSendType" SG_ 2671778547 InternalTesterDiagSig_1A_F3_ISig 7;
BA_ "SystemSignalLongSymbol" SG_ 2671778547 InternalTesterDiagSig_1A_F3_ISig "InternalTesterDiagSig_1A_F3_ISig_4";
BA_ "GenSigSendType" SG_ 2671778035 InternalTesterDiagSig_18_F3 7;
BA_ "Platform_VMCU1_Sig" SG_ 2671778035 InternalTesterDiagSig_18_F3 1;
BA_ "GenSigSendType" SG_ 2671775987 InternalTesterDiagSig_10_F3 7;
BA_ "Platform_VMCU1_Sig" SG_ 2671775987 InternalTesterDiagSig_10_F3 1;
BA_ "GenSigSendType" SG_ 2147485168 DiagFaultStat_WRCS_EcuAdr_ISig_4 1;
BA_ "GenSigStartValue" SG_ 2147485168 DiagFaultStat_WRCS_EcuAdr_ISig_4 255;
BA_ "NeedsUpdateBit" SG_ 2147485168 DiagFaultStat_WRCS_EcuAdr_ISig_4 1;
BA_ "Platform_VMCU1_Sig" SG_ 2147485168 DiagFaultStat_WRCS_EcuAdr_ISig_4 1;
BA_ "GenSigSendType" SG_ 2147485168 DiagFaultStat_WRCS_sg_UB_ISig_4 7;
BA_ "Platform_VMCU1_Sig" SG_ 2147485168 DiagFaultStat_WRCS_sg_UB_ISig_4 1;
BA_ "GenSigSendType" SG_ 2147485168 DiagFaultStat_WRCS_DtcIdB_ISig_4 1;
BA_ "NeedsUpdateBit" SG_ 2147485168 DiagFaultStat_WRCS_DtcIdB_ISig_4 1;
BA_ "Platform_VMCU1_Sig" SG_ 2147485168 DiagFaultStat_WRCS_DtcIdB_ISig_4 1;
BA_ "GenSigSendType" SG_ 2147485168 DiagFaultStat_WRCS_FailTB_ISig_4 1;
BA_ "NeedsUpdateBit" SG_ 2147485168 DiagFaultStat_WRCS_FailTB_ISig_4 1;
BA_ "Platform_VMCU1_Sig" SG_ 2147485168 DiagFaultStat_WRCS_FailTB_ISig_4 1;
BA_ "GenSigSendType" SG_ 2147485168 DiagFaultStat_WRCS_FailTA_ISig_4 1;
BA_ "NeedsUpdateBit" SG_ 2147485168 DiagFaultStat_WRCS_FailTA_ISig_4 1;
BA_ "Platform_VMCU1_Sig" SG_ 2147485168 DiagFaultStat_WRCS_FailTA_ISig_4 1;
BA_ "GenSigSendType" SG_ 2147485168 DiagFaultStat_WRCS_DtcIdA_ISig_4 1;
BA_ "NeedsUpdateBit" SG_ 2147485168 DiagFaultStat_WRCS_DtcIdA_ISig_4 1;
BA_ "Platform_VMCU1_Sig" SG_ 2147485168 DiagFaultStat_WRCS_DtcIdA_ISig_4 1;
BA_ "GenSigSendType" SG_ 2147485136 DiagFaultStat_VMCU_DtcIdA_ISig_4 3;
BA_ "NeedsUpdateBit" SG_ 2147485136 DiagFaultStat_VMCU_DtcIdA_ISig_4 1;
BA_ "Platform_VMCU1_Sig" SG_ 2147485136 DiagFaultStat_VMCU_DtcIdA_ISig_4 1;
BA_ "GenSigSendType" SG_ 2147485136 DiagFaultStat_VMCU_EcuAdr_ISig_4 3;
BA_ "GenSigStartValue" SG_ 2147485136 DiagFaultStat_VMCU_EcuAdr_ISig_4 255;
BA_ "NeedsUpdateBit" SG_ 2147485136 DiagFaultStat_VMCU_EcuAdr_ISig_4 1;
BA_ "Platform_VMCU1_Sig" SG_ 2147485136 DiagFaultStat_VMCU_EcuAdr_ISig_4 1;
BA_ "GenSigSendType" SG_ 2147485136 DiagFaultStat_VMCU_FailTA_ISig_4 3;
BA_ "NeedsUpdateBit" SG_ 2147485136 DiagFaultStat_VMCU_FailTA_ISig_4 1;
BA_ "Platform_VMCU1_Sig" SG_ 2147485136 DiagFaultStat_VMCU_FailTA_ISig_4 1;
BA_ "GenSigSendType" SG_ 2147485136 DiagFaultStat_VMCU_FailTB_ISig_4 3;
BA_ "NeedsUpdateBit" SG_ 2147485136 DiagFaultStat_VMCU_FailTB_ISig_4 1;
BA_ "Platform_VMCU1_Sig" SG_ 2147485136 DiagFaultStat_VMCU_FailTB_ISig_4 1;
BA_ "GenSigSendType" SG_ 2147485136 DiagFaultStat_VMCU_DtcIdB_ISig_4 3;
BA_ "NeedsUpdateBit" SG_ 2147485136 DiagFaultStat_VMCU_DtcIdB_ISig_4 1;
BA_ "Platform_VMCU1_Sig" SG_ 2147485136 DiagFaultStat_VMCU_DtcIdB_ISig_4 1;
BA_ "GenSigSendType" SG_ 2147485136 DiagFaultStat_VMCU_sg_UB_ISig_4 7;
BA_ "Platform_VMCU1_Sig" SG_ 2147485136 DiagFaultStat_VMCU_sg_UB_ISig_4 1;
BA_ "GenSigSendType" SG_ 2147485150 DiagFaultStat_TPM_EcuAdr_ISig_4 1;
BA_ "GenSigStartValue" SG_ 2147485150 DiagFaultStat_TPM_EcuAdr_ISig_4 255;
BA_ "NeedsUpdateBit" SG_ 2147485150 DiagFaultStat_TPM_EcuAdr_ISig_4 1;
BA_ "Platform_VMCU1_Sig" SG_ 2147485150 DiagFaultStat_TPM_EcuAdr_ISig_4 1;
BA_ "GenSigSendType" SG_ 2147485150 DiagFaultStat_TPM_FailTB_ISig_4 1;
BA_ "NeedsUpdateBit" SG_ 2147485150 DiagFaultStat_TPM_FailTB_ISig_4 1;
BA_ "Platform_VMCU1_Sig" SG_ 2147485150 DiagFaultStat_TPM_FailTB_ISig_4 1;
BA_ "GenSigSendType" SG_ 2147485150 DiagFaultStat_TPM_DtcIdA_ISig_4 1;
BA_ "NeedsUpdateBit" SG_ 2147485150 DiagFaultStat_TPM_DtcIdA_ISig_4 1;
BA_ "Platform_VMCU1_Sig" SG_ 2147485150 DiagFaultStat_TPM_DtcIdA_ISig_4 1;
BA_ "GenSigSendType" SG_ 2147485150 DiagFaultStat_TPM_DtcIdB_ISig_4 1;
BA_ "NeedsUpdateBit" SG_ 2147485150 DiagFaultStat_TPM_DtcIdB_ISig_4 1;
BA_ "Platform_VMCU1_Sig" SG_ 2147485150 DiagFaultStat_TPM_DtcIdB_ISig_4 1;
BA_ "GenSigSendType" SG_ 2147485150 DiagFaultStat_TPM_FailTA_ISig_4 1;
BA_ "NeedsUpdateBit" SG_ 2147485150 DiagFaultStat_TPM_FailTA_ISig_4 1;
BA_ "Platform_VMCU1_Sig" SG_ 2147485150 DiagFaultStat_TPM_FailTA_ISig_4 1;
BA_ "GenSigSendType" SG_ 2147485150 DiagFaultStat_TPM_sg_UB_ISig_4 7;
BA_ "Platform_VMCU1_Sig" SG_ 2147485150 DiagFaultStat_TPM_sg_UB_ISig_4 1;
BA_ "GenSigSendType" SG_ 2147485167 DiagFaultStat_TECU_FailTA_ISig_4 3;
BA_ "GenSigMaxLatency" SG_ 2147485167 DiagFaultStat_TECU_FailTA_ISig_4 85;
BA_ "NeedsUpdateBit" SG_ 2147485167 DiagFaultStat_TECU_FailTA_ISig_4 1;
BA_ "Platform_VMCU1_Sig" SG_ 2147485167 DiagFaultStat_TECU_FailTA_ISig_4 1;
BA_ "GenSigSendType" SG_ 2147485167 DiagFaultStat_TECU_FailTB_ISig_4 3;
BA_ "GenSigMaxLatency" SG_ 2147485167 DiagFaultStat_TECU_FailTB_ISig_4 85;
BA_ "NeedsUpdateBit" SG_ 2147485167 DiagFaultStat_TECU_FailTB_ISig_4 1;
BA_ "Platform_VMCU1_Sig" SG_ 2147485167 DiagFaultStat_TECU_FailTB_ISig_4 1;
BA_ "GenSigSendType" SG_ 2147485167 DiagFaultStat_TECU_DtcIdA_ISig_4 3;
BA_ "GenSigMaxLatency" SG_ 2147485167 DiagFaultStat_TECU_DtcIdA_ISig_4 85;
BA_ "NeedsUpdateBit" SG_ 2147485167 DiagFaultStat_TECU_DtcIdA_ISig_4 1;
BA_ "Platform_VMCU1_Sig" SG_ 2147485167 DiagFaultStat_TECU_DtcIdA_ISig_4 1;
BA_ "GenSigSendType" SG_ 2147485167 DiagFaultStat_TECU_EcuAdr_ISig_4 3;
BA_ "GenSigStartValue" SG_ 2147485167 DiagFaultStat_TECU_EcuAdr_ISig_4 255;
BA_ "GenSigMaxLatency" SG_ 2147485167 DiagFaultStat_TECU_EcuAdr_ISig_4 85;
BA_ "NeedsUpdateBit" SG_ 2147485167 DiagFaultStat_TECU_EcuAdr_ISig_4 1;
BA_ "Platform_VMCU1_Sig" SG_ 2147485167 DiagFaultStat_TECU_EcuAdr_ISig_4 1;
BA_ "GenSigSendType" SG_ 2147485167 DiagFaultStat_TECU_sg_UB_ISig_4 7;
BA_ "Platform_VMCU1_Sig" SG_ 2147485167 DiagFaultStat_TECU_sg_UB_ISig_4 1;
BA_ "GenSigSendType" SG_ 2147485167 DiagFaultStat_TECU_DtcIdB_ISig_4 3;
BA_ "GenSigMaxLatency" SG_ 2147485167 DiagFaultStat_TECU_DtcIdB_ISig_4 85;
BA_ "NeedsUpdateBit" SG_ 2147485167 DiagFaultStat_TECU_DtcIdB_ISig_4 1;
BA_ "Platform_VMCU1_Sig" SG_ 2147485167 DiagFaultStat_TECU_DtcIdB_ISig_4 1;
BA_ "GenSigSendType" SG_ 2147485165 DiagFaultStat_SRS_DtcIdB_ISig_4 1;
BA_ "NeedsUpdateBit" SG_ 2147485165 DiagFaultStat_SRS_DtcIdB_ISig_4 1;
BA_ "Platform_VMCU1_Sig" SG_ 2147485165 DiagFaultStat_SRS_DtcIdB_ISig_4 1;
BA_ "GenSigSendType" SG_ 2147485165 DiagFaultStat_SRS_sg_UB_ISig_4 7;
BA_ "Platform_VMCU1_Sig" SG_ 2147485165 DiagFaultStat_SRS_sg_UB_ISig_4 1;
BA_ "GenSigSendType" SG_ 2147485165 DiagFaultStat_SRS_FailTB_ISig_4 1;
BA_ "NeedsUpdateBit" SG_ 2147485165 DiagFaultStat_SRS_FailTB_ISig_4 1;
BA_ "Platform_VMCU1_Sig" SG_ 2147485165 DiagFaultStat_SRS_FailTB_ISig_4 1;
BA_ "GenSigSendType" SG_ 2147485165 DiagFaultStat_SRS_EcuAdr_ISig_4 1;
BA_ "GenSigStartValue" SG_ 2147485165 DiagFaultStat_SRS_EcuAdr_ISig_4 255;
BA_ "NeedsUpdateBit" SG_ 2147485165 DiagFaultStat_SRS_EcuAdr_ISig_4 1;
BA_ "Platform_VMCU1_Sig" SG_ 2147485165 DiagFaultStat_SRS_EcuAdr_ISig_4 1;
BA_ "GenSigSendType" SG_ 2147485165 DiagFaultStat_SRS_DtcIdA_ISig_4 1;
BA_ "NeedsUpdateBit" SG_ 2147485165 DiagFaultStat_SRS_DtcIdA_ISig_4 1;
BA_ "Platform_VMCU1_Sig" SG_ 2147485165 DiagFaultStat_SRS_DtcIdA_ISig_4 1;
BA_ "GenSigSendType" SG_ 2147485165 DiagFaultStat_SRS_FailTA_ISig_4 1;
BA_ "NeedsUpdateBit" SG_ 2147485165 DiagFaultStat_SRS_FailTA_ISig_4 1;
BA_ "Platform_VMCU1_Sig" SG_ 2147485165 DiagFaultStat_SRS_FailTA_ISig_4 1;
BA_ "GenSigSendType" SG_ 2147485164 DiagFaultStat_RCIOM_FailTA_ISig_ 1;
BA_ "NeedsUpdateBit" SG_ 2147485164 DiagFaultStat_RCIOM_FailTA_ISig_ 1;
BA_ "Platform_VMCU1_Sig" SG_ 2147485164 DiagFaultStat_RCIOM_FailTA_ISig_ 1;
BA_ "SystemSignalLongSymbol" SG_ 2147485164 DiagFaultStat_RCIOM_FailTA_ISig_ "DiagFaultStat_RCIOM_FailTA_ISig_4";
BA_ "GenSigSendType" SG_ 2147485164 DiagFaultStat_RCIOM_FailTB_ISig_ 1;
BA_ "NeedsUpdateBit" SG_ 2147485164 DiagFaultStat_RCIOM_FailTB_ISig_ 1;
BA_ "Platform_VMCU1_Sig" SG_ 2147485164 DiagFaultStat_RCIOM_FailTB_ISig_ 1;
BA_ "SystemSignalLongSymbol" SG_ 2147485164 DiagFaultStat_RCIOM_FailTB_ISig_ "DiagFaultStat_RCIOM_FailTB_ISig_4";
BA_ "GenSigSendType" SG_ 2147485164 DiagFaultStat_RCIOM_DtcIdB_ISig_ 1;
BA_ "NeedsUpdateBit" SG_ 2147485164 DiagFaultStat_RCIOM_DtcIdB_ISig_ 1;
BA_ "Platform_VMCU1_Sig" SG_ 2147485164 DiagFaultStat_RCIOM_DtcIdB_ISig_ 1;
BA_ "SystemSignalLongSymbol" SG_ 2147485164 DiagFaultStat_RCIOM_DtcIdB_ISig_ "DiagFaultStat_RCIOM_DtcIdB_ISig_4";
BA_ "GenSigSendType" SG_ 2147485164 DiagFaultStat_RCIOM_DtcIdA_ISig_ 1;
BA_ "NeedsUpdateBit" SG_ 2147485164 DiagFaultStat_RCIOM_DtcIdA_ISig_ 1;
BA_ "Platform_VMCU1_Sig" SG_ 2147485164 DiagFaultStat_RCIOM_DtcIdA_ISig_ 1;
BA_ "SystemSignalLongSymbol" SG_ 2147485164 DiagFaultStat_RCIOM_DtcIdA_ISig_ "DiagFaultStat_RCIOM_DtcIdA_ISig_4";
BA_ "GenSigSendType" SG_ 2147485164 DiagFaultStat_RCIOM_sg_UB_ISig_4 7;
BA_ "Platform_VMCU1_Sig" SG_ 2147485164 DiagFaultStat_RCIOM_sg_UB_ISig_4 1;
BA_ "GenSigSendType" SG_ 2147485164 DiagFaultStat_RCIOM_EcuAdr_ISig_ 1;
BA_ "GenSigStartValue" SG_ 2147485164 DiagFaultStat_RCIOM_EcuAdr_ISig_ 255;
BA_ "NeedsUpdateBit" SG_ 2147485164 DiagFaultStat_RCIOM_EcuAdr_ISig_ 1;
BA_ "Platform_VMCU1_Sig" SG_ 2147485164 DiagFaultStat_RCIOM_EcuAdr_ISig_ 1;
BA_ "SystemSignalLongSymbol" SG_ 2147485164 DiagFaultStat_RCIOM_EcuAdr_ISig_ "DiagFaultStat_RCIOM_EcuAdr_ISig_4";
BA_ "GenSigSendType" SG_ 2147485163 DiagFaultStat_PDM_EcuAdr_ISig_4 1;
BA_ "GenSigStartValue" SG_ 2147485163 DiagFaultStat_PDM_EcuAdr_ISig_4 255;
BA_ "NeedsUpdateBit" SG_ 2147485163 DiagFaultStat_PDM_EcuAdr_ISig_4 1;
BA_ "Platform_VMCU1_Sig" SG_ 2147485163 DiagFaultStat_PDM_EcuAdr_ISig_4 1;
BA_ "GenSigSendType" SG_ 2147485163 DiagFaultStat_PDM_DtcIdB_ISig_4 1;
BA_ "NeedsUpdateBit" SG_ 2147485163 DiagFaultStat_PDM_DtcIdB_ISig_4 1;
BA_ "Platform_VMCU1_Sig" SG_ 2147485163 DiagFaultStat_PDM_DtcIdB_ISig_4 1;
BA_ "GenSigSendType" SG_ 2147485163 DiagFaultStat_PDM_sg_UB_ISig_4 7;
BA_ "Platform_VMCU1_Sig" SG_ 2147485163 DiagFaultStat_PDM_sg_UB_ISig_4 1;
BA_ "GenSigSendType" SG_ 2147485163 DiagFaultStat_PDM_FailTB_ISig_4 1;
BA_ "NeedsUpdateBit" SG_ 2147485163 DiagFaultStat_PDM_FailTB_ISig_4 1;
BA_ "Platform_VMCU1_Sig" SG_ 2147485163 DiagFaultStat_PDM_FailTB_ISig_4 1;
BA_ "GenSigSendType" SG_ 2147485163 DiagFaultStat_PDM_DtcIdA_ISig_4 1;
BA_ "NeedsUpdateBit" SG_ 2147485163 DiagFaultStat_PDM_DtcIdA_ISig_4 1;
BA_ "Platform_VMCU1_Sig" SG_ 2147485163 DiagFaultStat_PDM_DtcIdA_ISig_4 1;
BA_ "GenSigSendType" SG_ 2147485163 DiagFaultStat_PDM_FailTA_ISig_4 1;
BA_ "NeedsUpdateBit" SG_ 2147485163 DiagFaultStat_PDM_FailTA_ISig_4 1;
BA_ "Platform_VMCU1_Sig" SG_ 2147485163 DiagFaultStat_PDM_FailTA_ISig_4 1;
BA_ "GenSigSendType" SG_ 2147485162 DiagFaultStat_LPOS_DtcIdB_ISig_4 1;
BA_ "NeedsUpdateBit" SG_ 2147485162 DiagFaultStat_LPOS_DtcIdB_ISig_4 1;
BA_ "Platform_VMCU1_Sig" SG_ 2147485162 DiagFaultStat_LPOS_DtcIdB_ISig_4 1;
BA_ "GenSigSendType" SG_ 2147485162 DiagFaultStat_LPOS_FailTB_ISig_4 1;
BA_ "NeedsUpdateBit" SG_ 2147485162 DiagFaultStat_LPOS_FailTB_ISig_4 1;
BA_ "Platform_VMCU1_Sig" SG_ 2147485162 DiagFaultStat_LPOS_FailTB_ISig_4 1;
BA_ "GenSigSendType" SG_ 2147485162 DiagFaultStat_LPOS_DtcIdA_ISig_4 1;
BA_ "NeedsUpdateBit" SG_ 2147485162 DiagFaultStat_LPOS_DtcIdA_ISig_4 1;
BA_ "Platform_VMCU1_Sig" SG_ 2147485162 DiagFaultStat_LPOS_DtcIdA_ISig_4 1;
BA_ "GenSigSendType" SG_ 2147485162 DiagFaultStat_LPOS_FailTA_ISig_4 1;
BA_ "NeedsUpdateBit" SG_ 2147485162 DiagFaultStat_LPOS_FailTA_ISig_4 1;
BA_ "Platform_VMCU1_Sig" SG_ 2147485162 DiagFaultStat_LPOS_FailTA_ISig_4 1;
BA_ "GenSigSendType" SG_ 2147485162 DiagFaultStat_LPOS_sg_UB_ISig_4 7;
BA_ "Platform_VMCU1_Sig" SG_ 2147485162 DiagFaultStat_LPOS_sg_UB_ISig_4 1;
BA_ "GenSigSendType" SG_ 2147485162 DiagFaultStat_LPOS_EcuAdr_ISig_4 1;
BA_ "GenSigStartValue" SG_ 2147485162 DiagFaultStat_LPOS_EcuAdr_ISig_4 255;
BA_ "NeedsUpdateBit" SG_ 2147485162 DiagFaultStat_LPOS_EcuAdr_ISig_4 1;
BA_ "Platform_VMCU1_Sig" SG_ 2147485162 DiagFaultStat_LPOS_EcuAdr_ISig_4 1;
BA_ "GenSigSendType" SG_ 2147485161 DiagFaultStat_LECM_EcuAdr_ISig_4 1;
BA_ "GenSigStartValue" SG_ 2147485161 DiagFaultStat_LECM_EcuAdr_ISig_4 255;
BA_ "NeedsUpdateBit" SG_ 2147485161 DiagFaultStat_LECM_EcuAdr_ISig_4 1;
BA_ "Platform_VMCU1_Sig" SG_ 2147485161 DiagFaultStat_LECM_EcuAdr_ISig_4 1;
BA_ "GenSigSendType" SG_ 2147485161 DiagFaultStat_LECM_FailTB_ISig_4 1;
BA_ "NeedsUpdateBit" SG_ 2147485161 DiagFaultStat_LECM_FailTB_ISig_4 1;
BA_ "Platform_VMCU1_Sig" SG_ 2147485161 DiagFaultStat_LECM_FailTB_ISig_4 1;
BA_ "GenSigSendType" SG_ 2147485161 DiagFaultStat_LECM_FailTA_ISig_4 1;
BA_ "NeedsUpdateBit" SG_ 2147485161 DiagFaultStat_LECM_FailTA_ISig_4 1;
BA_ "Platform_VMCU1_Sig" SG_ 2147485161 DiagFaultStat_LECM_FailTA_ISig_4 1;
BA_ "GenSigSendType" SG_ 2147485161 DiagFaultStat_LECM_sg_UB_ISig_4 7;
BA_ "Platform_VMCU1_Sig" SG_ 2147485161 DiagFaultStat_LECM_sg_UB_ISig_4 1;
BA_ "GenSigSendType" SG_ 2147485161 DiagFaultStat_LECM_DtcIdB_ISig_4 1;
BA_ "NeedsUpdateBit" SG_ 2147485161 DiagFaultStat_LECM_DtcIdB_ISig_4 1;
BA_ "Platform_VMCU1_Sig" SG_ 2147485161 DiagFaultStat_LECM_DtcIdB_ISig_4 1;
BA_ "GenSigSendType" SG_ 2147485161 DiagFaultStat_LECM_DtcIdA_ISig_4 1;
BA_ "NeedsUpdateBit" SG_ 2147485161 DiagFaultStat_LECM_DtcIdA_ISig_4 1;
BA_ "Platform_VMCU1_Sig" SG_ 2147485161 DiagFaultStat_LECM_DtcIdA_ISig_4 1;
BA_ "GenSigSendType" SG_ 2147485145 DiagFaultStat_GFHCM2_DtcIdB_ISig 3;
BA_ "NeedsUpdateBit" SG_ 2147485145 DiagFaultStat_GFHCM2_DtcIdB_ISig 1;
BA_ "SystemSignalLongSymbol" SG_ 2147485145 DiagFaultStat_GFHCM2_DtcIdB_ISig "DiagFaultStat_GFHCM2_DtcIdB_ISig_4";
BA_ "GenSigSendType" SG_ 2147485145 DiagFaultStat_GFHCM2_sg_UB_ISig_ 7;
BA_ "SystemSignalLongSymbol" SG_ 2147485145 DiagFaultStat_GFHCM2_sg_UB_ISig_ "DiagFaultStat_GFHCM2_sg_UB_ISig_4";
BA_ "GenSigSendType" SG_ 2147485145 DiagFaultStat_GFHCM2_DtcIdA_ISig 3;
BA_ "NeedsUpdateBit" SG_ 2147485145 DiagFaultStat_GFHCM2_DtcIdA_ISig 1;
BA_ "SystemSignalLongSymbol" SG_ 2147485145 DiagFaultStat_GFHCM2_DtcIdA_ISig "DiagFaultStat_GFHCM2_DtcIdA_ISig_4";
BA_ "GenSigSendType" SG_ 2147485145 DiagFaultStat_GFHCM2_FailTA_ISig 3;
BA_ "NeedsUpdateBit" SG_ 2147485145 DiagFaultStat_GFHCM2_FailTA_ISig 1;
BA_ "SystemSignalLongSymbol" SG_ 2147485145 DiagFaultStat_GFHCM2_FailTA_ISig "DiagFaultStat_GFHCM2_FailTA_ISig_4";
BA_ "GenSigSendType" SG_ 2147485145 DiagFaultStat_GFHCM2_EcuAdr_ISig 3;
BA_ "GenSigStartValue" SG_ 2147485145 DiagFaultStat_GFHCM2_EcuAdr_ISig 255;
BA_ "NeedsUpdateBit" SG_ 2147485145 DiagFaultStat_GFHCM2_EcuAdr_ISig 1;
BA_ "SystemSignalLongSymbol" SG_ 2147485145 DiagFaultStat_GFHCM2_EcuAdr_ISig "DiagFaultStat_GFHCM2_EcuAdr_ISig_4";
BA_ "GenSigSendType" SG_ 2147485145 DiagFaultStat_GFHCM2_FailTB_ISig 3;
BA_ "NeedsUpdateBit" SG_ 2147485145 DiagFaultStat_GFHCM2_FailTB_ISig 1;
BA_ "SystemSignalLongSymbol" SG_ 2147485145 DiagFaultStat_GFHCM2_FailTB_ISig "DiagFaultStat_GFHCM2_FailTB_ISig_4";
BA_ "GenSigSendType" SG_ 2147485144 DiagFaultStat_GFHCM1_DtcIdA_ISig 3;
BA_ "NeedsUpdateBit" SG_ 2147485144 DiagFaultStat_GFHCM1_DtcIdA_ISig 1;
BA_ "SystemSignalLongSymbol" SG_ 2147485144 DiagFaultStat_GFHCM1_DtcIdA_ISig "DiagFaultStat_GFHCM1_DtcIdA_ISig_4";
BA_ "GenSigSendType" SG_ 2147485144 DiagFaultStat_GFHCM1_FailTB_ISig 3;
BA_ "NeedsUpdateBit" SG_ 2147485144 DiagFaultStat_GFHCM1_FailTB_ISig 1;
BA_ "SystemSignalLongSymbol" SG_ 2147485144 DiagFaultStat_GFHCM1_FailTB_ISig "DiagFaultStat_GFHCM1_FailTB_ISig_4";
BA_ "GenSigSendType" SG_ 2147485144 DiagFaultStat_GFHCM1_FailTA_ISig 3;
BA_ "NeedsUpdateBit" SG_ 2147485144 DiagFaultStat_GFHCM1_FailTA_ISig 1;
BA_ "SystemSignalLongSymbol" SG_ 2147485144 DiagFaultStat_GFHCM1_FailTA_ISig "DiagFaultStat_GFHCM1_FailTA_ISig_4";
BA_ "GenSigSendType" SG_ 2147485144 DiagFaultStat_GFHCM1_sg_UB_ISig_ 7;
BA_ "SystemSignalLongSymbol" SG_ 2147485144 DiagFaultStat_GFHCM1_sg_UB_ISig_ "DiagFaultStat_GFHCM1_sg_UB_ISig_4";
BA_ "GenSigSendType" SG_ 2147485144 DiagFaultStat_GFHCM1_EcuAdr_ISig 3;
BA_ "GenSigStartValue" SG_ 2147485144 DiagFaultStat_GFHCM1_EcuAdr_ISig 255;
BA_ "NeedsUpdateBit" SG_ 2147485144 DiagFaultStat_GFHCM1_EcuAdr_ISig 1;
BA_ "SystemSignalLongSymbol" SG_ 2147485144 DiagFaultStat_GFHCM1_EcuAdr_ISig "DiagFaultStat_GFHCM1_EcuAdr_ISig_4";
BA_ "GenSigSendType" SG_ 2147485144 DiagFaultStat_GFHCM1_DtcIdB_ISig 3;
BA_ "NeedsUpdateBit" SG_ 2147485144 DiagFaultStat_GFHCM1_DtcIdB_ISig 1;
BA_ "SystemSignalLongSymbol" SG_ 2147485144 DiagFaultStat_GFHCM1_DtcIdB_ISig "DiagFaultStat_GFHCM1_DtcIdB_ISig_4";
BA_ "GenSigSendType" SG_ 2147485160 DiagFaultStat_FLS_DtcIdB_ISig_4 1;
BA_ "NeedsUpdateBit" SG_ 2147485160 DiagFaultStat_FLS_DtcIdB_ISig_4 1;
BA_ "Platform_VMCU1_Sig" SG_ 2147485160 DiagFaultStat_FLS_DtcIdB_ISig_4 1;
BA_ "GenSigSendType" SG_ 2147485160 DiagFaultStat_FLS_FailTB_ISig_4 1;
BA_ "NeedsUpdateBit" SG_ 2147485160 DiagFaultStat_FLS_FailTB_ISig_4 1;
BA_ "Platform_VMCU1_Sig" SG_ 2147485160 DiagFaultStat_FLS_FailTB_ISig_4 1;
BA_ "GenSigSendType" SG_ 2147485160 DiagFaultStat_FLS_DtcIdA_ISig_4 1;
BA_ "NeedsUpdateBit" SG_ 2147485160 DiagFaultStat_FLS_DtcIdA_ISig_4 1;
BA_ "Platform_VMCU1_Sig" SG_ 2147485160 DiagFaultStat_FLS_DtcIdA_ISig_4 1;
BA_ "GenSigSendType" SG_ 2147485160 DiagFaultStat_FLS_sg_UB_ISig_4 7;
BA_ "Platform_VMCU1_Sig" SG_ 2147485160 DiagFaultStat_FLS_sg_UB_ISig_4 1;
BA_ "GenSigSendType" SG_ 2147485160 DiagFaultStat_FLS_EcuAdr_ISig_4 1;
BA_ "GenSigStartValue" SG_ 2147485160 DiagFaultStat_FLS_EcuAdr_ISig_4 255;
BA_ "NeedsUpdateBit" SG_ 2147485160 DiagFaultStat_FLS_EcuAdr_ISig_4 1;
BA_ "Platform_VMCU1_Sig" SG_ 2147485160 DiagFaultStat_FLS_EcuAdr_ISig_4 1;
BA_ "GenSigSendType" SG_ 2147485160 DiagFaultStat_FLS_FailTA_ISig_4 1;
BA_ "NeedsUpdateBit" SG_ 2147485160 DiagFaultStat_FLS_FailTA_ISig_4 1;
BA_ "Platform_VMCU1_Sig" SG_ 2147485160 DiagFaultStat_FLS_FailTA_ISig_4 1;
BA_ "GenSigSendType" SG_ 2147485147 DiagFaultStat_FCIOM_DtcIdB_ISig_ 1;
BA_ "NeedsUpdateBit" SG_ 2147485147 DiagFaultStat_FCIOM_DtcIdB_ISig_ 1;
BA_ "Platform_VMCU1_Sig" SG_ 2147485147 DiagFaultStat_FCIOM_DtcIdB_ISig_ 1;
BA_ "SystemSignalLongSymbol" SG_ 2147485147 DiagFaultStat_FCIOM_DtcIdB_ISig_ "DiagFaultStat_FCIOM_DtcIdB_ISig_4";
BA_ "GenSigSendType" SG_ 2147485147 DiagFaultStat_FCIOM_sg_UB_ISig_4 7;
BA_ "Platform_VMCU1_Sig" SG_ 2147485147 DiagFaultStat_FCIOM_sg_UB_ISig_4 1;
BA_ "GenSigSendType" SG_ 2147485147 DiagFaultStat_FCIOM_FailTA_ISig_ 1;
BA_ "NeedsUpdateBit" SG_ 2147485147 DiagFaultStat_FCIOM_FailTA_ISig_ 1;
BA_ "Platform_VMCU1_Sig" SG_ 2147485147 DiagFaultStat_FCIOM_FailTA_ISig_ 1;
BA_ "SystemSignalLongSymbol" SG_ 2147485147 DiagFaultStat_FCIOM_FailTA_ISig_ "DiagFaultStat_FCIOM_FailTA_ISig_4";
BA_ "GenSigSendType" SG_ 2147485147 DiagFaultStat_FCIOM_FailTB_ISig_ 1;
BA_ "NeedsUpdateBit" SG_ 2147485147 DiagFaultStat_FCIOM_FailTB_ISig_ 1;
BA_ "Platform_VMCU1_Sig" SG_ 2147485147 DiagFaultStat_FCIOM_FailTB_ISig_ 1;
BA_ "SystemSignalLongSymbol" SG_ 2147485147 DiagFaultStat_FCIOM_FailTB_ISig_ "DiagFaultStat_FCIOM_FailTB_ISig_4";
BA_ "GenSigSendType" SG_ 2147485147 DiagFaultStat_FCIOM_EcuAdr_ISig_ 1;
BA_ "GenSigStartValue" SG_ 2147485147 DiagFaultStat_FCIOM_EcuAdr_ISig_ 255;
BA_ "NeedsUpdateBit" SG_ 2147485147 DiagFaultStat_FCIOM_EcuAdr_ISig_ 1;
BA_ "Platform_VMCU1_Sig" SG_ 2147485147 DiagFaultStat_FCIOM_EcuAdr_ISig_ 1;
BA_ "SystemSignalLongSymbol" SG_ 2147485147 DiagFaultStat_FCIOM_EcuAdr_ISig_ "DiagFaultStat_FCIOM_EcuAdr_ISig_4";
BA_ "GenSigSendType" SG_ 2147485147 DiagFaultStat_FCIOM_DtcIdA_ISig_ 1;
BA_ "NeedsUpdateBit" SG_ 2147485147 DiagFaultStat_FCIOM_DtcIdA_ISig_ 1;
BA_ "Platform_VMCU1_Sig" SG_ 2147485147 DiagFaultStat_FCIOM_DtcIdA_ISig_ 1;
BA_ "SystemSignalLongSymbol" SG_ 2147485147 DiagFaultStat_FCIOM_DtcIdA_ISig_ "DiagFaultStat_FCIOM_DtcIdA_ISig_4";
BA_ "GenSigSendType" SG_ 2147485139 DiagFaultStat_FAS_FailTA_ISig_4 1;
BA_ "NeedsUpdateBit" SG_ 2147485139 DiagFaultStat_FAS_FailTA_ISig_4 1;
BA_ "Platform_VMCU1_Sig" SG_ 2147485139 DiagFaultStat_FAS_FailTA_ISig_4 1;
BA_ "GenSigSendType" SG_ 2147485139 DiagFaultStat_FAS_DtcIdA_ISig_4 1;
BA_ "NeedsUpdateBit" SG_ 2147485139 DiagFaultStat_FAS_DtcIdA_ISig_4 1;
BA_ "Platform_VMCU1_Sig" SG_ 2147485139 DiagFaultStat_FAS_DtcIdA_ISig_4 1;
BA_ "GenSigSendType" SG_ 2147485139 DiagFaultStat_FAS_FailTB_ISig_4 1;
BA_ "NeedsUpdateBit" SG_ 2147485139 DiagFaultStat_FAS_FailTB_ISig_4 1;
BA_ "Platform_VMCU1_Sig" SG_ 2147485139 DiagFaultStat_FAS_FailTB_ISig_4 1;
BA_ "GenSigSendType" SG_ 2147485139 DiagFaultStat_FAS_EcuAdr_ISig_4 1;
BA_ "GenSigStartValue" SG_ 2147485139 DiagFaultStat_FAS_EcuAdr_ISig_4 255;
BA_ "NeedsUpdateBit" SG_ 2147485139 DiagFaultStat_FAS_EcuAdr_ISig_4 1;
BA_ "Platform_VMCU1_Sig" SG_ 2147485139 DiagFaultStat_FAS_EcuAdr_ISig_4 1;
BA_ "GenSigSendType" SG_ 2147485139 DiagFaultStat_FAS_sg_UB_ISig_4 7;
BA_ "Platform_VMCU1_Sig" SG_ 2147485139 DiagFaultStat_FAS_sg_UB_ISig_4 1;
BA_ "GenSigSendType" SG_ 2147485139 DiagFaultStat_FAS_DtcIdB_ISig_4 1;
BA_ "NeedsUpdateBit" SG_ 2147485139 DiagFaultStat_FAS_DtcIdB_ISig_4 1;
BA_ "Platform_VMCU1_Sig" SG_ 2147485139 DiagFaultStat_FAS_DtcIdB_ISig_4 1;
BA_ "GenSigSendType" SG_ 2147485159 DiagFaultStat_EMS_EcuAdr_ISig_4 3;
BA_ "GenSigStartValue" SG_ 2147485159 DiagFaultStat_EMS_EcuAdr_ISig_4 255;
BA_ "GenSigMaxLatency" SG_ 2147485159 DiagFaultStat_EMS_EcuAdr_ISig_4 85;
BA_ "NeedsUpdateBit" SG_ 2147485159 DiagFaultStat_EMS_EcuAdr_ISig_4 1;
BA_ "Platform_VMCU1_Sig" SG_ 2147485159 DiagFaultStat_EMS_EcuAdr_ISig_4 1;
BA_ "GenSigSendType" SG_ 2147485159 DiagFaultStat_EMS_DtcIdB_ISig_4 3;
BA_ "GenSigMaxLatency" SG_ 2147485159 DiagFaultStat_EMS_DtcIdB_ISig_4 85;
BA_ "NeedsUpdateBit" SG_ 2147485159 DiagFaultStat_EMS_DtcIdB_ISig_4 1;
BA_ "Platform_VMCU1_Sig" SG_ 2147485159 DiagFaultStat_EMS_DtcIdB_ISig_4 1;
BA_ "GenSigSendType" SG_ 2147485159 DiagFaultStat_EMS_DtcIdA_ISig_4 3;
BA_ "GenSigMaxLatency" SG_ 2147485159 DiagFaultStat_EMS_DtcIdA_ISig_4 85;
BA_ "NeedsUpdateBit" SG_ 2147485159 DiagFaultStat_EMS_DtcIdA_ISig_4 1;
BA_ "Platform_VMCU1_Sig" SG_ 2147485159 DiagFaultStat_EMS_DtcIdA_ISig_4 1;
BA_ "GenSigSendType" SG_ 2147485159 DiagFaultStat_EMS_sg_UB_ISig_4 7;
BA_ "Platform_VMCU1_Sig" SG_ 2147485159 DiagFaultStat_EMS_sg_UB_ISig_4 1;
BA_ "GenSigSendType" SG_ 2147485159 DiagFaultStat_EMS_FailTB_ISig_4 3;
BA_ "GenSigMaxLatency" SG_ 2147485159 DiagFaultStat_EMS_FailTB_ISig_4 85;
BA_ "NeedsUpdateBit" SG_ 2147485159 DiagFaultStat_EMS_FailTB_ISig_4 1;
BA_ "Platform_VMCU1_Sig" SG_ 2147485159 DiagFaultStat_EMS_FailTB_ISig_4 1;
BA_ "GenSigSendType" SG_ 2147485159 DiagFaultStat_EMS_FailTA_ISig_4 3;
BA_ "GenSigMaxLatency" SG_ 2147485159 DiagFaultStat_EMS_FailTA_ISig_4 85;
BA_ "NeedsUpdateBit" SG_ 2147485159 DiagFaultStat_EMS_FailTA_ISig_4 1;
BA_ "Platform_VMCU1_Sig" SG_ 2147485159 DiagFaultStat_EMS_FailTA_ISig_4 1;
BA_ "GenSigSendType" SG_ 2147485141 DiagFaultStat_EAS_DtcIdB_ISig_4 1;
BA_ "NeedsUpdateBit" SG_ 2147485141 DiagFaultStat_EAS_DtcIdB_ISig_4 1;
BA_ "Platform_VMCU1_Sig" SG_ 2147485141 DiagFaultStat_EAS_DtcIdB_ISig_4 1;
BA_ "GenSigSendType" SG_ 2147485141 DiagFaultStat_EAS_DtcIdA_ISig_4 1;
BA_ "NeedsUpdateBit" SG_ 2147485141 DiagFaultStat_EAS_DtcIdA_ISig_4 1;
BA_ "Platform_VMCU1_Sig" SG_ 2147485141 DiagFaultStat_EAS_DtcIdA_ISig_4 1;
BA_ "GenSigSendType" SG_ 2147485141 DiagFaultStat_EAS_sg_UB_ISig_4 7;
BA_ "Platform_VMCU1_Sig" SG_ 2147485141 DiagFaultStat_EAS_sg_UB_ISig_4 1;
BA_ "GenSigSendType" SG_ 2147485141 DiagFaultStat_EAS_FailTB_ISig_4 1;
BA_ "NeedsUpdateBit" SG_ 2147485141 DiagFaultStat_EAS_FailTB_ISig_4 1;
BA_ "Platform_VMCU1_Sig" SG_ 2147485141 DiagFaultStat_EAS_FailTB_ISig_4 1;
BA_ "GenSigSendType" SG_ 2147485141 DiagFaultStat_EAS_FailTA_ISig_4 1;
BA_ "NeedsUpdateBit" SG_ 2147485141 DiagFaultStat_EAS_FailTA_ISig_4 1;
BA_ "Platform_VMCU1_Sig" SG_ 2147485141 DiagFaultStat_EAS_FailTA_ISig_4 1;
BA_ "GenSigSendType" SG_ 2147485141 DiagFaultStat_EAS_EcuAdr_ISig_4 1;
BA_ "GenSigStartValue" SG_ 2147485141 DiagFaultStat_EAS_EcuAdr_ISig_4 255;
BA_ "NeedsUpdateBit" SG_ 2147485141 DiagFaultStat_EAS_EcuAdr_ISig_4 1;
BA_ "Platform_VMCU1_Sig" SG_ 2147485141 DiagFaultStat_EAS_EcuAdr_ISig_4 1;
BA_ "GenSigSendType" SG_ 2147485158 DiagFaultStat_DDM_DtcIdA_ISig_4 1;
BA_ "NeedsUpdateBit" SG_ 2147485158 DiagFaultStat_DDM_DtcIdA_ISig_4 1;
BA_ "Platform_VMCU1_Sig" SG_ 2147485158 DiagFaultStat_DDM_DtcIdA_ISig_4 1;
BA_ "GenSigSendType" SG_ 2147485158 DiagFaultStat_DDM_sg_UB_ISig_4 7;
BA_ "Platform_VMCU1_Sig" SG_ 2147485158 DiagFaultStat_DDM_sg_UB_ISig_4 1;
BA_ "GenSigSendType" SG_ 2147485158 DiagFaultStat_DDM_FailTA_ISig_4 1;
BA_ "NeedsUpdateBit" SG_ 2147485158 DiagFaultStat_DDM_FailTA_ISig_4 1;
BA_ "Platform_VMCU1_Sig" SG_ 2147485158 DiagFaultStat_DDM_FailTA_ISig_4 1;
BA_ "GenSigSendType" SG_ 2147485158 DiagFaultStat_DDM_EcuAdr_ISig_4 1;
BA_ "GenSigStartValue" SG_ 2147485158 DiagFaultStat_DDM_EcuAdr_ISig_4 255;
BA_ "NeedsUpdateBit" SG_ 2147485158 DiagFaultStat_DDM_EcuAdr_ISig_4 1;
BA_ "Platform_VMCU1_Sig" SG_ 2147485158 DiagFaultStat_DDM_EcuAdr_ISig_4 1;
BA_ "GenSigSendType" SG_ 2147485158 DiagFaultStat_DDM_FailTB_ISig_4 1;
BA_ "NeedsUpdateBit" SG_ 2147485158 DiagFaultStat_DDM_FailTB_ISig_4 1;
BA_ "Platform_VMCU1_Sig" SG_ 2147485158 DiagFaultStat_DDM_FailTB_ISig_4 1;
BA_ "GenSigSendType" SG_ 2147485158 DiagFaultStat_DDM_DtcIdB_ISig_4 1;
BA_ "NeedsUpdateBit" SG_ 2147485158 DiagFaultStat_DDM_DtcIdB_ISig_4 1;
BA_ "Platform_VMCU1_Sig" SG_ 2147485158 DiagFaultStat_DDM_DtcIdB_ISig_4 1;
BA_ "GenSigSendType" SG_ 2147485157 DiagFaultStat_DACU_DtcIdB_ISig_4 3;
BA_ "NeedsUpdateBit" SG_ 2147485157 DiagFaultStat_DACU_DtcIdB_ISig_4 1;
BA_ "Platform_VMCU1_Sig" SG_ 2147485157 DiagFaultStat_DACU_DtcIdB_ISig_4 1;
BA_ "GenSigSendType" SG_ 2147485157 DiagFaultStat_DACU_DtcIdA_ISig_4 3;
BA_ "NeedsUpdateBit" SG_ 2147485157 DiagFaultStat_DACU_DtcIdA_ISig_4 1;
BA_ "Platform_VMCU1_Sig" SG_ 2147485157 DiagFaultStat_DACU_DtcIdA_ISig_4 1;
BA_ "GenSigSendType" SG_ 2147485157 DiagFaultStat_DACU_EcuAdr_ISig_4 3;
BA_ "GenSigStartValue" SG_ 2147485157 DiagFaultStat_DACU_EcuAdr_ISig_4 255;
BA_ "NeedsUpdateBit" SG_ 2147485157 DiagFaultStat_DACU_EcuAdr_ISig_4 1;
BA_ "Platform_VMCU1_Sig" SG_ 2147485157 DiagFaultStat_DACU_EcuAdr_ISig_4 1;
BA_ "GenSigSendType" SG_ 2147485157 DiagFaultStat_DACU_FailTB_ISig_4 3;
BA_ "NeedsUpdateBit" SG_ 2147485157 DiagFaultStat_DACU_FailTB_ISig_4 1;
BA_ "Platform_VMCU1_Sig" SG_ 2147485157 DiagFaultStat_DACU_FailTB_ISig_4 1;
BA_ "GenSigSendType" SG_ 2147485157 DiagFaultStat_DACU_FailTA_ISig_4 3;
BA_ "NeedsUpdateBit" SG_ 2147485157 DiagFaultStat_DACU_FailTA_ISig_4 1;
BA_ "Platform_VMCU1_Sig" SG_ 2147485157 DiagFaultStat_DACU_FailTA_ISig_4 1;
BA_ "GenSigSendType" SG_ 2147485157 DiagFaultStat_DACU_sg_UB_ISig_4 7;
BA_ "Platform_VMCU1_Sig" SG_ 2147485157 DiagFaultStat_DACU_sg_UB_ISig_4 1;
BA_ "GenSigSendType" SG_ 2147485156 DiagFaultStat_CIOM_DtcIdA_ISig_4 3;
BA_ "NeedsUpdateBit" SG_ 2147485156 DiagFaultStat_CIOM_DtcIdA_ISig_4 1;
BA_ "Platform_VMCU1_Sig" SG_ 2147485156 DiagFaultStat_CIOM_DtcIdA_ISig_4 1;
BA_ "GenSigSendType" SG_ 2147485156 DiagFaultStat_CIOM_EcuAdr_ISig_4 3;
BA_ "GenSigStartValue" SG_ 2147485156 DiagFaultStat_CIOM_EcuAdr_ISig_4 255;
BA_ "NeedsUpdateBit" SG_ 2147485156 DiagFaultStat_CIOM_EcuAdr_ISig_4 1;
BA_ "Platform_VMCU1_Sig" SG_ 2147485156 DiagFaultStat_CIOM_EcuAdr_ISig_4 1;
BA_ "GenSigSendType" SG_ 2147485156 DiagFaultStat_CIOM_sg_UB_ISig_4 7;
BA_ "Platform_VMCU1_Sig" SG_ 2147485156 DiagFaultStat_CIOM_sg_UB_ISig_4 1;
BA_ "GenSigSendType" SG_ 2147485156 DiagFaultStat_CIOM_DtcIdB_ISig_4 3;
BA_ "NeedsUpdateBit" SG_ 2147485156 DiagFaultStat_CIOM_DtcIdB_ISig_4 1;
BA_ "Platform_VMCU1_Sig" SG_ 2147485156 DiagFaultStat_CIOM_DtcIdB_ISig_4 1;
BA_ "GenSigSendType" SG_ 2147485156 DiagFaultStat_CIOM_FailTA_ISig_4 3;
BA_ "NeedsUpdateBit" SG_ 2147485156 DiagFaultStat_CIOM_FailTA_ISig_4 1;
BA_ "Platform_VMCU1_Sig" SG_ 2147485156 DiagFaultStat_CIOM_FailTA_ISig_4 1;
BA_ "GenSigSendType" SG_ 2147485156 DiagFaultStat_CIOM_FailTB_ISig_4 3;
BA_ "NeedsUpdateBit" SG_ 2147485156 DiagFaultStat_CIOM_FailTB_ISig_4 1;
BA_ "Platform_VMCU1_Sig" SG_ 2147485156 DiagFaultStat_CIOM_FailTB_ISig_4 1;
BA_ "GenSigSendType" SG_ 2147485155 DiagFaultStat_CCM_FailTB_ISig_4 1;
BA_ "NeedsUpdateBit" SG_ 2147485155 DiagFaultStat_CCM_FailTB_ISig_4 1;
BA_ "Platform_VMCU1_Sig" SG_ 2147485155 DiagFaultStat_CCM_FailTB_ISig_4 1;
BA_ "GenSigSendType" SG_ 2147485155 DiagFaultStat_CCM_DtcIdA_ISig_4 1;
BA_ "NeedsUpdateBit" SG_ 2147485155 DiagFaultStat_CCM_DtcIdA_ISig_4 1;
BA_ "Platform_VMCU1_Sig" SG_ 2147485155 DiagFaultStat_CCM_DtcIdA_ISig_4 1;
BA_ "GenSigSendType" SG_ 2147485155 DiagFaultStat_CCM_DtcIdB_ISig_4 1;
BA_ "NeedsUpdateBit" SG_ 2147485155 DiagFaultStat_CCM_DtcIdB_ISig_4 1;
BA_ "Platform_VMCU1_Sig" SG_ 2147485155 DiagFaultStat_CCM_DtcIdB_ISig_4 1;
BA_ "GenSigSendType" SG_ 2147485155 DiagFaultStat_CCM_EcuAdr_ISig_4 1;
BA_ "GenSigStartValue" SG_ 2147485155 DiagFaultStat_CCM_EcuAdr_ISig_4 255;
BA_ "NeedsUpdateBit" SG_ 2147485155 DiagFaultStat_CCM_EcuAdr_ISig_4 1;
BA_ "Platform_VMCU1_Sig" SG_ 2147485155 DiagFaultStat_CCM_EcuAdr_ISig_4 1;
BA_ "GenSigSendType" SG_ 2147485155 DiagFaultStat_CCM_FailTA_ISig_4 1;
BA_ "NeedsUpdateBit" SG_ 2147485155 DiagFaultStat_CCM_FailTA_ISig_4 1;
BA_ "Platform_VMCU1_Sig" SG_ 2147485155 DiagFaultStat_CCM_FailTA_ISig_4 1;
BA_ "GenSigSendType" SG_ 2147485155 DiagFaultStat_CCM_sg_UB_ISig_4 7;
BA_ "Platform_VMCU1_Sig" SG_ 2147485155 DiagFaultStat_CCM_sg_UB_ISig_4 1;
BA_ "GenSigSendType" SG_ 2147485138 DiagFaultStat_CCIOM_sg_UB_ISig_4 7;
BA_ "Platform_VMCU1_Sig" SG_ 2147485138 DiagFaultStat_CCIOM_sg_UB_ISig_4 1;
BA_ "GenSigSendType" SG_ 2147485138 DiagFaultStat_CCIOM_EcuAdr_ISig_ 1;
BA_ "GenSigStartValue" SG_ 2147485138 DiagFaultStat_CCIOM_EcuAdr_ISig_ 255;
BA_ "NeedsUpdateBit" SG_ 2147485138 DiagFaultStat_CCIOM_EcuAdr_ISig_ 1;
BA_ "Platform_VMCU1_Sig" SG_ 2147485138 DiagFaultStat_CCIOM_EcuAdr_ISig_ 1;
BA_ "SystemSignalLongSymbol" SG_ 2147485138 DiagFaultStat_CCIOM_EcuAdr_ISig_ "DiagFaultStat_CCIOM_EcuAdr_ISig_4";
BA_ "GenSigSendType" SG_ 2147485138 DiagFaultStat_CCIOM_FailTA_ISig_ 1;
BA_ "NeedsUpdateBit" SG_ 2147485138 DiagFaultStat_CCIOM_FailTA_ISig_ 1;
BA_ "Platform_VMCU1_Sig" SG_ 2147485138 DiagFaultStat_CCIOM_FailTA_ISig_ 1;
BA_ "SystemSignalLongSymbol" SG_ 2147485138 DiagFaultStat_CCIOM_FailTA_ISig_ "DiagFaultStat_CCIOM_FailTA_ISig_4";
BA_ "GenSigSendType" SG_ 2147485138 DiagFaultStat_CCIOM_DtcIdB_ISig_ 1;
BA_ "NeedsUpdateBit" SG_ 2147485138 DiagFaultStat_CCIOM_DtcIdB_ISig_ 1;
BA_ "Platform_VMCU1_Sig" SG_ 2147485138 DiagFaultStat_CCIOM_DtcIdB_ISig_ 1;
BA_ "SystemSignalLongSymbol" SG_ 2147485138 DiagFaultStat_CCIOM_DtcIdB_ISig_ "DiagFaultStat_CCIOM_DtcIdB_ISig_4";
BA_ "GenSigSendType" SG_ 2147485138 DiagFaultStat_CCIOM_DtcIdA_ISig_ 1;
BA_ "NeedsUpdateBit" SG_ 2147485138 DiagFaultStat_CCIOM_DtcIdA_ISig_ 1;
BA_ "Platform_VMCU1_Sig" SG_ 2147485138 DiagFaultStat_CCIOM_DtcIdA_ISig_ 1;
BA_ "SystemSignalLongSymbol" SG_ 2147485138 DiagFaultStat_CCIOM_DtcIdA_ISig_ "DiagFaultStat_CCIOM_DtcIdA_ISig_4";
BA_ "GenSigSendType" SG_ 2147485138 DiagFaultStat_CCIOM_FailTB_ISig_ 1;
BA_ "NeedsUpdateBit" SG_ 2147485138 DiagFaultStat_CCIOM_FailTB_ISig_ 1;
BA_ "Platform_VMCU1_Sig" SG_ 2147485138 DiagFaultStat_CCIOM_FailTB_ISig_ 1;
BA_ "SystemSignalLongSymbol" SG_ 2147485138 DiagFaultStat_CCIOM_FailTB_ISig_ "DiagFaultStat_CCIOM_FailTB_ISig_4";
BA_ "GenSigSendType" SG_ 2147485142 DiagFaultStat_BPMU_EcuAdr_ISig_4 3;
BA_ "GenSigStartValue" SG_ 2147485142 DiagFaultStat_BPMU_EcuAdr_ISig_4 255;
BA_ "NeedsUpdateBit" SG_ 2147485142 DiagFaultStat_BPMU_EcuAdr_ISig_4 1;
BA_ "GenSigSendType" SG_ 2147485142 DiagFaultStat_BPMU_sg_UB_ISig_4 7;
BA_ "GenSigSendType" SG_ 2147485142 DiagFaultStat_BPMU_DtcIdB_ISig_4 3;
BA_ "NeedsUpdateBit" SG_ 2147485142 DiagFaultStat_BPMU_DtcIdB_ISig_4 1;
BA_ "GenSigSendType" SG_ 2147485142 DiagFaultStat_BPMU_FailTB_ISig_4 3;
BA_ "NeedsUpdateBit" SG_ 2147485142 DiagFaultStat_BPMU_FailTB_ISig_4 1;
BA_ "GenSigSendType" SG_ 2147485142 DiagFaultStat_BPMU_FailTA_ISig_4 3;
BA_ "NeedsUpdateBit" SG_ 2147485142 DiagFaultStat_BPMU_FailTA_ISig_4 1;
BA_ "GenSigSendType" SG_ 2147485142 DiagFaultStat_BPMU_DtcIdA_ISig_4 3;
BA_ "NeedsUpdateBit" SG_ 2147485142 DiagFaultStat_BPMU_DtcIdA_ISig_4 1;
BA_ "GenSigSendType" SG_ 2147485154 DiagFaultStat_BBM_EcuAdr_ISig_4 3;
BA_ "GenSigStartValue" SG_ 2147485154 DiagFaultStat_BBM_EcuAdr_ISig_4 255;
BA_ "NeedsUpdateBit" SG_ 2147485154 DiagFaultStat_BBM_EcuAdr_ISig_4 1;
BA_ "Platform_VMCU1_Sig" SG_ 2147485154 DiagFaultStat_BBM_EcuAdr_ISig_4 1;
BA_ "GenSigSendType" SG_ 2147485154 DiagFaultStat_BBM_DtcIdB_ISig_4 3;
BA_ "NeedsUpdateBit" SG_ 2147485154 DiagFaultStat_BBM_DtcIdB_ISig_4 1;
BA_ "Platform_VMCU1_Sig" SG_ 2147485154 DiagFaultStat_BBM_DtcIdB_ISig_4 1;
BA_ "GenSigSendType" SG_ 2147485154 DiagFaultStat_BBM_FailTB_ISig_4 3;
BA_ "NeedsUpdateBit" SG_ 2147485154 DiagFaultStat_BBM_FailTB_ISig_4 1;
BA_ "Platform_VMCU1_Sig" SG_ 2147485154 DiagFaultStat_BBM_FailTB_ISig_4 1;
BA_ "GenSigSendType" SG_ 2147485154 DiagFaultStat_BBM_sg_UB_ISig_4 7;
BA_ "Platform_VMCU1_Sig" SG_ 2147485154 DiagFaultStat_BBM_sg_UB_ISig_4 1;
BA_ "GenSigSendType" SG_ 2147485154 DiagFaultStat_BBM_DtcIdA_ISig_4 3;
BA_ "NeedsUpdateBit" SG_ 2147485154 DiagFaultStat_BBM_DtcIdA_ISig_4 1;
BA_ "Platform_VMCU1_Sig" SG_ 2147485154 DiagFaultStat_BBM_DtcIdA_ISig_4 1;
BA_ "GenSigSendType" SG_ 2147485154 DiagFaultStat_BBM_FailTA_ISig_4 3;
BA_ "NeedsUpdateBit" SG_ 2147485154 DiagFaultStat_BBM_FailTA_ISig_4 1;
BA_ "Platform_VMCU1_Sig" SG_ 2147485154 DiagFaultStat_BBM_FailTA_ISig_4 1;
BA_ "GenSigSendType" SG_ 2147485153 DiagFaultStat_BBIOM_sg_UB_ISig_4 7;
BA_ "GenSigMaxLatency" SG_ 2147485153 DiagFaultStat_BBIOM_sg_UB_ISig_4 1000;
BA_ "GenSigSendType" SG_ 2147485153 DiagFaultStat_BBIOM_FailTA_ISig_ 1;
BA_ "GenSigCycleTime" SG_ 2147485153 DiagFaultStat_BBIOM_FailTA_ISig_ 100;
BA_ "GenSigCycleTimeActive" SG_ 2147485153 DiagFaultStat_BBIOM_FailTA_ISig_ 100;
BA_ "GenSigMaxLatency" SG_ 2147485153 DiagFaultStat_BBIOM_FailTA_ISig_ 1000;
BA_ "NeedsUpdateBit" SG_ 2147485153 DiagFaultStat_BBIOM_FailTA_ISig_ 1;
BA_ "SystemSignalLongSymbol" SG_ 2147485153 DiagFaultStat_BBIOM_FailTA_ISig_ "DiagFaultStat_BBIOM_FailTA_ISig_4";
BA_ "GenSigSendType" SG_ 2147485153 DiagFaultStat_BBIOM_FailTB_ISig_ 1;
BA_ "GenSigCycleTime" SG_ 2147485153 DiagFaultStat_BBIOM_FailTB_ISig_ 100;
BA_ "GenSigCycleTimeActive" SG_ 2147485153 DiagFaultStat_BBIOM_FailTB_ISig_ 100;
BA_ "GenSigMaxLatency" SG_ 2147485153 DiagFaultStat_BBIOM_FailTB_ISig_ 1000;
BA_ "NeedsUpdateBit" SG_ 2147485153 DiagFaultStat_BBIOM_FailTB_ISig_ 1;
BA_ "SystemSignalLongSymbol" SG_ 2147485153 DiagFaultStat_BBIOM_FailTB_ISig_ "DiagFaultStat_BBIOM_FailTB_ISig_4";
BA_ "GenSigSendType" SG_ 2147485153 DiagFaultStat_BBIOM_DtcIdB_ISig_ 1;
BA_ "GenSigCycleTime" SG_ 2147485153 DiagFaultStat_BBIOM_DtcIdB_ISig_ 100;
BA_ "GenSigCycleTimeActive" SG_ 2147485153 DiagFaultStat_BBIOM_DtcIdB_ISig_ 100;
BA_ "GenSigMaxLatency" SG_ 2147485153 DiagFaultStat_BBIOM_DtcIdB_ISig_ 1000;
BA_ "NeedsUpdateBit" SG_ 2147485153 DiagFaultStat_BBIOM_DtcIdB_ISig_ 1;
BA_ "SystemSignalLongSymbol" SG_ 2147485153 DiagFaultStat_BBIOM_DtcIdB_ISig_ "DiagFaultStat_BBIOM_DtcIdB_ISig_4";
BA_ "GenSigSendType" SG_ 2147485153 DiagFaultStat_BBIOM_DtcIdA_ISig_ 1;
BA_ "GenSigCycleTime" SG_ 2147485153 DiagFaultStat_BBIOM_DtcIdA_ISig_ 100;
BA_ "GenSigCycleTimeActive" SG_ 2147485153 DiagFaultStat_BBIOM_DtcIdA_ISig_ 100;
BA_ "GenSigMaxLatency" SG_ 2147485153 DiagFaultStat_BBIOM_DtcIdA_ISig_ 1000;
BA_ "NeedsUpdateBit" SG_ 2147485153 DiagFaultStat_BBIOM_DtcIdA_ISig_ 1;
BA_ "SystemSignalLongSymbol" SG_ 2147485153 DiagFaultStat_BBIOM_DtcIdA_ISig_ "DiagFaultStat_BBIOM_DtcIdA_ISig_4";
BA_ "GenSigSendType" SG_ 2147485153 DiagFaultStat_BBIOM_EcuAdr_ISig_ 1;
BA_ "GenSigCycleTime" SG_ 2147485153 DiagFaultStat_BBIOM_EcuAdr_ISig_ 100;
BA_ "GenSigCycleTimeActive" SG_ 2147485153 DiagFaultStat_BBIOM_EcuAdr_ISig_ 100;
BA_ "GenSigStartValue" SG_ 2147485153 DiagFaultStat_BBIOM_EcuAdr_ISig_ 255;
BA_ "GenSigMaxLatency" SG_ 2147485153 DiagFaultStat_BBIOM_EcuAdr_ISig_ 1000;
BA_ "NeedsUpdateBit" SG_ 2147485153 DiagFaultStat_BBIOM_EcuAdr_ISig_ 1;
BA_ "SystemSignalLongSymbol" SG_ 2147485153 DiagFaultStat_BBIOM_EcuAdr_ISig_ "DiagFaultStat_BBIOM_EcuAdr_ISig_4";
BA_REL_ "GenSigFirstTimeoutTime" BU_SG_REL_ CIOM SG_ 2147485039 OilPrediction_Quality 36000;
BA_REL_ "GenSigTimeoutTime" BU_SG_REL_ CIOM SG_ 2147485039 OilPrediction_Quality 9000;
BA_REL_ "GenSigFirstTimeoutTime" BU_SG_REL_ VMCU SG_ 2147485039 OilPrediction_Quality 36000;
BA_REL_ "GenSigTimeoutTime" BU_SG_REL_ VMCU SG_ 2147485039 OilPrediction_Quality 9000;
BA_REL_ "GenSigFirstTimeoutTime" BU_SG_REL_ IC3 SG_ 2147485039 TimeLeftToVehSpdReduction_OBD 36000;
BA_REL_ "GenSigTimeoutTime" BU_SG_REL_ IC3 SG_ 2147485039 TimeLeftToVehSpdReduction_OBD 9000;
BA_REL_ "GenSigFirstTimeoutTime" BU_SG_REL_ CIOM SG_ 2147485039 OilPrediction_RemainDist 36000;
BA_REL_ "GenSigTimeoutTime" BU_SG_REL_ CIOM SG_ 2147485039 OilPrediction_RemainDist 9000;
BA_REL_ "GenSigFirstTimeoutTime" BU_SG_REL_ VMCU SG_ 2147485039 OilPrediction_RemainDist 36000;
BA_REL_ "GenSigTimeoutTime" BU_SG_REL_ VMCU SG_ 2147485039 OilPrediction_RemainDist 9000;
BA_REL_ "GenSigFirstTimeoutTime" BU_SG_REL_ IC3 SG_ 2147485039 TimeToCorrectOilLevel_ISig_4 36000;
BA_REL_ "GenSigTimeoutTime" BU_SG_REL_ IC3 SG_ 2147485039 TimeToCorrectOilLevel_ISig_4 9000;
BA_REL_ "GenSigFirstTimeoutTime" BU_SG_REL_ VMCU SG_ 2147485039 OilPrediction_RemainTime 36000;
BA_REL_ "GenSigTimeoutTime" BU_SG_REL_ VMCU SG_ 2147485039 OilPrediction_RemainTime 9000;
BA_REL_ "GenSigFirstTimeoutTime" BU_SG_REL_ CIOM SG_ 2147485039 OilPrediction_RemainTime 36000;
BA_REL_ "GenSigTimeoutTime" BU_SG_REL_ CIOM SG_ 2147485039 OilPrediction_RemainTime 9000;
BA_REL_ "GenSigFirstTimeoutTime" BU_SG_REL_ CIOM SG_ 2147485039 OilPrediction_Status 36000;
BA_REL_ "GenSigTimeoutTime" BU_SG_REL_ CIOM SG_ 2147485039 OilPrediction_Status 9000;
BA_REL_ "GenSigFirstTimeoutTime" BU_SG_REL_ VMCU SG_ 2147485039 OilPrediction_Status 36000;
BA_REL_ "GenSigTimeoutTime" BU_SG_REL_ VMCU SG_ 2147485039 OilPrediction_Status 9000;
BA_REL_ "GenSigFirstTimeoutTime" BU_SG_REL_ CIOM SG_ 2147484924 EngineCoolingFanSpeed_ISig_4 6000;
BA_REL_ "GenSigTimeoutTime" BU_SG_REL_ CIOM SG_ 2147484924 EngineCoolingFanSpeed_ISig_4 1500;
BA_REL_ "GenSigFirstTimeoutTime" BU_SG_REL_ VMCU SG_ 2147484924 DMSDriverFollow 6000;
BA_REL_ "GenSigTimeoutTime" BU_SG_REL_ VMCU SG_ 2147484924 DMSDriverFollow 1500;
BA_REL_ "GenSigFirstTimeoutTime" BU_SG_REL_ CIOM SG_ 2147484924 CoolantPumpEngagementStatus_ISig 6000;
BA_REL_ "GenSigTimeoutTime" BU_SG_REL_ CIOM SG_ 2147484924 CoolantPumpEngagementStatus_ISig 1500;
BA_REL_ "GenSigFirstTimeoutTime" BU_SG_REL_ IC3 SG_ 2147484924 AverageFuelEconomy_ISig_4 6000;
BA_REL_ "GenSigTimeoutTime" BU_SG_REL_ IC3 SG_ 2147484924 AverageFuelEconomy_ISig_4 1500;
BA_REL_ "GenSigFirstTimeoutTime" BU_SG_REL_ VMCU SG_ 2147484924 EngineGasRate 6000;
BA_REL_ "GenSigTimeoutTime" BU_SG_REL_ VMCU SG_ 2147484924 EngineGasRate 1500;
BA_REL_ "GenSigFirstTimeoutTime" BU_SG_REL_ CIOM SG_ 2147484924 EngineGasRate 6000;
BA_REL_ "GenSigTimeoutTime" BU_SG_REL_ CIOM SG_ 2147484924 EngineGasRate 1500;
BA_REL_ "GenSigFirstTimeoutTime" BU_SG_REL_ VMCU SG_ 2147484924 FuelEcoEngStatus 6000;
BA_REL_ "GenSigTimeoutTime" BU_SG_REL_ VMCU SG_ 2147484924 FuelEcoEngStatus 1500;
BA_REL_ "GenSigFirstTimeoutTime" BU_SG_REL_ IC3 SG_ 2147484939 DrainPrimingStatus 6000;
BA_REL_ "GenSigTimeoutTime" BU_SG_REL_ IC3 SG_ 2147484939 DrainPrimingStatus 1500;
BA_REL_ "GenSigFirstTimeoutTime" BU_SG_REL_ IC3 SG_ 2147484939 CoolantTempHigh_ISig_4 6000;
BA_REL_ "GenSigTimeoutTime" BU_SG_REL_ IC3 SG_ 2147484939 CoolantTempHigh_ISig_4 1500;
BA_REL_ "GenSigFirstTimeoutTime" BU_SG_REL_ VMCU SG_ 2147484939 CoolantTempHigh_ISig_4 6000;
BA_REL_ "GenSigTimeoutTime" BU_SG_REL_ VMCU SG_ 2147484939 CoolantTempHigh_ISig_4 1500;
BA_REL_ "GenSigFirstTimeoutTime" BU_SG_REL_ BBM SG_ 2147484939 CoolantTempHigh_ISig_4 6000;
BA_REL_ "GenSigTimeoutTime" BU_SG_REL_ BBM SG_ 2147484939 CoolantTempHigh_ISig_4 1500;
BA_REL_ "GenSigFirstTimeoutTime" BU_SG_REL_ VMCU SG_ 2147484939 CoolantLevelLow_ISig_4 6000;
BA_REL_ "GenSigTimeoutTime" BU_SG_REL_ VMCU SG_ 2147484939 CoolantLevelLow_ISig_4 1500;
BA_REL_ "GenSigFirstTimeoutTime" BU_SG_REL_ BBM SG_ 2147484939 CoolantLevelLow_ISig_4 6000;
BA_REL_ "GenSigTimeoutTime" BU_SG_REL_ BBM SG_ 2147484939 CoolantLevelLow_ISig_4 1500;
BA_REL_ "GenSigFirstTimeoutTime" BU_SG_REL_ IC3 SG_ 2147484939 CoolantLevelLow_ISig_4 6000;
BA_REL_ "GenSigTimeoutTime" BU_SG_REL_ IC3 SG_ 2147484939 CoolantLevelLow_ISig_4 1500;
BA_REL_ "GenSigFirstTimeoutTime" BU_SG_REL_ IC3 SG_ 2147484939 AutoWheelBrakesStatus 6000;
BA_REL_ "GenSigTimeoutTime" BU_SG_REL_ IC3 SG_ 2147484939 AutoWheelBrakesStatus 1500;
BA_REL_ "GenSigFirstTimeoutTime" BU_SG_REL_ TECU SG_ 2147484939 AutoWheelBrakesStatus 6000;
BA_REL_ "GenSigTimeoutTime" BU_SG_REL_ TECU SG_ 2147484939 AutoWheelBrakesStatus 1500;
BA_REL_ "GenSigFirstTimeoutTime" BU_SG_REL_ VMCU SG_ 2147484939 OilPressureLow_ISig_4 6000;
BA_REL_ "GenSigTimeoutTime" BU_SG_REL_ VMCU SG_ 2147484939 OilPressureLow_ISig_4 1500;
BA_REL_ "GenSigFirstTimeoutTime" BU_SG_REL_ IC3 SG_ 2147484939 OilPressureLow_ISig_4 6000;
BA_REL_ "GenSigTimeoutTime" BU_SG_REL_ IC3 SG_ 2147484939 OilPressureLow_ISig_4 1500;
BA_REL_ "GenSigFirstTimeoutTime" BU_SG_REL_ BBM SG_ 2147484939 OilPressureLow_ISig_4 6000;
BA_REL_ "GenSigTimeoutTime" BU_SG_REL_ BBM SG_ 2147484939 OilPressureLow_ISig_4 1500;
BA_REL_ "GenSigFirstTimeoutTime" BU_SG_REL_ IC3 SG_ 2147484939 EngineTotalFuelConsumed_ISig_4 6000;
BA_REL_ "GenSigTimeoutTime" BU_SG_REL_ IC3 SG_ 2147484939 EngineTotalFuelConsumed_ISig_4 1500;
BA_REL_ "GenSigFirstTimeoutTime" BU_SG_REL_ BBM SG_ 2147484939 EngineTotalFuelConsumed_ISig_4 6000;
BA_REL_ "GenSigTimeoutTime" BU_SG_REL_ BBM SG_ 2147484939 EngineTotalFuelConsumed_ISig_4 1500;
BA_REL_ "GenSigFirstTimeoutTime" BU_SG_REL_ CIOM SG_ 2147484939 EngineTotalFuelConsumed_ISig_4 6000;
BA_REL_ "GenSigTimeoutTime" BU_SG_REL_ CIOM SG_ 2147484939 EngineTotalFuelConsumed_ISig_4 1500;
BA_REL_ "GenSigFirstTimeoutTime" BU_SG_REL_ VMCU SG_ 2147484939 EngineTotalFuelConsumed_ISig_4 6000;
BA_REL_ "GenSigTimeoutTime" BU_SG_REL_ VMCU SG_ 2147484939 EngineTotalFuelConsumed_ISig_4 1500;
BA_REL_ "GenSigFirstTimeoutTime" BU_SG_REL_ TECU SG_ 2147484939 EngineTotalFuelConsumed_ISig_4 3000;
BA_REL_ "GenSigTimeoutTime" BU_SG_REL_ TECU SG_ 2147484939 EngineTotalFuelConsumed_ISig_4 1500;
BA_REL_ "GenSigFirstTimeoutTime" BU_SG_REL_ IC3 SG_ 2147484939 TopGearMode_ISig_4 6000;
BA_REL_ "GenSigTimeoutTime" BU_SG_REL_ IC3 SG_ 2147484939 TopGearMode_ISig_4 1500;
BA_REL_ "GenSigFirstTimeoutTime" BU_SG_REL_ IC3 SG_ 2147484939 OilLevelLow_ISig_4 6000;
BA_REL_ "GenSigTimeoutTime" BU_SG_REL_ IC3 SG_ 2147484939 OilLevelLow_ISig_4 1500;
BA_REL_ "GenSigFirstTimeoutTime" BU_SG_REL_ BBM SG_ 2147484939 OilLevelLow_ISig_4 6000;
BA_REL_ "GenSigTimeoutTime" BU_SG_REL_ BBM SG_ 2147484939 OilLevelLow_ISig_4 1500;
BA_REL_ "GenSigFirstTimeoutTime" BU_SG_REL_ TECU SG_ 2147484939 BarometricPressure_ISig_4 6000;
BA_REL_ "GenSigTimeoutTime" BU_SG_REL_ TECU SG_ 2147484939 BarometricPressure_ISig_4 1500;
BA_REL_ "GenSigFirstTimeoutTime" BU_SG_REL_ BBM SG_ 2147484939 BarometricPressure_ISig_4 6000;
BA_REL_ "GenSigTimeoutTime" BU_SG_REL_ BBM SG_ 2147484939 BarometricPressure_ISig_4 1500;
BA_REL_ "GenSigFirstTimeoutTime" BU_SG_REL_ VMCU SG_ 2147484939 BarometricPressure_ISig_4 6000;
BA_REL_ "GenSigTimeoutTime" BU_SG_REL_ VMCU SG_ 2147484939 BarometricPressure_ISig_4 1500;
BA_REL_ "GenSigFirstTimeoutTime" BU_SG_REL_ IC3 SG_ 2147484939 InletAirHeaterStatus1 6000;
BA_REL_ "GenSigTimeoutTime" BU_SG_REL_ IC3 SG_ 2147484939 InletAirHeaterStatus1 1500;
BA_REL_ "GenSigFirstTimeoutTime" BU_SG_REL_ IC3 SG_ 2147484927 FuelFilterClogged 6000;
BA_REL_ "GenSigTimeoutTime" BU_SG_REL_ IC3 SG_ 2147484927 FuelFilterClogged 1500;
BA_REL_ "GenSigFirstTimeoutTime" BU_SG_REL_ VMCU SG_ 2147484927 EngineAirInletTemperature 6000;
BA_REL_ "GenSigTimeoutTime" BU_SG_REL_ VMCU SG_ 2147484927 EngineAirInletTemperature 1500;
BA_REL_ "GenSigFirstTimeoutTime" BU_SG_REL_ IC3 SG_ 2147484927 StarterMotorRecoveryTime 6000;
BA_REL_ "GenSigTimeoutTime" BU_SG_REL_ IC3 SG_ 2147484927 StarterMotorRecoveryTime 1500;
BA_REL_ "GenSigFirstTimeoutTime" BU_SG_REL_ IC3 SG_ 2147484927 EngineFanOverspeed 6000;
BA_REL_ "GenSigTimeoutTime" BU_SG_REL_ IC3 SG_ 2147484927 EngineFanOverspeed 1500;
BA_REL_ "GenSigFirstTimeoutTime" BU_SG_REL_ VMCU SG_ 2147484927 AppliedVehicleSpeedLimit 6000;
BA_REL_ "GenSigTimeoutTime" BU_SG_REL_ VMCU SG_ 2147484927 AppliedVehicleSpeedLimit 1500;
BA_REL_ "GenSigFirstTimeoutTime" BU_SG_REL_ TECU SG_ 2147484927 AppliedVehicleSpeedLimit 6000;
BA_REL_ "GenSigTimeoutTime" BU_SG_REL_ TECU SG_ 2147484927 AppliedVehicleSpeedLimit 1500;
BA_REL_ "GenSigFirstTimeoutTime" BU_SG_REL_ VMCU SG_ 2147484927 EngineProtDerateStat 6000;
BA_REL_ "GenSigTimeoutTime" BU_SG_REL_ VMCU SG_ 2147484927 EngineProtDerateStat 1500;
BA_REL_ "GenSigFirstTimeoutTime" BU_SG_REL_ IC3 SG_ 2147484927 CoolantTempGaugeAdjustment 6000;
BA_REL_ "GenSigTimeoutTime" BU_SG_REL_ IC3 SG_ 2147484927 CoolantTempGaugeAdjustment 1500;
BA_REL_ "GenSigFirstTimeoutTime" BU_SG_REL_ VMCU SG_ 2147484927 AirFilterPressureDrop 6000;
BA_REL_ "GenSigTimeoutTime" BU_SG_REL_ VMCU SG_ 2147484927 AirFilterPressureDrop 1500;
BA_REL_ "GenSigFirstTimeoutTime" BU_SG_REL_ VMCU SG_ 2147484381 AirFilter_AirMassFlowValidated 3000;
BA_REL_ "GenSigTimeoutTime" BU_SG_REL_ VMCU SG_ 2147484381 AirFilter_AirMassFlowValidated 270;
BA_REL_ "GenSigFirstTimeoutTime" BU_SG_REL_ IC3 SG_ 2147484381 DPF_LimitedSpeedDuetoInhibit 3000;
BA_REL_ "GenSigTimeoutTime" BU_SG_REL_ IC3 SG_ 2147484381 DPF_LimitedSpeedDuetoInhibit 270;
BA_REL_ "GenSigFirstTimeoutTime" BU_SG_REL_ DACU SG_ 2147484381 XARSystemState 3000;
BA_REL_ "GenSigTimeoutTime" BU_SG_REL_ DACU SG_ 2147484381 XARSystemState 270;
BA_REL_ "GenSigFirstTimeoutTime" BU_SG_REL_ DACU SG_ 2147484381 XARActiveControlMode 3000;
BA_REL_ "GenSigTimeoutTime" BU_SG_REL_ DACU SG_ 2147484381 XARActiveControlMode 270;
BA_REL_ "GenSigFirstTimeoutTime" BU_SG_REL_ VMCU SG_ 2147484381 AirFilter_Pressure 3000;
BA_REL_ "GenSigTimeoutTime" BU_SG_REL_ VMCU SG_ 2147484381 AirFilter_Pressure 270;
BA_REL_ "GenSigFirstTimeoutTime" BU_SG_REL_ VMCU SG_ 2147484381 CCBSetSpeedApplied 3000;
BA_REL_ "GenSigTimeoutTime" BU_SG_REL_ VMCU SG_ 2147484381 CCBSetSpeedApplied 270;
BA_REL_ "GenSigFirstTimeoutTime" BU_SG_REL_ DACU SG_ 2147484381 CCBSetSpeedApplied 3000;
BA_REL_ "GenSigTimeoutTime" BU_SG_REL_ DACU SG_ 2147484381 CCBSetSpeedApplied 270;
BA_REL_ "GenSigFirstTimeoutTime" BU_SG_REL_ VMCU SG_ 2147484367 CCControllerMode_ISig_4 3000;
BA_REL_ "GenSigTimeoutTime" BU_SG_REL_ VMCU SG_ 2147484367 CCControllerMode_ISig_4 270;
BA_REL_ "GenSigFirstTimeoutTime" BU_SG_REL_ IC3 SG_ 2147484367 CCControllerMode_ISig_4 3000;
BA_REL_ "GenSigTimeoutTime" BU_SG_REL_ IC3 SG_ 2147484367 CCControllerMode_ISig_4 270;
BA_REL_ "GenSigFirstTimeoutTime" BU_SG_REL_ BBM SG_ 2147484367 CrankcasePressureHigh_ISig_4 3000;
BA_REL_ "GenSigTimeoutTime" BU_SG_REL_ BBM SG_ 2147484367 CrankcasePressureHigh_ISig_4 270;
BA_REL_ "GenSigFirstTimeoutTime" BU_SG_REL_ VMCU SG_ 2147484367 EngineSystemPowerDownAck 3000;
BA_REL_ "GenSigTimeoutTime" BU_SG_REL_ VMCU SG_ 2147484367 EngineSystemPowerDownAck 270;
BA_REL_ "GenSigFirstTimeoutTime" BU_SG_REL_ TECU SG_ 2147484367 EngineActiveStatus_ISig_4 3000;
BA_REL_ "GenSigTimeoutTime" BU_SG_REL_ TECU SG_ 2147484367 EngineActiveStatus_ISig_4 300;
BA_REL_ "GenSigFirstTimeoutTime" BU_SG_REL_ VMCU SG_ 2147484367 EngineActiveStatus_ISig_4 3000;
BA_REL_ "GenSigTimeoutTime" BU_SG_REL_ VMCU SG_ 2147484367 EngineActiveStatus_ISig_4 270;
BA_REL_ "GenSigFirstTimeoutTime" BU_SG_REL_ VMCU SG_ 2147484367 XRSLControllerMode 3000;
BA_REL_ "GenSigTimeoutTime" BU_SG_REL_ VMCU SG_ 2147484367 XRSLControllerMode 270;
BA_REL_ "GenSigFirstTimeoutTime" BU_SG_REL_ IC3 SG_ 2147484367 XRSLControllerMode 3000;
BA_REL_ "GenSigTimeoutTime" BU_SG_REL_ IC3 SG_ 2147484367 XRSLControllerMode 270;
BA_REL_ "GenSigFirstTimeoutTime" BU_SG_REL_ IC3 SG_ 2147484367 RegenInhibDueHeight 3000;
BA_REL_ "GenSigTimeoutTime" BU_SG_REL_ IC3 SG_ 2147484367 RegenInhibDueHeight 270;
BA_REL_ "GenSigFirstTimeoutTime" BU_SG_REL_ VMCU SG_ 2147484367 ExhManif_AirInjActive_ISig_4 3000;
BA_REL_ "GenSigTimeoutTime" BU_SG_REL_ VMCU SG_ 2147484367 ExhManif_AirInjActive_ISig_4 270;
BA_REL_ "GenSigFirstTimeoutTime" BU_SG_REL_ VMCU SG_ 2147484367 CCBControllerMode 3000;
BA_REL_ "GenSigTimeoutTime" BU_SG_REL_ VMCU SG_ 2147484367 CCBControllerMode 270;
BA_REL_ "GenSigFirstTimeoutTime" BU_SG_REL_ VMCU SG_ 2147484367 InhibitIdleShutdownStatus 3000;
BA_REL_ "GenSigTimeoutTime" BU_SG_REL_ VMCU SG_ 2147484367 InhibitIdleShutdownStatus 270;
BA_REL_ "GenSigFirstTimeoutTime" BU_SG_REL_ VMCU SG_ 2147484367 EngCompartmentStopSwitchStat 3000;
BA_REL_ "GenSigTimeoutTime" BU_SG_REL_ VMCU SG_ 2147484367 EngCompartmentStopSwitchStat 270;
BA_REL_ "GenSigFirstTimeoutTime" BU_SG_REL_ VMCU SG_ 2147484367 EngineAirInletPressure 3000;
BA_REL_ "GenSigTimeoutTime" BU_SG_REL_ VMCU SG_ 2147484367 EngineAirInletPressure 270;
BA_REL_ "GenSigFirstTimeoutTime" BU_SG_REL_ CIOM SG_ 2147484367 EngineStartAuth_rqst 3000;
BA_REL_ "GenSigTimeoutTime" BU_SG_REL_ CIOM SG_ 2147484367 EngineStartAuth_rqst 270;
BA_REL_ "GenSigFirstTimeoutTime" BU_SG_REL_ VMCU SG_ 2147484367 IntakeAirTemperatureAlert 3000;
BA_REL_ "GenSigTimeoutTime" BU_SG_REL_ VMCU SG_ 2147484367 IntakeAirTemperatureAlert 270;
BA_REL_ "GenSigFirstTimeoutTime" BU_SG_REL_ BBM SG_ 2147484367 EngineOilTempHigh_ISig_4 3000;
BA_REL_ "GenSigTimeoutTime" BU_SG_REL_ BBM SG_ 2147484367 EngineOilTempHigh_ISig_4 270;
BA_REL_ "GenSigFirstTimeoutTime" BU_SG_REL_ IC3 SG_ 2147484367 EngineOilTempHigh_ISig_4 3000;
BA_REL_ "GenSigTimeoutTime" BU_SG_REL_ IC3 SG_ 2147484367 EngineOilTempHigh_ISig_4 270;
BA_REL_ "GenSigFirstTimeoutTime" BU_SG_REL_ VMCU SG_ 2147484367 WarmUpCycle 3000;
BA_REL_ "GenSigTimeoutTime" BU_SG_REL_ VMCU SG_ 2147484367 WarmUpCycle 270;
BA_REL_ "GenSigFirstTimeoutTime" BU_SG_REL_ VMCU SG_ 2147484367 DeterminedGear 3000;
BA_REL_ "GenSigTimeoutTime" BU_SG_REL_ VMCU SG_ 2147484367 DeterminedGear 270;
BA_REL_ "GenSigFirstTimeoutTime" BU_SG_REL_ IC3 SG_ 2147484367 CCSetSpeedApplied_ISig_4 3000;
BA_REL_ "GenSigTimeoutTime" BU_SG_REL_ IC3 SG_ 2147484367 CCSetSpeedApplied_ISig_4 270;
BA_REL_ "GenSigFirstTimeoutTime" BU_SG_REL_ DACU SG_ 2147484367 CCSetSpeedApplied_ISig_4 3000;
BA_REL_ "GenSigTimeoutTime" BU_SG_REL_ DACU SG_ 2147484367 CCSetSpeedApplied_ISig_4 270;
BA_REL_ "GenSigFirstTimeoutTime" BU_SG_REL_ VMCU SG_ 2147484367 CCSetSpeedApplied_ISig_4 3000;
BA_REL_ "GenSigTimeoutTime" BU_SG_REL_ VMCU SG_ 2147484367 CCSetSpeedApplied_ISig_4 270;
BA_REL_ "GenSigFirstTimeoutTime" BU_SG_REL_ IC3 SG_ 2147485168 DiagFaultStat_WRCS_EcuAdr_ISig_4 24000;
BA_REL_ "GenSigTimeoutTime" BU_SG_REL_ IC3 SG_ 2147485168 DiagFaultStat_WRCS_EcuAdr_ISig_4 6000;
BA_REL_ "GenSigFirstTimeoutTime" BU_SG_REL_ IC3 SG_ 2147485168 DiagFaultStat_WRCS_DtcIdB_ISig_4 24000;
BA_REL_ "GenSigTimeoutTime" BU_SG_REL_ IC3 SG_ 2147485168 DiagFaultStat_WRCS_DtcIdB_ISig_4 6000;
BA_REL_ "GenSigFirstTimeoutTime" BU_SG_REL_ IC3 SG_ 2147485168 DiagFaultStat_WRCS_FailTB_ISig_4 24000;
BA_REL_ "GenSigTimeoutTime" BU_SG_REL_ IC3 SG_ 2147485168 DiagFaultStat_WRCS_FailTB_ISig_4 6000;
BA_REL_ "GenSigFirstTimeoutTime" BU_SG_REL_ IC3 SG_ 2147485168 DiagFaultStat_WRCS_FailTA_ISig_4 24000;
BA_REL_ "GenSigTimeoutTime" BU_SG_REL_ IC3 SG_ 2147485168 DiagFaultStat_WRCS_FailTA_ISig_4 6000;
BA_REL_ "GenSigFirstTimeoutTime" BU_SG_REL_ IC3 SG_ 2147485168 DiagFaultStat_WRCS_DtcIdA_ISig_4 24000;
BA_REL_ "GenSigTimeoutTime" BU_SG_REL_ IC3 SG_ 2147485168 DiagFaultStat_WRCS_DtcIdA_ISig_4 6000;
BA_REL_ "GenSigFirstTimeoutTime" BU_SG_REL_ IC3 SG_ 2147485136 DiagFaultStat_VMCU_DtcIdA_ISig_4 24000;
BA_REL_ "GenSigTimeoutTime" BU_SG_REL_ IC3 SG_ 2147485136 DiagFaultStat_VMCU_DtcIdA_ISig_4 6000;
BA_REL_ "GenSigFirstTimeoutTime" BU_SG_REL_ IC3 SG_ 2147485136 DiagFaultStat_VMCU_EcuAdr_ISig_4 24000;
BA_REL_ "GenSigTimeoutTime" BU_SG_REL_ IC3 SG_ 2147485136 DiagFaultStat_VMCU_EcuAdr_ISig_4 6000;
BA_REL_ "GenSigFirstTimeoutTime" BU_SG_REL_ IC3 SG_ 2147485136 DiagFaultStat_VMCU_FailTA_ISig_4 24000;
BA_REL_ "GenSigTimeoutTime" BU_SG_REL_ IC3 SG_ 2147485136 DiagFaultStat_VMCU_FailTA_ISig_4 6000;
BA_REL_ "GenSigFirstTimeoutTime" BU_SG_REL_ IC3 SG_ 2147485136 DiagFaultStat_VMCU_FailTB_ISig_4 24000;
BA_REL_ "GenSigTimeoutTime" BU_SG_REL_ IC3 SG_ 2147485136 DiagFaultStat_VMCU_FailTB_ISig_4 6000;
BA_REL_ "GenSigFirstTimeoutTime" BU_SG_REL_ IC3 SG_ 2147485136 DiagFaultStat_VMCU_DtcIdB_ISig_4 24000;
BA_REL_ "GenSigTimeoutTime" BU_SG_REL_ IC3 SG_ 2147485136 DiagFaultStat_VMCU_DtcIdB_ISig_4 6000;
BA_REL_ "GenSigFirstTimeoutTime" BU_SG_REL_ IC3 SG_ 2147485150 DiagFaultStat_TPM_EcuAdr_ISig_4 24000;
BA_REL_ "GenSigTimeoutTime" BU_SG_REL_ IC3 SG_ 2147485150 DiagFaultStat_TPM_EcuAdr_ISig_4 6000;
BA_REL_ "GenSigFirstTimeoutTime" BU_SG_REL_ IC3 SG_ 2147485150 DiagFaultStat_TPM_FailTB_ISig_4 24000;
BA_REL_ "GenSigTimeoutTime" BU_SG_REL_ IC3 SG_ 2147485150 DiagFaultStat_TPM_FailTB_ISig_4 6000;
BA_REL_ "GenSigFirstTimeoutTime" BU_SG_REL_ IC3 SG_ 2147485150 DiagFaultStat_TPM_DtcIdA_ISig_4 24000;
BA_REL_ "GenSigTimeoutTime" BU_SG_REL_ IC3 SG_ 2147485150 DiagFaultStat_TPM_DtcIdA_ISig_4 6000;
BA_REL_ "GenSigFirstTimeoutTime" BU_SG_REL_ IC3 SG_ 2147485150 DiagFaultStat_TPM_DtcIdB_ISig_4 24000;
BA_REL_ "GenSigTimeoutTime" BU_SG_REL_ IC3 SG_ 2147485150 DiagFaultStat_TPM_DtcIdB_ISig_4 6000;
BA_REL_ "GenSigFirstTimeoutTime" BU_SG_REL_ IC3 SG_ 2147485150 DiagFaultStat_TPM_FailTA_ISig_4 24000;
BA_REL_ "GenSigTimeoutTime" BU_SG_REL_ IC3 SG_ 2147485150 DiagFaultStat_TPM_FailTA_ISig_4 6000;
BA_REL_ "GenSigFirstTimeoutTime" BU_SG_REL_ IC3 SG_ 2147485167 DiagFaultStat_TECU_FailTA_ISig_4 24000;
BA_REL_ "GenSigTimeoutTime" BU_SG_REL_ IC3 SG_ 2147485167 DiagFaultStat_TECU_FailTA_ISig_4 6000;
BA_REL_ "GenSigFirstTimeoutTime" BU_SG_REL_ IC3 SG_ 2147485167 DiagFaultStat_TECU_FailTB_ISig_4 24000;
BA_REL_ "GenSigTimeoutTime" BU_SG_REL_ IC3 SG_ 2147485167 DiagFaultStat_TECU_FailTB_ISig_4 6000;
BA_REL_ "GenSigFirstTimeoutTime" BU_SG_REL_ IC3 SG_ 2147485167 DiagFaultStat_TECU_DtcIdA_ISig_4 24000;
BA_REL_ "GenSigTimeoutTime" BU_SG_REL_ IC3 SG_ 2147485167 DiagFaultStat_TECU_DtcIdA_ISig_4 6000;
BA_REL_ "GenSigFirstTimeoutTime" BU_SG_REL_ IC3 SG_ 2147485167 DiagFaultStat_TECU_EcuAdr_ISig_4 24000;
BA_REL_ "GenSigTimeoutTime" BU_SG_REL_ IC3 SG_ 2147485167 DiagFaultStat_TECU_EcuAdr_ISig_4 6000;
BA_REL_ "GenSigFirstTimeoutTime" BU_SG_REL_ IC3 SG_ 2147485167 DiagFaultStat_TECU_DtcIdB_ISig_4 24000;
BA_REL_ "GenSigTimeoutTime" BU_SG_REL_ IC3 SG_ 2147485167 DiagFaultStat_TECU_DtcIdB_ISig_4 6000;
BA_REL_ "GenSigFirstTimeoutTime" BU_SG_REL_ IC3 SG_ 2147485165 DiagFaultStat_SRS_DtcIdB_ISig_4 24000;
BA_REL_ "GenSigTimeoutTime" BU_SG_REL_ IC3 SG_ 2147485165 DiagFaultStat_SRS_DtcIdB_ISig_4 6000;
BA_REL_ "GenSigFirstTimeoutTime" BU_SG_REL_ IC3 SG_ 2147485165 DiagFaultStat_SRS_FailTB_ISig_4 24000;
BA_REL_ "GenSigTimeoutTime" BU_SG_REL_ IC3 SG_ 2147485165 DiagFaultStat_SRS_FailTB_ISig_4 6000;
BA_REL_ "GenSigFirstTimeoutTime" BU_SG_REL_ IC3 SG_ 2147485165 DiagFaultStat_SRS_EcuAdr_ISig_4 24000;
BA_REL_ "GenSigTimeoutTime" BU_SG_REL_ IC3 SG_ 2147485165 DiagFaultStat_SRS_EcuAdr_ISig_4 6000;
BA_REL_ "GenSigFirstTimeoutTime" BU_SG_REL_ IC3 SG_ 2147485165 DiagFaultStat_SRS_DtcIdA_ISig_4 24000;
BA_REL_ "GenSigTimeoutTime" BU_SG_REL_ IC3 SG_ 2147485165 DiagFaultStat_SRS_DtcIdA_ISig_4 6000;
BA_REL_ "GenSigFirstTimeoutTime" BU_SG_REL_ IC3 SG_ 2147485165 DiagFaultStat_SRS_FailTA_ISig_4 24000;
BA_REL_ "GenSigTimeoutTime" BU_SG_REL_ IC3 SG_ 2147485165 DiagFaultStat_SRS_FailTA_ISig_4 6000;
BA_REL_ "GenSigFirstTimeoutTime" BU_SG_REL_ IC3 SG_ 2147485164 DiagFaultStat_RCIOM_FailTA_ISig_ 24000;
BA_REL_ "GenSigTimeoutTime" BU_SG_REL_ IC3 SG_ 2147485164 DiagFaultStat_RCIOM_FailTA_ISig_ 6000;
BA_REL_ "GenSigFirstTimeoutTime" BU_SG_REL_ IC3 SG_ 2147485164 DiagFaultStat_RCIOM_FailTB_ISig_ 24000;
BA_REL_ "GenSigTimeoutTime" BU_SG_REL_ IC3 SG_ 2147485164 DiagFaultStat_RCIOM_FailTB_ISig_ 6000;
BA_REL_ "GenSigFirstTimeoutTime" BU_SG_REL_ IC3 SG_ 2147485164 DiagFaultStat_RCIOM_DtcIdB_ISig_ 24000;
BA_REL_ "GenSigTimeoutTime" BU_SG_REL_ IC3 SG_ 2147485164 DiagFaultStat_RCIOM_DtcIdB_ISig_ 6000;
BA_REL_ "GenSigFirstTimeoutTime" BU_SG_REL_ IC3 SG_ 2147485164 DiagFaultStat_RCIOM_DtcIdA_ISig_ 24000;
BA_REL_ "GenSigTimeoutTime" BU_SG_REL_ IC3 SG_ 2147485164 DiagFaultStat_RCIOM_DtcIdA_ISig_ 6000;
BA_REL_ "GenSigFirstTimeoutTime" BU_SG_REL_ IC3 SG_ 2147485164 DiagFaultStat_RCIOM_EcuAdr_ISig_ 24000;
BA_REL_ "GenSigTimeoutTime" BU_SG_REL_ IC3 SG_ 2147485164 DiagFaultStat_RCIOM_EcuAdr_ISig_ 6000;
BA_REL_ "GenSigFirstTimeoutTime" BU_SG_REL_ IC3 SG_ 2147485163 DiagFaultStat_PDM_EcuAdr_ISig_4 24000;
BA_REL_ "GenSigTimeoutTime" BU_SG_REL_ IC3 SG_ 2147485163 DiagFaultStat_PDM_EcuAdr_ISig_4 6000;
BA_REL_ "GenSigFirstTimeoutTime" BU_SG_REL_ IC3 SG_ 2147485163 DiagFaultStat_PDM_DtcIdB_ISig_4 24000;
BA_REL_ "GenSigTimeoutTime" BU_SG_REL_ IC3 SG_ 2147485163 DiagFaultStat_PDM_DtcIdB_ISig_4 6000;
BA_REL_ "GenSigFirstTimeoutTime" BU_SG_REL_ IC3 SG_ 2147485163 DiagFaultStat_PDM_FailTB_ISig_4 24000;
BA_REL_ "GenSigTimeoutTime" BU_SG_REL_ IC3 SG_ 2147485163 DiagFaultStat_PDM_FailTB_ISig_4 6000;
BA_REL_ "GenSigFirstTimeoutTime" BU_SG_REL_ IC3 SG_ 2147485163 DiagFaultStat_PDM_DtcIdA_ISig_4 24000;
BA_REL_ "GenSigTimeoutTime" BU_SG_REL_ IC3 SG_ 2147485163 DiagFaultStat_PDM_DtcIdA_ISig_4 6000;
BA_REL_ "GenSigFirstTimeoutTime" BU_SG_REL_ IC3 SG_ 2147485163 DiagFaultStat_PDM_FailTA_ISig_4 24000;
BA_REL_ "GenSigTimeoutTime" BU_SG_REL_ IC3 SG_ 2147485163 DiagFaultStat_PDM_FailTA_ISig_4 6000;
BA_REL_ "GenSigFirstTimeoutTime" BU_SG_REL_ IC3 SG_ 2147485162 DiagFaultStat_LPOS_DtcIdB_ISig_4 24000;
BA_REL_ "GenSigTimeoutTime" BU_SG_REL_ IC3 SG_ 2147485162 DiagFaultStat_LPOS_DtcIdB_ISig_4 6000;
BA_REL_ "GenSigFirstTimeoutTime" BU_SG_REL_ IC3 SG_ 2147485162 DiagFaultStat_LPOS_FailTB_ISig_4 24000;
BA_REL_ "GenSigTimeoutTime" BU_SG_REL_ IC3 SG_ 2147485162 DiagFaultStat_LPOS_FailTB_ISig_4 6000;
BA_REL_ "GenSigFirstTimeoutTime" BU_SG_REL_ IC3 SG_ 2147485162 DiagFaultStat_LPOS_DtcIdA_ISig_4 24000;
BA_REL_ "GenSigTimeoutTime" BU_SG_REL_ IC3 SG_ 2147485162 DiagFaultStat_LPOS_DtcIdA_ISig_4 6000;
BA_REL_ "GenSigFirstTimeoutTime" BU_SG_REL_ IC3 SG_ 2147485162 DiagFaultStat_LPOS_FailTA_ISig_4 24000;
BA_REL_ "GenSigTimeoutTime" BU_SG_REL_ IC3 SG_ 2147485162 DiagFaultStat_LPOS_FailTA_ISig_4 6000;
BA_REL_ "GenSigFirstTimeoutTime" BU_SG_REL_ IC3 SG_ 2147485162 DiagFaultStat_LPOS_EcuAdr_ISig_4 24000;
BA_REL_ "GenSigTimeoutTime" BU_SG_REL_ IC3 SG_ 2147485162 DiagFaultStat_LPOS_EcuAdr_ISig_4 6000;
BA_REL_ "GenSigFirstTimeoutTime" BU_SG_REL_ IC3 SG_ 2147485161 DiagFaultStat_LECM_EcuAdr_ISig_4 24000;
BA_REL_ "GenSigTimeoutTime" BU_SG_REL_ IC3 SG_ 2147485161 DiagFaultStat_LECM_EcuAdr_ISig_4 6000;
BA_REL_ "GenSigFirstTimeoutTime" BU_SG_REL_ IC3 SG_ 2147485161 DiagFaultStat_LECM_FailTB_ISig_4 24000;
BA_REL_ "GenSigTimeoutTime" BU_SG_REL_ IC3 SG_ 2147485161 DiagFaultStat_LECM_FailTB_ISig_4 6000;
BA_REL_ "GenSigFirstTimeoutTime" BU_SG_REL_ IC3 SG_ 2147485161 DiagFaultStat_LECM_FailTA_ISig_4 24000;
BA_REL_ "GenSigTimeoutTime" BU_SG_REL_ IC3 SG_ 2147485161 DiagFaultStat_LECM_FailTA_ISig_4 6000;
BA_REL_ "GenSigFirstTimeoutTime" BU_SG_REL_ IC3 SG_ 2147485161 DiagFaultStat_LECM_DtcIdB_ISig_4 24000;
BA_REL_ "GenSigTimeoutTime" BU_SG_REL_ IC3 SG_ 2147485161 DiagFaultStat_LECM_DtcIdB_ISig_4 6000;
BA_REL_ "GenSigFirstTimeoutTime" BU_SG_REL_ IC3 SG_ 2147485161 DiagFaultStat_LECM_DtcIdA_ISig_4 24000;
BA_REL_ "GenSigTimeoutTime" BU_SG_REL_ IC3 SG_ 2147485161 DiagFaultStat_LECM_DtcIdA_ISig_4 6000;
BA_REL_ "GenSigFirstTimeoutTime" BU_SG_REL_ IC3 SG_ 2147485145 DiagFaultStat_GFHCM2_DtcIdB_ISig 24000;
BA_REL_ "GenSigTimeoutTime" BU_SG_REL_ IC3 SG_ 2147485145 DiagFaultStat_GFHCM2_DtcIdB_ISig 6000;
BA_REL_ "GenSigFirstTimeoutTime" BU_SG_REL_ IC3 SG_ 2147485145 DiagFaultStat_GFHCM2_DtcIdA_ISig 24000;
BA_REL_ "GenSigTimeoutTime" BU_SG_REL_ IC3 SG_ 2147485145 DiagFaultStat_GFHCM2_DtcIdA_ISig 6000;
BA_REL_ "GenSigFirstTimeoutTime" BU_SG_REL_ IC3 SG_ 2147485145 DiagFaultStat_GFHCM2_FailTA_ISig 24000;
BA_REL_ "GenSigTimeoutTime" BU_SG_REL_ IC3 SG_ 2147485145 DiagFaultStat_GFHCM2_FailTA_ISig 6000;
BA_REL_ "GenSigFirstTimeoutTime" BU_SG_REL_ IC3 SG_ 2147485145 DiagFaultStat_GFHCM2_EcuAdr_ISig 24000;
BA_REL_ "GenSigTimeoutTime" BU_SG_REL_ IC3 SG_ 2147485145 DiagFaultStat_GFHCM2_EcuAdr_ISig 6000;
BA_REL_ "GenSigFirstTimeoutTime" BU_SG_REL_ IC3 SG_ 2147485145 DiagFaultStat_GFHCM2_FailTB_ISig 24000;
BA_REL_ "GenSigTimeoutTime" BU_SG_REL_ IC3 SG_ 2147485145 DiagFaultStat_GFHCM2_FailTB_ISig 6000;
BA_REL_ "GenSigFirstTimeoutTime" BU_SG_REL_ IC3 SG_ 2147485144 DiagFaultStat_GFHCM1_DtcIdA_ISig 24000;
BA_REL_ "GenSigTimeoutTime" BU_SG_REL_ IC3 SG_ 2147485144 DiagFaultStat_GFHCM1_DtcIdA_ISig 6000;
BA_REL_ "GenSigFirstTimeoutTime" BU_SG_REL_ IC3 SG_ 2147485144 DiagFaultStat_GFHCM1_FailTB_ISig 24000;
BA_REL_ "GenSigTimeoutTime" BU_SG_REL_ IC3 SG_ 2147485144 DiagFaultStat_GFHCM1_FailTB_ISig 6000;
BA_REL_ "GenSigFirstTimeoutTime" BU_SG_REL_ IC3 SG_ 2147485144 DiagFaultStat_GFHCM1_FailTA_ISig 24000;
BA_REL_ "GenSigTimeoutTime" BU_SG_REL_ IC3 SG_ 2147485144 DiagFaultStat_GFHCM1_FailTA_ISig 6000;
BA_REL_ "GenSigFirstTimeoutTime" BU_SG_REL_ IC3 SG_ 2147485144 DiagFaultStat_GFHCM1_EcuAdr_ISig 24000;
BA_REL_ "GenSigTimeoutTime" BU_SG_REL_ IC3 SG_ 2147485144 DiagFaultStat_GFHCM1_EcuAdr_ISig 6000;
BA_REL_ "GenSigFirstTimeoutTime" BU_SG_REL_ IC3 SG_ 2147485144 DiagFaultStat_GFHCM1_DtcIdB_ISig 24000;
BA_REL_ "GenSigTimeoutTime" BU_SG_REL_ IC3 SG_ 2147485144 DiagFaultStat_GFHCM1_DtcIdB_ISig 6000;
BA_REL_ "GenSigFirstTimeoutTime" BU_SG_REL_ IC3 SG_ 2147485160 DiagFaultStat_FLS_DtcIdB_ISig_4 24000;
BA_REL_ "GenSigTimeoutTime" BU_SG_REL_ IC3 SG_ 2147485160 DiagFaultStat_FLS_DtcIdB_ISig_4 6000;
BA_REL_ "GenSigFirstTimeoutTime" BU_SG_REL_ IC3 SG_ 2147485160 DiagFaultStat_FLS_FailTB_ISig_4 24000;
BA_REL_ "GenSigTimeoutTime" BU_SG_REL_ IC3 SG_ 2147485160 DiagFaultStat_FLS_FailTB_ISig_4 6000;
BA_REL_ "GenSigFirstTimeoutTime" BU_SG_REL_ IC3 SG_ 2147485160 DiagFaultStat_FLS_DtcIdA_ISig_4 24000;
BA_REL_ "GenSigTimeoutTime" BU_SG_REL_ IC3 SG_ 2147485160 DiagFaultStat_FLS_DtcIdA_ISig_4 6000;
BA_REL_ "GenSigFirstTimeoutTime" BU_SG_REL_ IC3 SG_ 2147485160 DiagFaultStat_FLS_EcuAdr_ISig_4 24000;
BA_REL_ "GenSigTimeoutTime" BU_SG_REL_ IC3 SG_ 2147485160 DiagFaultStat_FLS_EcuAdr_ISig_4 6000;
BA_REL_ "GenSigFirstTimeoutTime" BU_SG_REL_ IC3 SG_ 2147485160 DiagFaultStat_FLS_FailTA_ISig_4 24000;
BA_REL_ "GenSigTimeoutTime" BU_SG_REL_ IC3 SG_ 2147485160 DiagFaultStat_FLS_FailTA_ISig_4 6000;
BA_REL_ "GenSigFirstTimeoutTime" BU_SG_REL_ IC3 SG_ 2147485147 DiagFaultStat_FCIOM_DtcIdB_ISig_ 24000;
BA_REL_ "GenSigTimeoutTime" BU_SG_REL_ IC3 SG_ 2147485147 DiagFaultStat_FCIOM_DtcIdB_ISig_ 6000;
BA_REL_ "GenSigFirstTimeoutTime" BU_SG_REL_ IC3 SG_ 2147485147 DiagFaultStat_FCIOM_FailTA_ISig_ 24000;
BA_REL_ "GenSigTimeoutTime" BU_SG_REL_ IC3 SG_ 2147485147 DiagFaultStat_FCIOM_FailTA_ISig_ 6000;
BA_REL_ "GenSigFirstTimeoutTime" BU_SG_REL_ IC3 SG_ 2147485147 DiagFaultStat_FCIOM_FailTB_ISig_ 24000;
BA_REL_ "GenSigTimeoutTime" BU_SG_REL_ IC3 SG_ 2147485147 DiagFaultStat_FCIOM_FailTB_ISig_ 6000;
BA_REL_ "GenSigFirstTimeoutTime" BU_SG_REL_ IC3 SG_ 2147485147 DiagFaultStat_FCIOM_EcuAdr_ISig_ 24000;
BA_REL_ "GenSigTimeoutTime" BU_SG_REL_ IC3 SG_ 2147485147 DiagFaultStat_FCIOM_EcuAdr_ISig_ 6000;
BA_REL_ "GenSigFirstTimeoutTime" BU_SG_REL_ IC3 SG_ 2147485147 DiagFaultStat_FCIOM_DtcIdA_ISig_ 24000;
BA_REL_ "GenSigTimeoutTime" BU_SG_REL_ IC3 SG_ 2147485147 DiagFaultStat_FCIOM_DtcIdA_ISig_ 6000;
BA_REL_ "GenSigFirstTimeoutTime" BU_SG_REL_ IC3 SG_ 2147485139 DiagFaultStat_FAS_FailTA_ISig_4 24000;
BA_REL_ "GenSigTimeoutTime" BU_SG_REL_ IC3 SG_ 2147485139 DiagFaultStat_FAS_FailTA_ISig_4 6000;
BA_REL_ "GenSigFirstTimeoutTime" BU_SG_REL_ IC3 SG_ 2147485139 DiagFaultStat_FAS_DtcIdA_ISig_4 24000;
BA_REL_ "GenSigTimeoutTime" BU_SG_REL_ IC3 SG_ 2147485139 DiagFaultStat_FAS_DtcIdA_ISig_4 6000;
BA_REL_ "GenSigFirstTimeoutTime" BU_SG_REL_ IC3 SG_ 2147485139 DiagFaultStat_FAS_FailTB_ISig_4 24000;
BA_REL_ "GenSigTimeoutTime" BU_SG_REL_ IC3 SG_ 2147485139 DiagFaultStat_FAS_FailTB_ISig_4 6000;
BA_REL_ "GenSigFirstTimeoutTime" BU_SG_REL_ IC3 SG_ 2147485139 DiagFaultStat_FAS_EcuAdr_ISig_4 24000;
BA_REL_ "GenSigTimeoutTime" BU_SG_REL_ IC3 SG_ 2147485139 DiagFaultStat_FAS_EcuAdr_ISig_4 6000;
BA_REL_ "GenSigFirstTimeoutTime" BU_SG_REL_ IC3 SG_ 2147485139 DiagFaultStat_FAS_DtcIdB_ISig_4 24000;
BA_REL_ "GenSigTimeoutTime" BU_SG_REL_ IC3 SG_ 2147485139 DiagFaultStat_FAS_DtcIdB_ISig_4 6000;
BA_REL_ "GenSigFirstTimeoutTime" BU_SG_REL_ IC3 SG_ 2147485159 DiagFaultStat_EMS_EcuAdr_ISig_4 24000;
BA_REL_ "GenSigTimeoutTime" BU_SG_REL_ IC3 SG_ 2147485159 DiagFaultStat_EMS_EcuAdr_ISig_4 6000;
BA_REL_ "GenSigFirstTimeoutTime" BU_SG_REL_ IC3 SG_ 2147485159 DiagFaultStat_EMS_DtcIdB_ISig_4 24000;
BA_REL_ "GenSigTimeoutTime" BU_SG_REL_ IC3 SG_ 2147485159 DiagFaultStat_EMS_DtcIdB_ISig_4 6000;
BA_REL_ "GenSigFirstTimeoutTime" BU_SG_REL_ IC3 SG_ 2147485159 DiagFaultStat_EMS_DtcIdA_ISig_4 24000;
BA_REL_ "GenSigTimeoutTime" BU_SG_REL_ IC3 SG_ 2147485159 DiagFaultStat_EMS_DtcIdA_ISig_4 6000;
BA_REL_ "GenSigFirstTimeoutTime" BU_SG_REL_ IC3 SG_ 2147485159 DiagFaultStat_EMS_FailTB_ISig_4 24000;
BA_REL_ "GenSigTimeoutTime" BU_SG_REL_ IC3 SG_ 2147485159 DiagFaultStat_EMS_FailTB_ISig_4 6000;
BA_REL_ "GenSigFirstTimeoutTime" BU_SG_REL_ IC3 SG_ 2147485159 DiagFaultStat_EMS_FailTA_ISig_4 24000;
BA_REL_ "GenSigTimeoutTime" BU_SG_REL_ IC3 SG_ 2147485159 DiagFaultStat_EMS_FailTA_ISig_4 6000;
BA_REL_ "GenSigFirstTimeoutTime" BU_SG_REL_ IC3 SG_ 2147485141 DiagFaultStat_EAS_DtcIdB_ISig_4 24000;
BA_REL_ "GenSigTimeoutTime" BU_SG_REL_ IC3 SG_ 2147485141 DiagFaultStat_EAS_DtcIdB_ISig_4 6000;
BA_REL_ "GenSigFirstTimeoutTime" BU_SG_REL_ IC3 SG_ 2147485141 DiagFaultStat_EAS_DtcIdA_ISig_4 24000;
BA_REL_ "GenSigTimeoutTime" BU_SG_REL_ IC3 SG_ 2147485141 DiagFaultStat_EAS_DtcIdA_ISig_4 6000;
BA_REL_ "GenSigFirstTimeoutTime" BU_SG_REL_ IC3 SG_ 2147485141 DiagFaultStat_EAS_FailTB_ISig_4 24000;
BA_REL_ "GenSigTimeoutTime" BU_SG_REL_ IC3 SG_ 2147485141 DiagFaultStat_EAS_FailTB_ISig_4 6000;
BA_REL_ "GenSigFirstTimeoutTime" BU_SG_REL_ IC3 SG_ 2147485141 DiagFaultStat_EAS_FailTA_ISig_4 24000;
BA_REL_ "GenSigTimeoutTime" BU_SG_REL_ IC3 SG_ 2147485141 DiagFaultStat_EAS_FailTA_ISig_4 6000;
BA_REL_ "GenSigFirstTimeoutTime" BU_SG_REL_ IC3 SG_ 2147485141 DiagFaultStat_EAS_EcuAdr_ISig_4 24000;
BA_REL_ "GenSigTimeoutTime" BU_SG_REL_ IC3 SG_ 2147485141 DiagFaultStat_EAS_EcuAdr_ISig_4 6000;
BA_REL_ "GenSigFirstTimeoutTime" BU_SG_REL_ IC3 SG_ 2147485158 DiagFaultStat_DDM_DtcIdA_ISig_4 24000;
BA_REL_ "GenSigTimeoutTime" BU_SG_REL_ IC3 SG_ 2147485158 DiagFaultStat_DDM_DtcIdA_ISig_4 6000;
BA_REL_ "GenSigFirstTimeoutTime" BU_SG_REL_ IC3 SG_ 2147485158 DiagFaultStat_DDM_FailTA_ISig_4 24000;
BA_REL_ "GenSigTimeoutTime" BU_SG_REL_ IC3 SG_ 2147485158 DiagFaultStat_DDM_FailTA_ISig_4 6000;
BA_REL_ "GenSigFirstTimeoutTime" BU_SG_REL_ IC3 SG_ 2147485158 DiagFaultStat_DDM_EcuAdr_ISig_4 24000;
BA_REL_ "GenSigTimeoutTime" BU_SG_REL_ IC3 SG_ 2147485158 DiagFaultStat_DDM_EcuAdr_ISig_4 6000;
BA_REL_ "GenSigFirstTimeoutTime" BU_SG_REL_ IC3 SG_ 2147485158 DiagFaultStat_DDM_FailTB_ISig_4 24000;
BA_REL_ "GenSigTimeoutTime" BU_SG_REL_ IC3 SG_ 2147485158 DiagFaultStat_DDM_FailTB_ISig_4 6000;
BA_REL_ "GenSigFirstTimeoutTime" BU_SG_REL_ IC3 SG_ 2147485158 DiagFaultStat_DDM_DtcIdB_ISig_4 24000;
BA_REL_ "GenSigTimeoutTime" BU_SG_REL_ IC3 SG_ 2147485158 DiagFaultStat_DDM_DtcIdB_ISig_4 6000;
BA_REL_ "GenSigFirstTimeoutTime" BU_SG_REL_ IC3 SG_ 2147485157 DiagFaultStat_DACU_DtcIdB_ISig_4 24000;
BA_REL_ "GenSigTimeoutTime" BU_SG_REL_ IC3 SG_ 2147485157 DiagFaultStat_DACU_DtcIdB_ISig_4 6000;
BA_REL_ "GenSigFirstTimeoutTime" BU_SG_REL_ IC3 SG_ 2147485157 DiagFaultStat_DACU_DtcIdA_ISig_4 24000;
BA_REL_ "GenSigTimeoutTime" BU_SG_REL_ IC3 SG_ 2147485157 DiagFaultStat_DACU_DtcIdA_ISig_4 6000;
BA_REL_ "GenSigFirstTimeoutTime" BU_SG_REL_ IC3 SG_ 2147485157 DiagFaultStat_DACU_EcuAdr_ISig_4 24000;
BA_REL_ "GenSigTimeoutTime" BU_SG_REL_ IC3 SG_ 2147485157 DiagFaultStat_DACU_EcuAdr_ISig_4 6000;
BA_REL_ "GenSigFirstTimeoutTime" BU_SG_REL_ IC3 SG_ 2147485157 DiagFaultStat_DACU_FailTB_ISig_4 24000;
BA_REL_ "GenSigTimeoutTime" BU_SG_REL_ IC3 SG_ 2147485157 DiagFaultStat_DACU_FailTB_ISig_4 6000;
BA_REL_ "GenSigFirstTimeoutTime" BU_SG_REL_ IC3 SG_ 2147485157 DiagFaultStat_DACU_FailTA_ISig_4 24000;
BA_REL_ "GenSigTimeoutTime" BU_SG_REL_ IC3 SG_ 2147485157 DiagFaultStat_DACU_FailTA_ISig_4 6000;
BA_REL_ "GenSigFirstTimeoutTime" BU_SG_REL_ IC3 SG_ 2147485156 DiagFaultStat_CIOM_DtcIdA_ISig_4 24000;
BA_REL_ "GenSigTimeoutTime" BU_SG_REL_ IC3 SG_ 2147485156 DiagFaultStat_CIOM_DtcIdA_ISig_4 6000;
BA_REL_ "GenSigFirstTimeoutTime" BU_SG_REL_ IC3 SG_ 2147485156 DiagFaultStat_CIOM_EcuAdr_ISig_4 24000;
BA_REL_ "GenSigTimeoutTime" BU_SG_REL_ IC3 SG_ 2147485156 DiagFaultStat_CIOM_EcuAdr_ISig_4 6000;
BA_REL_ "GenSigFirstTimeoutTime" BU_SG_REL_ IC3 SG_ 2147485156 DiagFaultStat_CIOM_DtcIdB_ISig_4 24000;
BA_REL_ "GenSigTimeoutTime" BU_SG_REL_ IC3 SG_ 2147485156 DiagFaultStat_CIOM_DtcIdB_ISig_4 6000;
BA_REL_ "GenSigFirstTimeoutTime" BU_SG_REL_ IC3 SG_ 2147485156 DiagFaultStat_CIOM_FailTA_ISig_4 24000;
BA_REL_ "GenSigTimeoutTime" BU_SG_REL_ IC3 SG_ 2147485156 DiagFaultStat_CIOM_FailTA_ISig_4 6000;
BA_REL_ "GenSigFirstTimeoutTime" BU_SG_REL_ IC3 SG_ 2147485156 DiagFaultStat_CIOM_FailTB_ISig_4 24000;
BA_REL_ "GenSigTimeoutTime" BU_SG_REL_ IC3 SG_ 2147485156 DiagFaultStat_CIOM_FailTB_ISig_4 6000;
BA_REL_ "GenSigFirstTimeoutTime" BU_SG_REL_ IC3 SG_ 2147485155 DiagFaultStat_CCM_FailTB_ISig_4 24000;
BA_REL_ "GenSigTimeoutTime" BU_SG_REL_ IC3 SG_ 2147485155 DiagFaultStat_CCM_FailTB_ISig_4 6000;
BA_REL_ "GenSigFirstTimeoutTime" BU_SG_REL_ IC3 SG_ 2147485155 DiagFaultStat_CCM_DtcIdA_ISig_4 24000;
BA_REL_ "GenSigTimeoutTime" BU_SG_REL_ IC3 SG_ 2147485155 DiagFaultStat_CCM_DtcIdA_ISig_4 6000;
BA_REL_ "GenSigFirstTimeoutTime" BU_SG_REL_ IC3 SG_ 2147485155 DiagFaultStat_CCM_DtcIdB_ISig_4 24000;
BA_REL_ "GenSigTimeoutTime" BU_SG_REL_ IC3 SG_ 2147485155 DiagFaultStat_CCM_DtcIdB_ISig_4 6000;
BA_REL_ "GenSigFirstTimeoutTime" BU_SG_REL_ IC3 SG_ 2147485155 DiagFaultStat_CCM_EcuAdr_ISig_4 24000;
BA_REL_ "GenSigTimeoutTime" BU_SG_REL_ IC3 SG_ 2147485155 DiagFaultStat_CCM_EcuAdr_ISig_4 6000;
BA_REL_ "GenSigFirstTimeoutTime" BU_SG_REL_ IC3 SG_ 2147485155 DiagFaultStat_CCM_FailTA_ISig_4 24000;
BA_REL_ "GenSigTimeoutTime" BU_SG_REL_ IC3 SG_ 2147485155 DiagFaultStat_CCM_FailTA_ISig_4 6000;
BA_REL_ "GenSigFirstTimeoutTime" BU_SG_REL_ IC3 SG_ 2147485138 DiagFaultStat_CCIOM_EcuAdr_ISig_ 24000;
BA_REL_ "GenSigTimeoutTime" BU_SG_REL_ IC3 SG_ 2147485138 DiagFaultStat_CCIOM_EcuAdr_ISig_ 6000;
BA_REL_ "GenSigFirstTimeoutTime" BU_SG_REL_ IC3 SG_ 2147485138 DiagFaultStat_CCIOM_FailTA_ISig_ 24000;
BA_REL_ "GenSigTimeoutTime" BU_SG_REL_ IC3 SG_ 2147485138 DiagFaultStat_CCIOM_FailTA_ISig_ 6000;
BA_REL_ "GenSigFirstTimeoutTime" BU_SG_REL_ IC3 SG_ 2147485138 DiagFaultStat_CCIOM_DtcIdB_ISig_ 24000;
BA_REL_ "GenSigTimeoutTime" BU_SG_REL_ IC3 SG_ 2147485138 DiagFaultStat_CCIOM_DtcIdB_ISig_ 6000;
BA_REL_ "GenSigFirstTimeoutTime" BU_SG_REL_ IC3 SG_ 2147485138 DiagFaultStat_CCIOM_DtcIdA_ISig_ 24000;
BA_REL_ "GenSigTimeoutTime" BU_SG_REL_ IC3 SG_ 2147485138 DiagFaultStat_CCIOM_DtcIdA_ISig_ 6000;
BA_REL_ "GenSigFirstTimeoutTime" BU_SG_REL_ IC3 SG_ 2147485138 DiagFaultStat_CCIOM_FailTB_ISig_ 24000;
BA_REL_ "GenSigTimeoutTime" BU_SG_REL_ IC3 SG_ 2147485138 DiagFaultStat_CCIOM_FailTB_ISig_ 6000;
BA_REL_ "GenSigFirstTimeoutTime" BU_SG_REL_ IC3 SG_ 2147485142 DiagFaultStat_BPMU_EcuAdr_ISig_4 24000;
BA_REL_ "GenSigTimeoutTime" BU_SG_REL_ IC3 SG_ 2147485142 DiagFaultStat_BPMU_EcuAdr_ISig_4 6000;
BA_REL_ "GenSigFirstTimeoutTime" BU_SG_REL_ IC3 SG_ 2147485142 DiagFaultStat_BPMU_DtcIdB_ISig_4 24000;
BA_REL_ "GenSigTimeoutTime" BU_SG_REL_ IC3 SG_ 2147485142 DiagFaultStat_BPMU_DtcIdB_ISig_4 6000;
BA_REL_ "GenSigFirstTimeoutTime" BU_SG_REL_ IC3 SG_ 2147485142 DiagFaultStat_BPMU_FailTB_ISig_4 24000;
BA_REL_ "GenSigTimeoutTime" BU_SG_REL_ IC3 SG_ 2147485142 DiagFaultStat_BPMU_FailTB_ISig_4 6000;
BA_REL_ "GenSigFirstTimeoutTime" BU_SG_REL_ IC3 SG_ 2147485142 DiagFaultStat_BPMU_FailTA_ISig_4 24000;
BA_REL_ "GenSigTimeoutTime" BU_SG_REL_ IC3 SG_ 2147485142 DiagFaultStat_BPMU_FailTA_ISig_4 6000;
BA_REL_ "GenSigFirstTimeoutTime" BU_SG_REL_ IC3 SG_ 2147485142 DiagFaultStat_BPMU_DtcIdA_ISig_4 24000;
BA_REL_ "GenSigTimeoutTime" BU_SG_REL_ IC3 SG_ 2147485142 DiagFaultStat_BPMU_DtcIdA_ISig_4 6000;
BA_REL_ "GenSigFirstTimeoutTime" BU_SG_REL_ IC3 SG_ 2147485154 DiagFaultStat_BBM_EcuAdr_ISig_4 24000;
BA_REL_ "GenSigTimeoutTime" BU_SG_REL_ IC3 SG_ 2147485154 DiagFaultStat_BBM_EcuAdr_ISig_4 6000;
BA_REL_ "GenSigFirstTimeoutTime" BU_SG_REL_ IC3 SG_ 2147485154 DiagFaultStat_BBM_DtcIdB_ISig_4 24000;
BA_REL_ "GenSigTimeoutTime" BU_SG_REL_ IC3 SG_ 2147485154 DiagFaultStat_BBM_DtcIdB_ISig_4 6000;
BA_REL_ "GenSigFirstTimeoutTime" BU_SG_REL_ IC3 SG_ 2147485154 DiagFaultStat_BBM_FailTB_ISig_4 24000;
BA_REL_ "GenSigTimeoutTime" BU_SG_REL_ IC3 SG_ 2147485154 DiagFaultStat_BBM_FailTB_ISig_4 6000;
BA_REL_ "GenSigFirstTimeoutTime" BU_SG_REL_ IC3 SG_ 2147485154 DiagFaultStat_BBM_DtcIdA_ISig_4 24000;
BA_REL_ "GenSigTimeoutTime" BU_SG_REL_ IC3 SG_ 2147485154 DiagFaultStat_BBM_DtcIdA_ISig_4 6000;
BA_REL_ "GenSigFirstTimeoutTime" BU_SG_REL_ IC3 SG_ 2147485154 DiagFaultStat_BBM_FailTA_ISig_4 24000;
BA_REL_ "GenSigTimeoutTime" BU_SG_REL_ IC3 SG_ 2147485154 DiagFaultStat_BBM_FailTA_ISig_4 6000;
BA_REL_ "GenSigFirstTimeoutTime" BU_SG_REL_ IC3 SG_ 2147485153 DiagFaultStat_BBIOM_FailTA_ISig_ 24000;
BA_REL_ "GenSigTimeoutTime" BU_SG_REL_ IC3 SG_ 2147485153 DiagFaultStat_BBIOM_FailTA_ISig_ 6000;
BA_REL_ "GenSigFirstTimeoutTime" BU_SG_REL_ IC3 SG_ 2147485153 DiagFaultStat_BBIOM_FailTB_ISig_ 24000;
BA_REL_ "GenSigTimeoutTime" BU_SG_REL_ IC3 SG_ 2147485153 DiagFaultStat_BBIOM_FailTB_ISig_ 6000;
BA_REL_ "GenSigFirstTimeoutTime" BU_SG_REL_ IC3 SG_ 2147485153 DiagFaultStat_BBIOM_DtcIdB_ISig_ 24000;
BA_REL_ "GenSigTimeoutTime" BU_SG_REL_ IC3 SG_ 2147485153 DiagFaultStat_BBIOM_DtcIdB_ISig_ 6000;
BA_REL_ "GenSigFirstTimeoutTime" BU_SG_REL_ IC3 SG_ 2147485153 DiagFaultStat_BBIOM_DtcIdA_ISig_ 24000;
BA_REL_ "GenSigTimeoutTime" BU_SG_REL_ IC3 SG_ 2147485153 DiagFaultStat_BBIOM_DtcIdA_ISig_ 6000;
BA_REL_ "GenSigFirstTimeoutTime" BU_SG_REL_ IC3 SG_ 2147485153 DiagFaultStat_BBIOM_EcuAdr_ISig_ 24000;
BA_REL_ "GenSigTimeoutTime" BU_SG_REL_ IC3 SG_ 2147485153 DiagFaultStat_BBIOM_EcuAdr_ISig_ 6000;
VAL_ 2147485039 OilPrediction_Quality 7 "OilQuality_NotAvailable" 6 "OilQuality_Error" 5 "OilQuality_NoSelectionMade" 4 "OilQuality_VDS4" 3 "OilQuality_VDS3" 2 "OilQuality_VDS2" 1 "OilQuality_VDSVDS3WithFixedInterval" 0 "OilQuality_NonVDS_VDS4WithFixedInterval" ;
VAL_ 2147485039 OilPrediction_Status 7 "OilStatus_NotAvailable" 6 "OilStatus_Error" 5 "OilStatus_Spare" 4 "OilStatus_Ok" 3 "OilStatus_ServiceNearDue" 2 "OilStatus_ServiceDue" 1 "OilStatus_ServiceOverDue" 0 "OilStatus_NotActive" ;
VAL_ 2147484924 DMSDriverFollow 3 "DMSDriverFollow_NotAvailable" 2 "DMSDriverFollow_Error" 1 "DMSDriverFollow_AdviseFollowed" 0 "DMSDriverFollow_AdviseNotFollowed" ;
VAL_ 2147484924 FuelEcoEngStatus 3 "InactiveActive_NotAvailable" 2 "InactiveActive_Error" 1 "InactiveActive_Active" 0 "InactiveActive_Inactive" ;
VAL_ 2147484939 DrainPrimingStatus 7 "DrainPrimingStatus_NotAvailable" 6 "DrainPrimingStatus_Error" 5 "DrainPrimingStatus_SpareValue_01" 4 "DrainPrimingStatus_SpareValue" 3 "DrainPrimingStatus_DrainingActive" 2 "DrainPrimingStatus_PrimingActive" 1 "DrainPrimingStatus_DrainingPrimingNotAllowed" 0 "DrainPrimingStatus_DrainingPrimingInactive" ;
VAL_ 2147484939 CoolantTempHigh_ISig_4 7 "TempHigh3bit_NotAvailable" 6 "TempHigh3bit_Error" 5 "TempHigh3bit_HighLevel5" 4 "TempHigh3bit_HighLevel4" 3 "TempHigh3bit_HighLevel3" 2 "TempHigh3bit_HighLevel2" 1 "TempHigh3bit_HighLevel1" 0 "TempHigh3bit_OK" ;
VAL_ 2147484939 CoolantLevelLow_ISig_4 7 "LevelLow3bit_NotAvailable" 6 "LevelLow3bit_Error" 5 "LevelLow3bit_LowLevel5" 4 "LevelLow3bit_LowLevel4" 3 "LevelLow3bit_LowLevel3" 2 "LevelLow3bit_LowLevel2" 1 "LevelLow3bit_LowLevel1" 0 "LevelLow3bit_OK" ;
VAL_ 2147484939 AutoWheelBrakesStatus 7 "CCWheelBrkActBySyst_NotAvailable" 6 "CCWheelBrkActBySyst_Error" 5 "CCWheelBrkActBySyst_Spare3" 4 "CCWheelBrkActBySyst_Spare2" 3 "CCWheelBrkActBySyst_Spare1" 2 "CCWheelBrkActBySyst_ReducedAutoBraking_WithoutSerBrkDemand" 1 "CCWheelBrkActBySyst_FullAutoBraking_withSerBrksDemand" 0 "CCWheelBrkActBySyst_NoAutoBrakingActive" ;
VAL_ 2147484939 OilPressureLow_ISig_4 7 "LevelLow3bit_NotAvailable" 6 "LevelLow3bit_Error" 5 "LevelLow3bit_LowLevel5" 4 "LevelLow3bit_LowLevel4" 3 "LevelLow3bit_LowLevel3" 2 "LevelLow3bit_LowLevel2" 1 "LevelLow3bit_LowLevel1" 0 "LevelLow3bit_OK" ;
VAL_ 2147484939 TopGearMode_ISig_4 3 "TopGearMode_NotAvailable" 2 "TopGearMode_Error" 1 "TopGearMode_Active" 0 "TopGearMode_NotActive" ;
VAL_ 2147484939 OilLevelLow_ISig_4 7 "LevelLow3bit_NotAvailable" 6 "LevelLow3bit_Error" 5 "LevelLow3bit_LowLevel5" 4 "LevelLow3bit_LowLevel4" 3 "LevelLow3bit_LowLevel3" 2 "LevelLow3bit_LowLevel2" 1 "LevelLow3bit_LowLevel1" 0 "LevelLow3bit_OK" ;
VAL_ 2147484939 InletAirHeaterStatus1 3 "OffOn_NotAvailable" 2 "OffOn_Error" 1 "OffOn_On" 0 "OffOn_Off" ;
VAL_ 2147484927 FuelFilterClogged 7 "LevelLow3bit_NotAvailable" 6 "LevelLow3bit_Error" 5 "LevelLow3bit_LowLevel5" 4 "LevelLow3bit_LowLevel4" 3 "LevelLow3bit_LowLevel3" 2 "LevelLow3bit_LowLevel2" 1 "LevelLow3bit_LowLevel1" 0 "LevelLow3bit_OK" ;
VAL_ 2147484927 EngineFanOverspeed 3 "NoYes_NotAvailable" 2 "NoYes_Error" 1 "NoYes_Yes" 0 "NoYes_No" ;
VAL_ 2147484927 EngineProtDerateStat 3 "InactiveActive_NotAvailable" 2 "InactiveActive_Error" 1 "InactiveActive_Active" 0 "InactiveActive_Inactive" ;
VAL_ 2147484927 AirFilterPressureDrop 7 "AirFilterPressureDrop_NotAvailable" 6 "AirFilterPressureDrop_Error" 5 "AirFilterPressureDrop_AirFilterPressureDropLevel5" 4 "AirFilterPressureDrop_AirFilterPressureDropLevel4" 3 "AirFilterPressureDrop_AirFilterPressureDropLevel3" 2 "AirFilterPressureDrop_AirFilterPressureDropLevel2" 1 "AirFilterPressureDrop_AirFilterPressureDropLevel1" 0 "AirFilterPressureDrop_OK" ;
VAL_ 2147484381 DPF_LimitedSpeedDuetoInhibit 7 "LimitedSpeedInhibit_NotAvailable" 6 "LimitedSpeedInhibit_Error" 5 "LimitedSpeedInhibit_Spare2" 4 "LimitedSpeedInhibit_Spare1" 3 "LimitedSpeedInhibit_SpeedNotLimited_InhibitActive" 2 "LimitedSpeedInhibit_SpeedNotLimited_InhibitDenied" 1 "LimitedSpeedInhibit_SpeedLimited_InhibitionActive" 0 "LimitedSpeedInhibit_SpeedNotLimited_NoInhibitRequest" ;
VAL_ 2147484381 XARSystemState 3 "XARSystemState_NotAvailable" 2 "XARSystemState_Error" 1 "XARSystemState_NoExternalAccelerationDemandWillBeAccepted" 0 "XARSystemState_AnyExternalAccelerationDemandWillBeAccepted" ;
VAL_ 2147484381 XARActiveControlMode 7 "XARActiveControlMode_NotAvailable" 6 "XARActiveControlMode_Error" 5 "XARActiveControlMode_Spare_2" 4 "XARActiveControlMode_Spare_1" 3 "XARActiveControlMode_CoastingActive" 2 "XARActiveControlMode_DriversAccelerationDemandExecuted" 1 "XARActiveControlMode_AccelerationControlMaximumMode" 0 "XARActiveControlMode_OverrideDisabled" ;
VAL_ 2147484367 CCControllerMode_ISig_4 7 "ControllerMode_Not_availbale" 6 "ControllerMode_Error" 5 "ControllerMode_Spare_01" 4 "ControllerMode_Spare" 3 "ControllerMode_Inhibited" 2 "ControllerMode_Active_no_torque" 1 "ControllerMode_Active_torque" 0 "ControllerMode_Inactive" ;
VAL_ 2147484367 CrankcasePressureHigh_ISig_4 3 "Warning_NotAvailable" 2 "Warning_Error" 1 "Warning_Warning" 0 "Warning_NoWarning" ;
VAL_ 2147484367 EngineSystemPowerDownAck 3 "EngineSystemPowerDownAck_NotAvailable" 2 "EngineSystemPowerDownAck_Error" 1 "EngineSystemPowerDownAck_NotOkToPowerDownEMS" 0 "EngineSystemPowerDownAck_OkToPowerDownEMS" ;
VAL_ 2147484367 EngineActiveStatus_ISig_4 15 "EngineActiveStatus_NotAvailable" 14 "EngineActiveStatus_Error" 13 "EngineActiveStatus_Spare_10" 12 "EngineActiveStatus_Spare_09" 11 "EngineActiveStatus_Spare_08" 10 "EngineActiveStatus_Spare_07" 9 "EngineActiveStatus_Spare_06" 8 "EngineActiveStatus_Spare_05" 7 "EngineActiveStatus_Spare_04" 6 "EngineActiveStatus_Spare_03" 5 "EngineActiveStatus_Spare_02" 4 "EngineActiveStatus_Spare_01" 3 "EngineActiveStatus_Spare" 2 "EngineActiveStatus_ElectricPropulsionSystemRunning" 1 "EngineActiveStatus_InternalCombustionEngineRunning" 0 "EngineActiveStatus_DrivelineNotActive" ;
VAL_ 2147484367 XRSLControllerMode 3 "InactiveActive_NotAvailable" 2 "InactiveActive_Error" 1 "InactiveActive_Active" 0 "InactiveActive_Inactive" ;
VAL_ 2147484367 RegenInhibDueHeight 3 "Inhibit_NotAvailable" 2 "Inhibit_Error" 1 "Inhibit_InhibitActive" 0 "Inhibit_NoInhibit" ;
VAL_ 2147484367 ExhManif_AirInjActive_ISig_4 3 "InhibitedStatus_NotAvailable" 2 "InhibitedStatus_Error" 1 "InhibitedStatus_Inhibited" 0 "InhibitedStatus_NotInhibited" ;
VAL_ 2147484367 CCBControllerMode 7 "ControllerMode_Not_availbale" 6 "ControllerMode_Error" 5 "ControllerMode_Spare_01" 4 "ControllerMode_Spare" 3 "ControllerMode_Inhibited" 2 "ControllerMode_Active_no_torque" 1 "ControllerMode_Active_torque" 0 "ControllerMode_Inactive" ;
VAL_ 2147484367 InhibitIdleShutdownStatus 7 "InhibitIdleShutdownStatus_NotAvailableNoInhibit" 6 "InhibitIdleShutdownStatus_ErrorIndicator" 5 "InhibitIdleShutdownStatus_InhibitReasonUndefined" 4 "InhibitIdleShutdownStatus_InhibitReasonReserved_02" 3 "InhibitIdleShutdownStatus_InhibitReasonReserved_01" 2 "InhibitIdleShutdownStatus_InhibitReasonReserved" 1 "InhibitIdleShutdownStatus_InhibitDPFRegeneration" 0 "InhibitIdleShutdownStatus_NoInhibit" ;
VAL_ 2147484367 EngCompartmentStopSwitchStat 3 "EngCompartmentStopSwitchStat_NotAvailable" 2 "EngCompartmentStopSwitchStat_Error" 1 "EngCompartmentStopSwitchStat_ShutdownRequested" 0 "EngCompartmentStopSwitchStat_NoAction" ;
VAL_ 2147484367 EngineStartAuth_rqst 7 "EngineStartAuth_rqst_NotAvailable" 6 "EngineStartAuth_rqst_Error" 5 "EngineStartAuth_rqst_Spare_03" 4 "EngineStartAuth_rqst_Spare_02" 3 "EngineStartAuth_rqst_Spare_01" 2 "EngineStartAuth_rqst_Spare" 1 "EngineStartAuth_rqst_StartingOfTheTruckRequested" 0 "EngineStartAuth_rqst_StartingOfTheTruckNotRequested" ;
VAL_ 2147484367 IntakeAirTemperatureAlert 3 "InactiveActive_NotAvailable" 2 "InactiveActive_Error" 1 "InactiveActive_Active" 0 "InactiveActive_Inactive" ;
VAL_ 2147484367 EngineOilTempHigh_ISig_4 7 "TempHigh3bit_NotAvailable" 6 "TempHigh3bit_Error" 5 "TempHigh3bit_HighLevel5" 4 "TempHigh3bit_HighLevel4" 3 "TempHigh3bit_HighLevel3" 2 "TempHigh3bit_HighLevel2" 1 "TempHigh3bit_HighLevel1" 0 "TempHigh3bit_OK" ;
VAL_ 2147484367 WarmUpCycle 3 "WarmUpCycle_NotAvailable" 2 "WarmUpCycle_Error" 1 "WarmUpCycle_TransitionTo1MeansWarmUpCycleOccur" 0 "WarmUpCycle_TransitionTo0MeansWarmUpCycleOccur" ;
SIG_GROUP_ 2147485039 OilPrediction_sg 1 : OilPrediction_Quality OilPrediction_RemainDist OilPrediction_RemainTime OilPrediction_Status;
SIG_GROUP_ 2147484381 AirFilter_sg 1 : AirFilter_AirMassFlowValidated AirFilter_Pressure;
SIG_GROUP_ 2147485168 DiagFaultStat_WRCS_sg_ISig_4 1 : DiagFaultStat_WRCS_EcuAdr_ISig_4 DiagFaultStat_WRCS_DtcIdB_ISig_4 DiagFaultStat_WRCS_FailTB_ISig_4 DiagFaultStat_WRCS_FailTA_ISig_4 DiagFaultStat_WRCS_DtcIdA_ISig_4;
SIG_GROUP_ 2147485136 DiagFaultStat_VMCU_sg_ISig_4 1 : DiagFaultStat_VMCU_DtcIdA_ISig_4 DiagFaultStat_VMCU_EcuAdr_ISig_4 DiagFaultStat_VMCU_FailTA_ISig_4 DiagFaultStat_VMCU_FailTB_ISig_4 DiagFaultStat_VMCU_DtcIdB_ISig_4;
SIG_GROUP_ 2147485150 DiagFaultStat_TPM_sg_ISig_4 1 : DiagFaultStat_TPM_EcuAdr_ISig_4 DiagFaultStat_TPM_FailTB_ISig_4 DiagFaultStat_TPM_DtcIdA_ISig_4 DiagFaultStat_TPM_DtcIdB_ISig_4 DiagFaultStat_TPM_FailTA_ISig_4;
SIG_GROUP_ 2147485167 DiagFaultStat_TECU_sg_ISig_4 1 : DiagFaultStat_TECU_FailTA_ISig_4 DiagFaultStat_TECU_FailTB_ISig_4 DiagFaultStat_TECU_DtcIdA_ISig_4 DiagFaultStat_TECU_EcuAdr_ISig_4 DiagFaultStat_TECU_DtcIdB_ISig_4;
SIG_GROUP_ 2147485165 DiagFaultStat_SRS_sg_ISig_4 1 : DiagFaultStat_SRS_DtcIdB_ISig_4 DiagFaultStat_SRS_FailTB_ISig_4 DiagFaultStat_SRS_EcuAdr_ISig_4 DiagFaultStat_SRS_DtcIdA_ISig_4 DiagFaultStat_SRS_FailTA_ISig_4;
SIG_GROUP_ 2147485164 DiagFaultStat_RCIOM_sg_ISig_4 1 : DiagFaultStat_RCIOM_FailTA_ISig_ DiagFaultStat_RCIOM_FailTB_ISig_ DiagFaultStat_RCIOM_DtcIdB_ISig_ DiagFaultStat_RCIOM_DtcIdA_ISig_ DiagFaultStat_RCIOM_EcuAdr_ISig_;
SIG_GROUP_ 2147485163 DiagFaultStat_PDM_sg_ISig_4 1 : DiagFaultStat_PDM_EcuAdr_ISig_4 DiagFaultStat_PDM_DtcIdB_ISig_4 DiagFaultStat_PDM_FailTB_ISig_4 DiagFaultStat_PDM_DtcIdA_ISig_4 DiagFaultStat_PDM_FailTA_ISig_4;
SIG_GROUP_ 2147485162 DiagFaultStat_LPOS_sg_ISig_4 1 : DiagFaultStat_LPOS_DtcIdB_ISig_4 DiagFaultStat_LPOS_FailTB_ISig_4 DiagFaultStat_LPOS_DtcIdA_ISig_4 DiagFaultStat_LPOS_FailTA_ISig_4 DiagFaultStat_LPOS_EcuAdr_ISig_4;
SIG_GROUP_ 2147485161 DiagFaultStat_LECM_sg_ISig_4 1 : DiagFaultStat_LECM_EcuAdr_ISig_4 DiagFaultStat_LECM_FailTB_ISig_4 DiagFaultStat_LECM_FailTA_ISig_4 DiagFaultStat_LECM_DtcIdB_ISig_4 DiagFaultStat_LECM_DtcIdA_ISig_4;
SIG_GROUP_ 2147485145 DiagFaultStat_GFHCM2_sg_ISig_4 1 : DiagFaultStat_GFHCM2_DtcIdB_ISig DiagFaultStat_GFHCM2_DtcIdA_ISig DiagFaultStat_GFHCM2_FailTA_ISig DiagFaultStat_GFHCM2_EcuAdr_ISig DiagFaultStat_GFHCM2_FailTB_ISig;
SIG_GROUP_ 2147485144 DiagFaultStat_GFHCM1_sg_ISig_4 1 : DiagFaultStat_GFHCM1_DtcIdA_ISig DiagFaultStat_GFHCM1_FailTB_ISig DiagFaultStat_GFHCM1_FailTA_ISig DiagFaultStat_GFHCM1_EcuAdr_ISig DiagFaultStat_GFHCM1_DtcIdB_ISig;
SIG_GROUP_ 2147485160 DiagFaultStat_FLS_sg_ISig_4 1 : DiagFaultStat_FLS_DtcIdB_ISig_4 DiagFaultStat_FLS_FailTB_ISig_4 DiagFaultStat_FLS_DtcIdA_ISig_4 DiagFaultStat_FLS_EcuAdr_ISig_4 DiagFaultStat_FLS_FailTA_ISig_4;
SIG_GROUP_ 2147485147 DiagFaultStat_FCIOM_sg_ISig_4 1 : DiagFaultStat_FCIOM_DtcIdB_ISig_ DiagFaultStat_FCIOM_FailTA_ISig_ DiagFaultStat_FCIOM_FailTB_ISig_ DiagFaultStat_FCIOM_EcuAdr_ISig_ DiagFaultStat_FCIOM_DtcIdA_ISig_;
SIG_GROUP_ 2147485139 DiagFaultStat_FAS_sg_ISig_4 1 : DiagFaultStat_FAS_FailTA_ISig_4 DiagFaultStat_FAS_DtcIdA_ISig_4 DiagFaultStat_FAS_FailTB_ISig_4 DiagFaultStat_FAS_EcuAdr_ISig_4 DiagFaultStat_FAS_DtcIdB_ISig_4;
SIG_GROUP_ 2147485159 DiagFaultStat_EMS_sg_ISig_4 1 : DiagFaultStat_EMS_EcuAdr_ISig_4 DiagFaultStat_EMS_DtcIdB_ISig_4 DiagFaultStat_EMS_DtcIdA_ISig_4 DiagFaultStat_EMS_FailTB_ISig_4 DiagFaultStat_EMS_FailTA_ISig_4;
SIG_GROUP_ 2147485141 DiagFaultStat_EAS_sg_ISig_4 1 : DiagFaultStat_EAS_DtcIdB_ISig_4 DiagFaultStat_EAS_DtcIdA_ISig_4 DiagFaultStat_EAS_FailTB_ISig_4 DiagFaultStat_EAS_FailTA_ISig_4 DiagFaultStat_EAS_EcuAdr_ISig_4;
SIG_GROUP_ 2147485158 DiagFaultStat_DDM_sg_ISig_4 1 : DiagFaultStat_DDM_DtcIdA_ISig_4 DiagFaultStat_DDM_FailTA_ISig_4 DiagFaultStat_DDM_EcuAdr_ISig_4 DiagFaultStat_DDM_FailTB_ISig_4 DiagFaultStat_DDM_DtcIdB_ISig_4;
SIG_GROUP_ 2147485157 DiagFaultStat_DACU_sg_ISig_4 1 : DiagFaultStat_DACU_DtcIdB_ISig_4 DiagFaultStat_DACU_DtcIdA_ISig_4 DiagFaultStat_DACU_EcuAdr_ISig_4 DiagFaultStat_DACU_FailTB_ISig_4 DiagFaultStat_DACU_FailTA_ISig_4;
SIG_GROUP_ 2147485156 DiagFaultStat_CIOM_sg_ISig_4 1 : DiagFaultStat_CIOM_DtcIdA_ISig_4 DiagFaultStat_CIOM_EcuAdr_ISig_4 DiagFaultStat_CIOM_DtcIdB_ISig_4 DiagFaultStat_CIOM_FailTA_ISig_4 DiagFaultStat_CIOM_FailTB_ISig_4;
SIG_GROUP_ 2147485155 DiagFaultStat_CCM_sg_ISig_4 1 : DiagFaultStat_CCM_FailTB_ISig_4 DiagFaultStat_CCM_DtcIdA_ISig_4 DiagFaultStat_CCM_DtcIdB_ISig_4 DiagFaultStat_CCM_EcuAdr_ISig_4 DiagFaultStat_CCM_FailTA_ISig_4;
SIG_GROUP_ 2147485138 DiagFaultStat_CCIOM_sg_ISig_4 1 : DiagFaultStat_CCIOM_EcuAdr_ISig_ DiagFaultStat_CCIOM_FailTA_ISig_ DiagFaultStat_CCIOM_DtcIdB_ISig_ DiagFaultStat_CCIOM_DtcIdA_ISig_ DiagFaultStat_CCIOM_FailTB_ISig_;
SIG_GROUP_ 2147485142 DiagFaultStat_BPMU_sg_ISig_4 1 : DiagFaultStat_BPMU_EcuAdr_ISig_4 DiagFaultStat_BPMU_DtcIdB_ISig_4 DiagFaultStat_BPMU_FailTB_ISig_4 DiagFaultStat_BPMU_FailTA_ISig_4 DiagFaultStat_BPMU_DtcIdA_ISig_4;
SIG_GROUP_ 2147485154 DiagFaultStat_BBM_sg_ISig_4 1 : DiagFaultStat_BBM_EcuAdr_ISig_4 DiagFaultStat_BBM_DtcIdB_ISig_4 DiagFaultStat_BBM_FailTB_ISig_4 DiagFaultStat_BBM_DtcIdA_ISig_4 DiagFaultStat_BBM_FailTA_ISig_4;
SIG_GROUP_ 2147485153 DiagFaultStat_BBIOM_sg_ISig_4 1 : DiagFaultStat_BBIOM_FailTA_ISig_ DiagFaultStat_BBIOM_FailTB_ISig_ DiagFaultStat_BBIOM_DtcIdB_ISig_ DiagFaultStat_BBIOM_DtcIdA_ISig_ DiagFaultStat_BBIOM_EcuAdr_ISig_;
